VERSION ""

NS_ :

BS_:

BU_: SCM BC1 BC2 ECM PSC ABS Brakes__Drive_Axle_1 EPS IC GPS WCM VCM Seat_Control_1 ISC1 HCU IDT GMRS XM RH AUTON LHC CIM IMU BC3 IC2 EPC1 EPC2 EPC3 EPC4 BMC1 BMC2 APU2 APU1 SRVTOOL RHC RCM

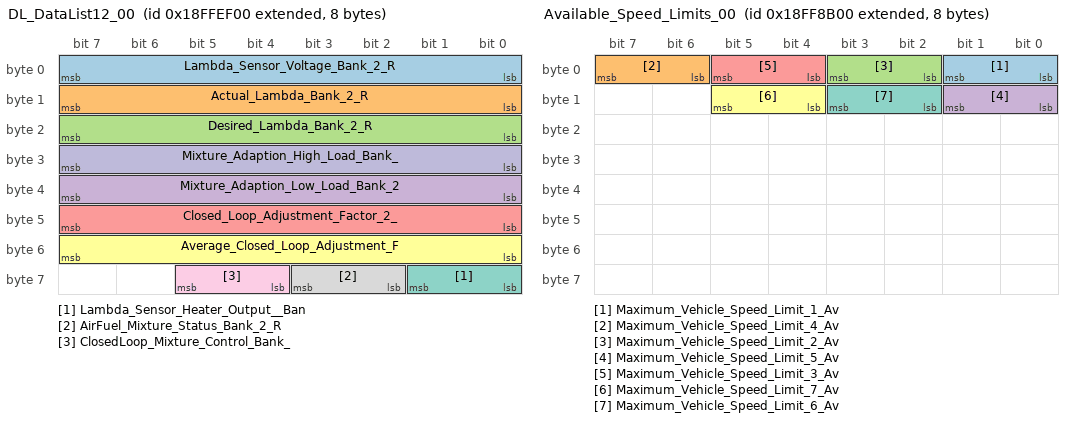
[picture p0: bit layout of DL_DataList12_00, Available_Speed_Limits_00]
BO_ 2566909696 DL_DataList12_00: 8 ECM
 SG_ Lambda_Sensor_Voltage_Bank_2_R : 0|8@1+ (0.02,0) [0|4.12] "V" Vector__XXX
 SG_ Actual_Lambda_Bank_2_R : 8|8@1+ (0.0078125,0) [0|1] "Ratio" Vector__XXX
 SG_ Desired_Lambda_Bank_2_R : 16|8@1+ (0.0078125,0) [0|1] "Ratio" Vector__XXX
 SG_ Mixture_Adaption_Low_Load_Bank_2 : 32|8@1+ (0.078,-10) [-10|28.968] "%" Vector__XXX
 SG_ Closed_Loop_Adjustment_Factor_2_ : 40|8@1+ (0.0078125,0) [0|1] "Ratio" Vector__XXX
 SG_ Average_Closed_Loop_Adjustment_F : 48|8@1+ (0.0078125,0) [0|1] "Ratio" Vector__XXX
 SG_ Lambda_Sensor_Heater_Output__Ban : 56|2@1+ (0,0) [0|-1] "state" Vector__XXX
 SG_ AirFuel_Mixture_Status_Bank_2_R : 58|2@1+ (0,0) [0|-1] "state" Vector__XXX
 SG_ ClosedLoop_Mixture_Control_Bank_ : 60|2@1+ (0,0) [0|-1] "state" Vector__XXX
 SG_ Mixture_Adaption_High_Load_Bank_ : 24|8@1+ (0.0078125,0) [0|1] "unknown" Vector__XXX

BO_ 2566884096 Available_Speed_Limits_00: 8 ECM
 SG_ Maximum_Vehicle_Speed_Limit_1_Av : 0|2@1+ (1,0) [0|3] "state" Vector__XXX
 SG_ Maximum_Vehicle_Speed_Limit_4_Av : 6|2@1+ (1,0) [0|3] "state" Vector__XXX
 SG_ Maximum_Vehicle_Speed_Limit_2_Av : 2|2@1+ (1,0) [0|3] "state" Vector__XXX
 SG_ Maximum_Vehicle_Speed_Limit_5_Av : 8|2@1+ (1,0) [0|3] "state" Vector__XXX
 SG_ Maximum_Vehicle_Speed_Limit_3_Av : 4|2@1+ (1,0) [0|3] "state" Vector__XXX
 SG_ Maximum_Vehicle_Speed_Limit_7_Av : 12|2@1+ (1,0) [0|3] "state" Vector__XXX
 SG_ Maximum_Vehicle_Speed_Limit_6_Av : 10|2@1+ (1,0) [0|3] "state" Vector__XXX

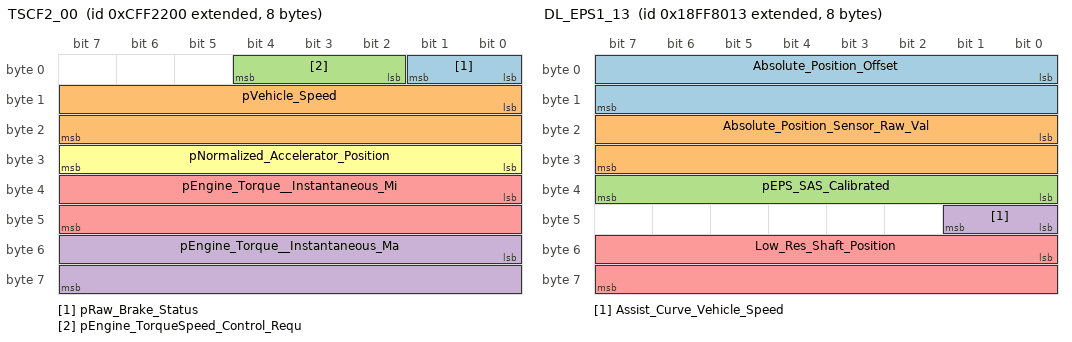
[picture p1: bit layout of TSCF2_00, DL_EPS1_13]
BO_ 2365530624 TSCF2_00: 8 ECM
 SG_ pRaw_Brake_Status : 0|2@1+ (1,0) [0|3] "state" Vector__XXX
 SG_ pVehicle_Speed : 8|16@1+ (0.00390625,0) [0|255] "km/h" Vector__XXX
 SG_ pEngine_TorqueSpeed_Control_Requ : 2|3@1+ (1,0) [0|7] "state" Vector__XXX
 SG_ pEngine_Torque__Instantaneous_Ma : 48|16@1+ (0.03125,-400) [-400|2447] "Nm" Vector__XXX
 SG_ pEngine_Torque__Instantaneous_Mi : 32|16@1+ (0.03125,-400) [-400|2447] "Nm" Vector__XXX
 SG_ pNormalized_Accelerator_Position : 24|8@1+ (0.4,0) [0|101.4] "%" Vector__XXX

BO_ 2566881811 DL_EPS2_13: 5 EPS
 SG_ EPS_Motor_Commanded_Current : 0|16@1+ (3.814697266,0) [0|249999.000024576] "A" Vector__XXX
 SG_ pEPS_Temp : 16|8@1+ (1,0) [0|255] "deg" Vector__XXX
 SG_ Factory_Absolute_Position_Offset : 24|16@1+ (0.1,-3276.5) [-3276.5|9829.1] "deg" Vector__XXX

BO_ 2566881299 DL_EPS1_13: 8 EPS
 SG_ Absolute_Position_Offset : 0|16@1+ (0.1,0) [0|6552.6] "deg" Vector__XXX
 SG_ Absolute_Position_Sensor_Raw_Val : 16|16@1+ (0.1,0) [0|6552.6] "deg" Vector__XXX
 SG_ pEPS_SAS_Calibrated : 32|8@1+ (4,0) [0|1023] "state" Vector__XXX
 SG_ Assist_Curve_Vehicle_Speed : 40|2@1+ (1,0) [0|3] "km/h" Vector__XXX
 SG_ Low_Res_Shaft_Position : 48|16@1+ (0.1,0) [0|6552.6] "deg" Vector__XXX

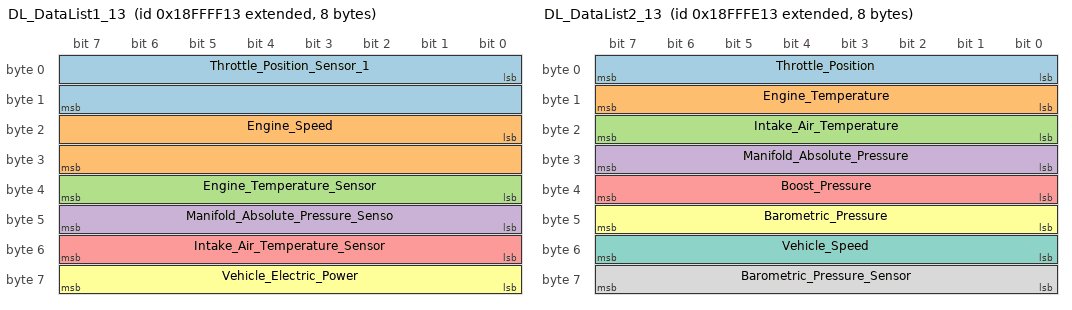
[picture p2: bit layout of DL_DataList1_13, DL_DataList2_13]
BO_ 2566913811 DL_DataList1_13: 8 EPS
 SG_ Throttle_Position_Sensor_1 : 0|16@1+ (0.01,0) [0|654.36] "V" Vector__XXX
 SG_ Engine_Speed : 16|16@1+ (1,0) [0|65535] "rpm" Vector__XXX
 SG_ Engine_Temperature_Sensor : 32|8@1+ (0.025,0) [0|5.4] "V" Vector__XXX
 SG_ Manifold_Absolute_Pressure_Senso : 40|8@1+ (0.025,0) [0|5.4] "V" Vector__XXX
 SG_ Intake_Air_Temperature_Sensor : 48|8@1+ (0.025,0) [0|5.4] "V" Vector__XXX
 SG_ Vehicle_Electric_Power : 56|8@1+ (0.1,0) [0|24.6] "V" Vector__XXX

BO_ 2566882579 DL_EPS3_13: 8 EPS
 SG_ EPS_DC_Link_Voltage : 0|16@1+ (0.001,0) [0|64.536] "V" Vector__XXX
 SG_ Phase_A_Motor_Current : 16|16@1+ (3.814697266,0) [0|249999.000024576] "A" Vector__XXX
 SG_ Phase_B_Motor_Current : 32|16@1+ (3.814697266,0) [0|249999.000024576] "A" Vector__XXX
 SG_ Phase_C_Motor_Current : 48|16@1+ (3.814697266,0) [0|249999.000024576] "A" Vector__XXX

BO_ 2566913555 DL_DataList2_13: 8 EPS
 SG_ Throttle_Position : 0|8@1+ (0.4,0) [0|101.4] "%" Vector__XXX
 SG_ Engine_Temperature : 8|8@1+ (1,0) [0|255] "deg C" Vector__XXX
 SG_ Intake_Air_Temperature : 16|8@1+ (1,0) [0|255] "deg C" Vector__XXX
 SG_ Manifold_Absolute_Pressure : 24|8@1+ (2,0) [0|511] "kPa" Vector__XXX
 SG_ Boost_Pressure : 32|8@1+ (2,0) [0|511] "kPa" Vector__XXX
 SG_ Barometric_Pressure : 40|8@1+ (0.5,0) [0|127] "kPa" Vector__XXX
 SG_ Vehicle_Speed : 48|8@1+ (1,0) [0|255] "km/h" Vector__XXX
 SG_ Barometric_Pressure_Sensor : 56|8@1+ (0.025,0) [0|5.4] "V" Vector__XXX

BO_ 2164236829 Development_PGN_3_1D: 8 WCM

BO_ 2164238109 Development_PGN_8_1D: 8 WCM

BO_ 2164237597 Development_PGN_6_1D: 8 WCM

BO_ 2164236317 Development_PGN_1_1D: 8 WCM

BO_ 2566910493 FI_FlagItems4_1D: 8 WCM
 SG_ Hazard_Switch_Input : 0|2@1+ (1,0) [0|3] "state" Vector__XXX
 SG_ LowHigh_Beam_Input : 2|2@1+ (1,0) [0|3] "state" Vector__XXX
 SG_ Fog_Light_Input : 4|2@1+ (1,0) [0|3] "state" Vector__XXX
 SG_ Horn_Input : 6|2@1+ (1,0) [0|3] "state" Vector__XXX
 SG_ High_Beam_Output : 8|2@1+ (1,0) [0|3] "state" Vector__XXX
 SG_ Low_Beam_Output : 10|2@1+ (1,0) [0|3] "state" Vector__XXX
 SG_ Left_Fog_Light_Output : 12|2@1+ (1,0) [0|3] "state" Vector__XXX
 SG_ Right_Fog_Light_Output : 14|2@1+ (1,0) [0|3] "state" Vector__XXX
 SG_ Unlock_Input : 16|2@1+ (1,0) [0|3] "state" Vector__XXX
 SG_ Lock_Input : 18|2@1+ (1,0) [0|3] "state" Vector__XXX
 SG_ Windsheild_Switch_Up_Input : 20|2@1+ (1,0) [0|3] "state" Vector__XXX
 SG_ Windsheild_Switch_Down_Input : 22|2@1+ (1,0) [0|3] "state" Vector__XXX
 SG_ Horn_Output : 24|2@1+ (1,0) [0|3] "state" Vector__XXX
 SG_ Hazard_Light_Output : 26|2@1+ (1,0) [0|3] "state" Vector__XXX
 SG_ Tail_Light_Output : 28|2@1+ (1,0) [0|3] "state" Vector__XXX
 SG_ Brake_Light_Output : 30|2@1+ (1,0) [0|3] "state" Vector__XXX
 SG_ Left_Front_Turn_Signal_Output : 32|2@1+ (1,0) [0|3] "state" Vector__XXX
 SG_ Right_Front_Turn_Signal_Output : 34|2@1+ (1,0) [0|3] "state" Vector__XXX
 SG_ Left_Rear_Turn_Signal_Output : 36|2@1+ (1,0) [0|3] "state" Vector__XXX
 SG_ Right_Rear_Turn_Signal_Output : 38|2@1+ (1,0) [0|3] "state" Vector__XXX
 SG_ Secondary_Air_Valve_Output : 40|2@1+ (1,0) [0|3] "state" Vector__XXX
 SG_ Secondary_Air_Valve_Command : 42|2@1+ (1,0) [0|3] "state" Vector__XXX
 SG_ Heated_Grip_Heat_Increase_Switch : 44|2@1+ (1,0) [0|3] "state" Vector__XXX
 SG_ Heated_Grip_Heat_Decrease_Switch : 46|2@1+ (1,0) [0|3] "state" Vector__XXX
 SG_ pOperator_Button_1 : 48|2@1+ (1,0) [0|3] "state" Vector__XXX
 SG_ pOperator_Button_2 : 50|2@1+ (1,0) [0|3] "state" Vector__XXX
 SG_ pSide_Stand_Switch : 52|2@1+ (1,0) [0|3] "state" Vector__XXX
 SG_ Coolant_Fluid_Level_Switch : 54|2@1+ (1,0) [0|3] "state" Vector__XXX
 SG_ Driveline_Momentary_Left : 56|2@1+ (1,0) [0|3] "bit" Vector__XXX
 SG_ Driveline_Momentary_Right : 58|2@1+ (1,0) [0|3] "bit" Vector__XXX
 SG_ Seatbelt_Switch : 60|2@1+ (1,0) [0|3] "bit" Vector__XXX
 SG_ Brake_Fluid_Level_Switch : 62|2@1+ (1,0) [0|3] "bit" Vector__XXX

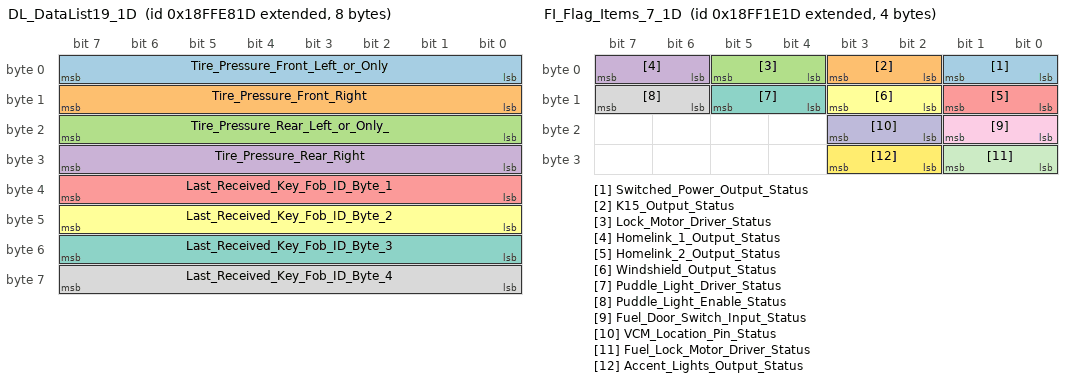
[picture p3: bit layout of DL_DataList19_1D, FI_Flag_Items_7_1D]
BO_ 2566907933 DL_DataList19_1D: 8 WCM
 SG_ Tire_Pressure_Front_Left_or_Only : 0|8@1+ (4,0) [0|1023] "kPa" Vector__XXX
 SG_ Tire_Pressure_Front_Right : 8|8@1+ (4,0) [0|1023] "kPa" Vector__XXX
 SG_ Tire_Pressure_Rear_Left_or_Only_ : 16|8@1+ (4,0) [0|1023] "kPa" Vector__XXX
 SG_ Tire_Pressure_Rear_Right : 24|8@1+ (4,0) [0|1023] "kPa" Vector__XXX
 SG_ Last_Received_Key_Fob_ID_Byte_1 : 32|8@1+ (0,0) [0|-1] "value" Vector__XXX
 SG_ Last_Received_Key_Fob_ID_Byte_2 : 40|8@1+ (1,0) [0|255] "value" Vector__XXX
 SG_ Last_Received_Key_Fob_ID_Byte_3 : 48|8@1+ (0,0) [0|-1] "value" Vector__XXX
 SG_ Last_Received_Key_Fob_ID_Byte_4 : 56|8@1+ (1,0) [0|255] "value" Vector__XXX

BO_ 2164237853 Development_PGN_7_1D: 8 WCM

BO_ 2164236573 Development_PGN_2_1D: 8 WCM

BO_ 2566907677 DL_DataList20_1D: 8 WCM
 SG_ Number_of_Discovered_Key_Fobs : 0|8@1+ (1,0) [0|255] "value" Vector__XXX
 SG_ LeanAngle : 8|8@1+ (1,0) [0|255] "deg" Vector__XXX

BO_ 2566856221 FI_Flag_Items_7_1D: 4 WCM
 SG_ Switched_Power_Output_Status : 0|2@1+ (1,0) [0|3] "state" Vector__XXX
 SG_ K15_Output_Status : 2|2@1+ (1,0) [0|3] "state" Vector__XXX
 SG_ Lock_Motor_Driver_Status : 4|2@1+ (1,0) [0|3] "state" Vector__XXX
 SG_ Homelink_1_Output_Status : 6|2@1+ (1,0) [0|3] "state" Vector__XXX
 SG_ Homelink_2_Output_Status : 8|2@1+ (1,0) [0|3] "state" Vector__XXX
 SG_ Windshield_Output_Status : 10|2@1+ (1,0) [0|3] "state" Vector__XXX
 SG_ Puddle_Light_Driver_Status : 12|2@1+ (1,0) [0|3] "state" Vector__XXX
 SG_ Puddle_Light_Enable_Status : 14|2@1+ (1,0) [0|3] "state" Vector__XXX
 SG_ Fuel_Door_Switch_Input_Status : 16|2@1+ (1,0) [0|3] "state" Vector__XXX
 SG_ VCM_Location_Pin_Status : 18|2@1+ (1,0) [0|3] "state" Vector__XXX
 SG_ Fuel_Lock_Motor_Driver_Status : 24|2@1+ (1,0) [0|3] "state" Vector__XXX
 SG_ Accent_Lights_Output_Status : 26|2@1+ (1,0) [0|3] "state" Vector__XXX

BO_ 2164237341 Development_PGN_5_1D: 8 WCM

BO_ 2164237085 Development_PGN_4_1D: 8 WCM

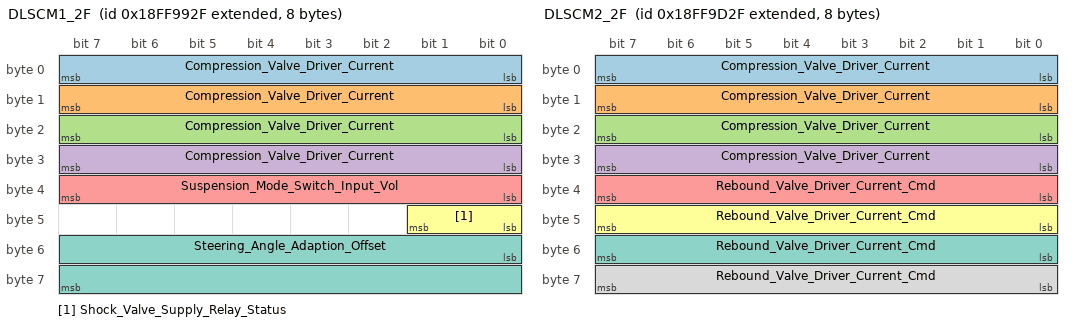
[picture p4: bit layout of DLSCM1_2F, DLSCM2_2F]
BO_ 2566887727 DLSCM1_2F: 8 SCM
 SG_ Compression_Valve_Driver_Current : 0|8@1+ (20,0) [0|5119] "mA" Vector__XXX
 SG_ Compression_Valve_Driver_Current : 8|8@1+ (20,0) [0|5119] "mA" Vector__XXX
 SG_ Compression_Valve_Driver_Current : 16|8@1+ (20,0) [0|5119] "mA" Vector__XXX
 SG_ Compression_Valve_Driver_Current : 24|8@1+ (20,0) [0|5119] "mA" Vector__XXX
 SG_ Suspension_Mode_Switch_Input_Vol : 32|8@1+ (0.1,0) [0|24.6] "V" Vector__XXX
 SG_ Shock_Valve_Supply_Relay_Status : 40|2@1+ (0,0) [0|-1] "state" Vector__XXX
 SG_ Steering_Angle_Adaption_Offset : 48|16@1+ (1,0) [0|65535] "deg" Vector__XXX

BO_ 2566888751 DLSCM2_2F: 8 SCM
 SG_ Compression_Valve_Driver_Current : 0|8@1+ (20,0) [0|5119] "mA" Vector__XXX
 SG_ Compression_Valve_Driver_Current : 8|8@1+ (20,0) [0|5119] "mA" Vector__XXX
 SG_ Compression_Valve_Driver_Current : 16|8@1+ (20,0) [0|5119] "mA" Vector__XXX
 SG_ Compression_Valve_Driver_Current : 24|8@1+ (20,0) [0|5119] "mA" Vector__XXX
 SG_ Rebound_Valve_Driver_Current_Cmd : 32|8@1+ (20,0) [0|5119] "mA" Vector__XXX
 SG_ Rebound_Valve_Driver_Current_Cmd : 40|8@1+ (20,0) [0|5119] "mA" Vector__XXX
 SG_ Rebound_Valve_Driver_Current_Cmd : 48|8@1+ (20,0) [0|5119] "mA" Vector__XXX
 SG_ Rebound_Valve_Driver_Current_Cmd : 56|8@1+ (20,0) [0|5119] "mA" Vector__XXX

BO_ 2566889007 DLSCM3_2F: 4 SCM
 SG_ Rebound_Valve_Driver_Current_fb_ : 0|8@1+ (20,0) [0|5119] "mA" Vector__XXX
 SG_ Rebound_Valve_Driver_Current_fb_ : 8|8@1+ (20,0) [0|5119] "mA" Vector__XXX
 SG_ Rebound_Valve_Driver_Current_fb_ : 16|8@1+ (20,0) [0|5119] "mA" Vector__XXX
 SG_ Rebound_Valve_Driver_Current_fb_ : 24|8@1+ (20,0) [0|5119] "mA" Vector__XXX

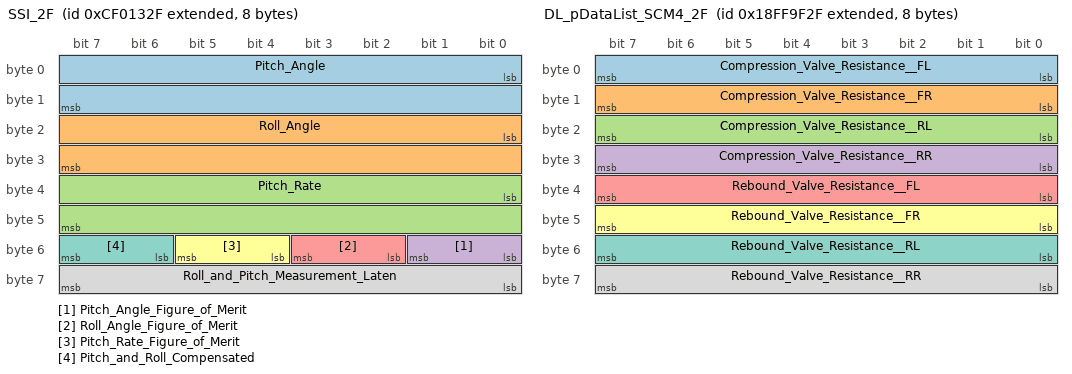
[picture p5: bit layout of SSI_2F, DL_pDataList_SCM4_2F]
BO_ 2364543791 SSI_2F: 8 SCM
 SG_ Pitch_Angle : 0|16@1+ (0.002,-64) [-64|194.072] "deg" Vector__XXX
 SG_ Roll_Angle : 16|16@1+ (0.002,-64) [-64|194.072] "deg" Vector__XXX
 SG_ Pitch_Rate : 32|16@1+ (0.002,-64) [-64|194.072] "deg/s" Vector__XXX
 SG_ Pitch_Angle_Figure_of_Merit : 48|2@1+ (1,0) [0|3] "bit" Vector__XXX
 SG_ Roll_Angle_Figure_of_Merit : 50|2@1+ (1,0) [0|3] "bit" Vector__XXX
 SG_ Pitch_Rate_Figure_of_Merit : 52|2@1+ (1,0) [0|3] "bit" Vector__XXX
 SG_ Pitch_and_Roll_Compensated : 54|2@1+ (1,0) [0|3] "bit" Vector__XXX
 SG_ Roll_and_Pitch_Measurement_Laten : 56|8@1+ (0.5,0) [0|127] "ms" Vector__XXX

BO_ 2566889263 DL_pDataList_SCM4_2F: 8 SCM
 SG_ Compression_Valve_Resistance__FL : 0|8@1+ (0.1,0) [0|24.6] "ohm" Vector__XXX
 SG_ Compression_Valve_Resistance__FR : 8|8@1+ (0.1,0) [0|24.6] "ohm" Vector__XXX
 SG_ Compression_Valve_Resistance__RL : 16|8@1+ (0.1,0) [0|24.6] "ohm" Vector__XXX
 SG_ Compression_Valve_Resistance__RR : 24|8@1+ (0.1,0) [0|24.6] "ohm" Vector__XXX
 SG_ Rebound_Valve_Resistance__FL : 32|8@1+ (0.1,0) [0|24.6] "ohm" Vector__XXX
 SG_ Rebound_Valve_Resistance__FR : 40|8@1+ (0.1,0) [0|24.6] "ohm" Vector__XXX
 SG_ Rebound_Valve_Resistance__RL : 48|8@1+ (0.1,0) [0|24.6] "ohm" Vector__XXX
 SG_ Rebound_Valve_Resistance__RR : 56|8@1+ (0.1,0) [0|24.6] "ohm" Vector__XXX

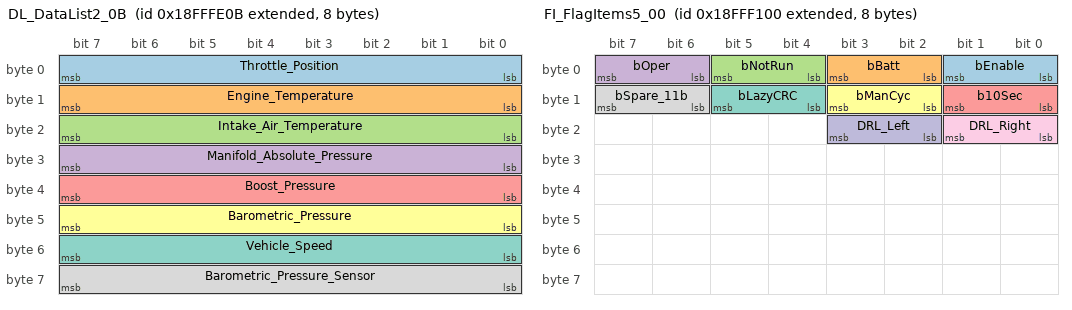
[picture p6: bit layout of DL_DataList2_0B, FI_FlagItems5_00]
BO_ 2566913547 DL_DataList2_0B: 8 ABS
 SG_ Throttle_Position : 0|8@1+ (0.4,0) [0|101.4] "%" Vector__XXX
 SG_ Engine_Temperature : 8|8@1+ (1,0) [0|255] "deg C" Vector__XXX
 SG_ Intake_Air_Temperature : 16|8@1+ (1,0) [0|255] "deg C" Vector__XXX
 SG_ Manifold_Absolute_Pressure : 24|8@1+ (2,0) [0|511] "kPa" Vector__XXX
 SG_ Boost_Pressure : 32|8@1+ (2,0) [0|511] "kPa" Vector__XXX
 SG_ Barometric_Pressure : 40|8@1+ (0.5,0) [0|127] "kPa" Vector__XXX
 SG_ Vehicle_Speed : 48|8@1+ (1,0) [0|255] "km/h" Vector__XXX
 SG_ Barometric_Pressure_Sensor : 56|8@1+ (0.025,0) [0|5.4] "V" Vector__XXX

BO_ 2566910208 FI_FlagItems5_00: 8 ECM
 SG_ bEnable : 0|2@1+ (1,0) [0|3] "bit" Vector__XXX
 SG_ bBatt : 2|2@1+ (1,0) [0|3] "bit" Vector__XXX
 SG_ bNotRun : 4|2@1+ (1,0) [0|3] "bit" Vector__XXX
 SG_ bOper : 6|2@1+ (1,0) [0|3] "bit" Vector__XXX
 SG_ b10Sec : 8|2@1+ (1,0) [0|3] "bit" Vector__XXX
 SG_ bManCyc : 10|2@1+ (1,0) [0|3] "bit" Vector__XXX
 SG_ bLazyCRC : 12|2@1+ (1,0) [0|3] "bit" Vector__XXX
 SG_ bSpare_11b : 14|2@1+ (1,0) [0|3] "value" Vector__XXX
 SG_ DRL_Right : 16|2@1+ (1,0) [0|3] "state" Vector__XXX
 SG_ DRL_Left : 18|2@1+ (1,0) [0|3] "state" Vector__XXX

BO_ 2566876695 pVF1_17: 8 IC
 SG_ pHydraulic_Oil_Temp_Status : 0|2@1+ (1,0) [0|3] "state" Vector__XXX
 SG_ pHydraulic_Oil_Pressure_Status : 2|2@1+ (1,0) [0|3] "state" Vector__XXX
 SG_ pEngine_Oil_Pressure_Status : 4|2@1+ (1,0) [0|3] "state" Vector__XXX

BO_ 2566838807 DL_Software_Ident_17: 0 IC

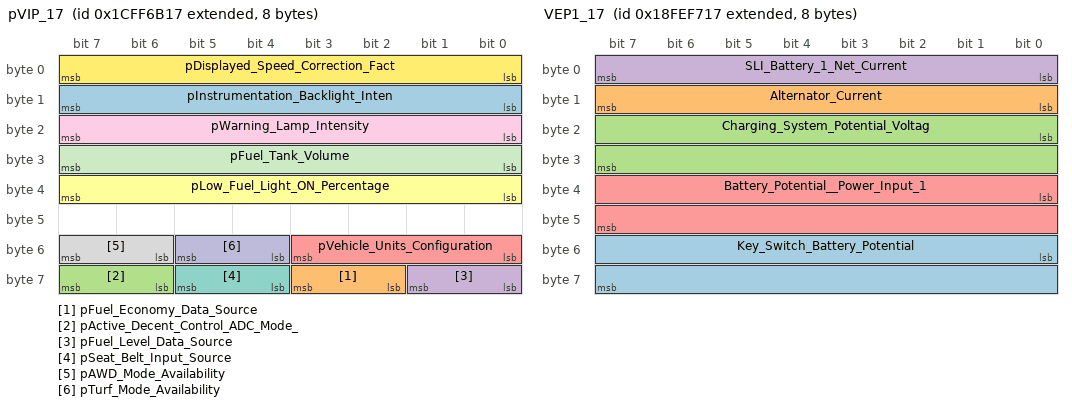
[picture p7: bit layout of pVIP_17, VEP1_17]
BO_ 2633984791 pVIP_17: 8 IC
 SG_ pInstrumentation_Backlight_Inten : 8|8@1+ (0.4,0) [0|101.4] "%" Vector__XXX
 SG_ pFuel_Economy_Data_Source : 58|2@1+ (1,0) [0|3] "state" Vector__XXX
 SG_ pActive_Decent_Control_ADC_Mode_ : 62|2@1+ (1,0) [0|3] "state" Vector__XXX
 SG_ pFuel_Level_Data_Source : 56|2@1+ (1,0) [0|3] "state" Vector__XXX
 SG_ pVehicle_Units_Configuration : 48|4@1+ (1,0) [0|15] "state" Vector__XXX
 SG_ pLow_Fuel_Light_ON_Percentage : 32|8@1+ (0.4,0) [0|101.4] "%" Vector__XXX
 SG_ pSeat_Belt_Input_Source : 60|2@1+ (1,0) [0|3] "state" Vector__XXX
 SG_ pAWD_Mode_Availability : 54|2@1+ (1,0) [0|3] "state" Vector__XXX
 SG_ pWarning_Lamp_Intensity : 16|8@1+ (0.4,0) [0|101.4] "%" Vector__XXX
 SG_ pTurf_Mode_Availability : 52|2@1+ (1,0) [0|3] "state" Vector__XXX
 SG_ pFuel_Tank_Volume : 24|8@1+ (0.5,0) [0|127] "l" Vector__XXX
 SG_ pDisplayed_Speed_Correction_Fact : 0|8@1+ (0.8,-100) [-100|303.8] "%" Vector__XXX

BO_ 2566846231 VEP1_17: 8 IC
 SG_ Key_Switch_Battery_Potential : 48|16@1+ (0.05,0) [0|3275.8] "V" Vector__XXX
 SG_ Alternator_Current : 8|8@1+ (1,0) [0|255] "A" Vector__XXX
 SG_ Charging_System_Potential_Voltag : 16|16@1+ (0.05,0) [0|3275.8] "V" Vector__XXX
 SG_ SLI_Battery_1_Net_Current : 0|8@1+ (1,-125) [-125|380] "A" Vector__XXX
 SG_ Battery_Potential__Power_Input_1 : 32|16@1+ (0.05,0) [0|3275.8] "V" Vector__XXX

BO_ 2633984577 pDSS_41: 8 ISC1
 SG_ pHeated_Grip_Enable : 48|2@1+ (1,0) [0|3] "state" Vector__XXX
 SG_ pUser_PIN_Access_Status : 26|2@1+ (1,0) [0|3] "state" Vector__XXX
 SG_ pActive_Descent_Control_ADC_Stat : 0|2@1+ (1,0) [0|3] "state" Vector__XXX
 SG_ pCruise_Control_Set_Status : 24|2@1+ (1,0) [0|3] "state" Vector__XXX
 SG_ pTether_Switch_Status : 46|2@1+ (1,0) [0|3] "state" Vector__XXX
 SG_ pHigh_Beam_Indicator_Status : 8|2@1+ (1,0) [0|3] "state" Vector__XXX
 SG_ pLow_Fuel_Indicator_Status : 10|2@1+ (1,0) [0|3] "state" Vector__XXX
 SG_ pHeated_Grips_Percentage : 16|8@1+ (0.4,0) [0|101.4] "%" Vector__XXX
 SG_ pSide_Stand_Status : 36|2@1+ (1,0) [0|3] "state" Vector__XXX
 SG_ pTurf_Mode_Requested : 28|2@1+ (1,0) [0|3] "state" Vector__XXX
 SG_ pEngine_Idle_Shutdown_Timer : 54|10@1+ (1,0) [0|1023] "state" Vector__XXX
 SG_ Operator_Not_in_Operating_Statio : 38|2@1+ (1,0) [0|3] "state" Vector__XXX
 SG_ pAWD_Mode_Requested : 32|2@1+ (1,0) [0|3] "state" Vector__XXX
 SG_ pHeated_Grips_Up_Switch_Status : 50|2@1+ (1,0) [0|3] "state" Vector__XXX
 SG_ pTreadle_Neutral_Status : 2|2@1+ (1,0) [0|3] "state" Vector__XXX
 SG_ pHeated_Grips_Down_Switch_Status : 52|2@1+ (1,0) [0|3] "state" Vector__XXX
 SG_ pPark_Brake_Indicator_Status : 40|3@1+ (1,0) [0|7] "state" Vector__XXX
 SG_ pRWD_Mode_Requested : 30|2@1+ (1,0) [0|3] "state" Vector__XXX
 SG_ pSeat_Belt_Indicator_Status : 12|3@1+ (1,0) [0|7] "state" Vector__XXX
 SG_ pSecurity_Light_Immobilizer_Stat : 6|2@1+ (1,0) [0|3] "state" Vector__XXX
 SG_ ECU_Security_Status : 43|3@1+ (1,0) [0|7] "state" Vector__XXX
 SG_ pActive_Decent_Control_ADC_Mode_ : 34|2@1+ (1,0) [0|3] "state" Vector__XXX
 SG_ pTreadle_Reverse_Status : 4|2@1+ (1,0) [0|3] "state" Vector__XXX

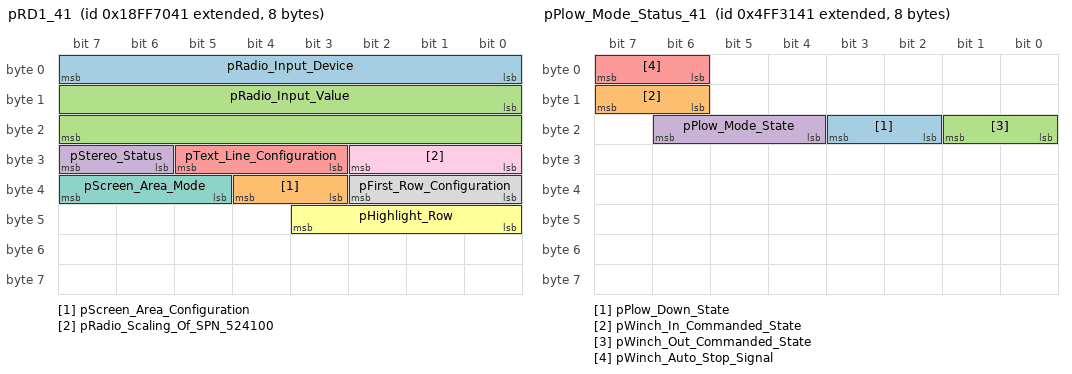
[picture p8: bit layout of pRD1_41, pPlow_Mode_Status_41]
BO_ 2566877249 pRD1_41: 8 ISC1
 SG_ pRadio_Input_Device : 0|8@1+ (1,0) [0|255] "state" Vector__XXX
 SG_ pScreen_Area_Configuration : 35|2@1+ (1,0) [0|3] "state" Vector__XXX
 SG_ pRadio_Input_Value : 8|16@1+ (1,0) [0|65535] "" Vector__XXX
 SG_ pStereo_Status : 30|2@1+ (1,0) [0|3] "state" Vector__XXX
 SG_ pText_Line_Configuration : 27|3@1+ (1,0) [0|7] "state" Vector__XXX
 SG_ pHighlight_Row : 40|4@1+ (1,0) [0|15] "state" Vector__XXX
 SG_ pScreen_Area_Mode : 37|3@1+ (1,0) [0|7] "state" Vector__XXX
 SG_ pFirst_Row_Configuration : 32|3@1+ (1,0) [0|7] "state" Vector__XXX
 SG_ pRadio_Scaling_Of_SPN_524100 : 24|3@1+ (1,0) [0|7] "state" Vector__XXX

BO_ 2566845761 AMB_41: 8 ISC1
 SG_ Ambient_Air_Temperature : 24|16@1+ (0.03125,-273) [-273|2320] "deg C" Vector__XXX
 SG_ Barometric_Pressure : 0|8@1+ (0.5,0) [0|127] "kPa" Vector__XXX
 SG_ Road_Surface_Temperature : 48|16@1+ (0.03125,-273) [-273|2320] "deg C" Vector__XXX
 SG_ Engine_Intake_1_Air_Temperature : 40|8@1+ (1,-40) [-40|295] "deg C" Vector__XXX

BO_ 2231316801 pPlow_Mode_Status_41: 8 ISC1
 SG_ pPlow_Down_State : 18|2@1+ (1,0) [0|3] "state" Vector__XXX
 SG_ pWinch_In_Commanded_State : 14|2@1+ (1,0) [0|3] "state" Vector__XXX
 SG_ pWinch_Out_Commanded_State : 16|2@1+ (1,0) [0|3] "state" Vector__XXX
 SG_ pPlow_Mode_State : 20|3@1+ (1,0) [0|7] "state" Vector__XXX
 SG_ pWinch_Auto_Stop_Signal : 6|2@1+ (1,0) [0|3] "state" Vector__XXX

BO_ 2231317569 pPlow_Mode_Status2_41: 8 ISC1
 SG_ pWinch_In_Relay_Control_Voltage : 0|1@1+ (1,0) [0|0] "V" Vector__XXX
 SG_ pWinch_Out_Relay_Control_Voltage : 16|1@1+ (1,0) [0|0] "V" Vector__XXX
 SG_ pAutostop_Signal_Voltage : 32|1@1+ (1,0) [0|0] "V" Vector__XXX

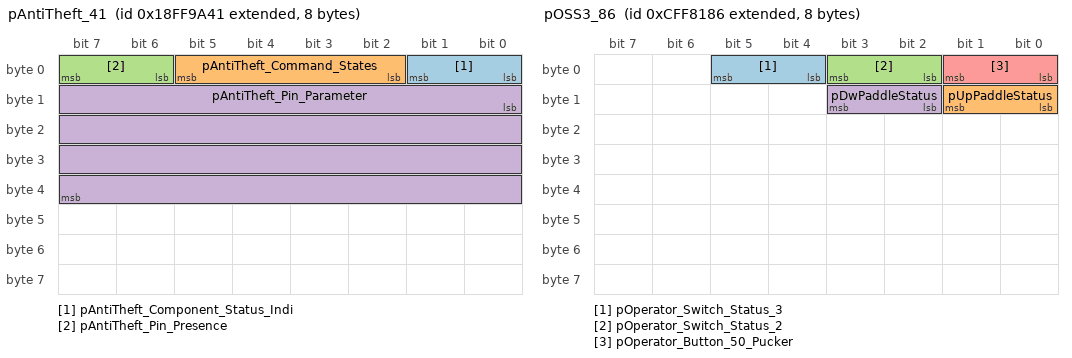
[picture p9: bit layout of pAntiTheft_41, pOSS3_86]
BO_ 2566888001 pAntiTheft_41: 8 ISC1
 SG_ pAntiTheft_Component_Status_Indi : 0|2@1+ (1,0) [0|3] "state" Vector__XXX
 SG_ pAntiTheft_Command_States : 2|4@1+ (1,0) [0|15] "state" Vector__XXX
 SG_ pAntiTheft_Pin_Presence : 6|2@1+ (1,0) [0|3] "state" Vector__XXX
 SG_ pAntiTheft_Pin_Parameter : 8|32@1+ (1,0) [0|4294967295] "ASCII" Vector__XXX

BO_ 2365555078 pOSS3_86: 8 RHC
 SG_ pOperator_Switch_Status_3 : 4|2@1+ (1,0) [0|3] "state" Vector__XXX
 SG_ pUpPaddleStatus : 8|2@1+ (1,0) [0|3] "state" Vector__XXX
 SG_ pOperator_Switch_Status_2 : 2|2@1+ (1,0) [0|3] "state" Vector__XXX
 SG_ pDwPaddleStatus : 10|2@1+ (1,0) [0|3] "state" Vector__XXX
 SG_ pOperator_Button_50_Pucker : 0|2@1+ (1,0) [0|3] "state" Vector__XXX

BO_ 2566844806 CCVS1_86: 8 RHC
 SG_ Cruise_Control_Set_Speed : 40|8@1+ (1,0) [0|255] "km/h" Vector__XXX
 SG_ Cruise_Control_Active : 24|2@1+ (1,0) [0|3] "bit" Vector__XXX
 SG_ Clutch_Switch : 30|2@1+ (1,0) [0|3] "bit" Vector__XXX
 SG_ Brake_Switch : 28|2@1+ (1,0) [0|3] "bit" Vector__XXX
 SG_ pCC_Message_Counter : 52|4@1+ (1,0) [0|15] "count" Vector__XXX
 SG_ Cruise_Control_Pause_Switch : 4|2@1+ (1,0) [0|3] "bit" Vector__XXX
 SG_ Cruise_Control_Set_Switch : 32|2@1+ (1,0) [0|3] "bit" Vector__XXX
 SG_ Two_Speed_Axle_Switch : 0|2@1+ (1,0) [0|3] "bit" Vector__XXX
 SG_ Cruise_Control_Enable_Switch : 26|2@1+ (1,0) [0|3] "bit" Vector__XXX
 SG_ pOdometer_Drive_Bit : 6|2@1+ (1,0) [0|3] "state" Vector__XXX
 SG_ pCC_Checksum : 56|8@1+ (1,0) [0|255] "" Vector__XXX
 SG_ WheelBased_Vehicle_Speed : 8|16@1+ (0.00390625,0) [0|255] "km/h" Vector__XXX
 SG_ Cruise_Control_Resume_Switch : 36|2@1+ (1,0) [0|3] "bit" Vector__XXX
 SG_ Cruise_Control_Accelerate_Switch : 38|2@1+ (1,0) [0|3] "bit" Vector__XXX
 SG_ pCruise_Enable_Status : 48|4@1+ (1,0) [0|15] "state" Vector__XXX
 SG_ Parking_Brake_Switch : 2|2@1+ (1,0) [0|3] "bit" Vector__XXX
 SG_ Cruise_Control_Coast_Decelerate_ : 34|2@1+ (1,0) [0|3] "bit" Vector__XXX

BO_ 2432656774 pOSS1_86: 8 RHC
 SG_ Key_Fob_Unlock_Button_Status : 30|2@1+ (1,0) [0|3] "state" Vector__XXX
 SG_ Homelink_2 : 44|2@1+ (1,0) [0|3] "state" Vector__XXX
 SG_ Side_Stand_Switch : 56|2@1+ (1,0) [0|3] "state" Vector__XXX
 SG_ Key_Fob_Lock_Button_Status : 32|2@1+ (1,0) [0|3] "state" Vector__XXX
 SG_ Windshield__2_Down : 50|2@1+ (1,0) [0|3] "state" Vector__XXX
 SG_ Turn__3_Cancel : 14|2@1+ (1,0) [0|3] "state" Vector__XXX
 SG_ Reverse : 40|2@1+ (1,0) [0|3] "state" Vector__XXX
 SG_ Hazard : 16|2@1+ (1,0) [0|3] "state" Vector__XXX
 SG_ Homelink_1 : 42|2@1+ (1,0) [0|3] "state" Vector__XXX
 SG_ Windshield__1_Up : 48|2@1+ (1,0) [0|3] "state" Vector__XXX
 SG_ Front_Brake_Switch : 52|2@1+ (1,0) [0|3] "state" Vector__XXX
 SG_ Instrument_Cluster_Control__2 : 2|2@1+ (1,0) [0|3] "state" Vector__XXX
 SG_ Chassis_Unlock_Button_Status : 34|2@1+ (1,0) [0|3] "state" Vector__XXX
 SG_ Power_Button : 58|2@1+ (1,0) [0|3] "state" Vector__XXX
 SG_ RunStop_Switch : 38|2@1+ (1,0) [0|3] "state" Vector__XXX
 SG_ Headlamp__2_High : 6|2@1+ (1,0) [0|3] "state" Vector__XXX
 SG_ Instrument_Cluster_Control__1 : 0|2@1+ (1,0) [0|3] "state" Vector__XXX
 SG_ Clutch_Switch : 54|2@1+ (1,0) [0|3] "state" Vector__XXX
 SG_ Start : 26|2@1+ (1,0) [0|3] "state" Vector__XXX
 SG_ Headlamp__3_Driving : 8|2@1+ (1,0) [0|3] "state" Vector__XXX
 SG_ Cruise__2_Set : 20|2@1+ (1,0) [0|3] "state" Vector__XXX
 SG_ Windshield_Wiper : 36|2@1+ (1,0) [0|3] "state" Vector__XXX
 SG_ Fog : 28|2@1+ (1,0) [0|3] "state" Vector__XXX
 SG_ Cruise__3_Accel : 22|2@1+ (1,0) [0|3] "state" Vector__XXX
 SG_ Horn : 24|2@1+ (1,0) [0|3] "state" Vector__XXX
 SG_ Turn__2_Right : 12|2@1+ (1,0) [0|3] "state" Vector__XXX
 SG_ Cruise__1_On : 18|2@1+ (1,0) [0|3] "state" Vector__XXX
 SG_ Turn__1_Left : 10|2@1+ (1,0) [0|3] "state" Vector__XXX
 SG_ Throttle_Safety_Switch__1 : 46|2@1+ (1,0) [0|3] "state" Vector__XXX
 SG_ Headlamp__1_Low : 4|2@1+ (1,0) [0|3] "state" Vector__XXX
 SG_ Chassis_Lock_Switch_Status : 62|2@1+ (1,0) [0|3] "unknown" Vector__XXX
 SG_ Fuel_Door_Unlock_Button_Status : 60|2@1+ (1,0) [0|3] "state" Vector__XXX

BO_ 2566877830 pVT1_86: 8 RHC
 SG_ pRight_Hand_Grip_Temperature : 8|8@1+ (1,-40) [-40|295] "deg C" Vector__XXX
 SG_ pDriver_Seat_Temperature : 16|8@1+ (1,-40) [-40|295] "deg C" Vector__XXX
 SG_ pPassenger_Seat_Temperature : 24|8@1+ (1,-40) [-40|295] "deg C" Vector__XXX
 SG_ pLeft_Hand_Grip_Temperature : 0|8@1+ (1,-40) [-40|295] "deg C" Vector__XXX

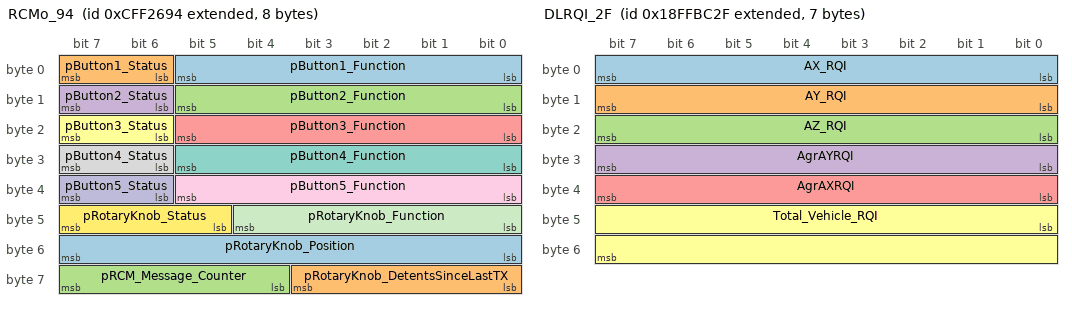
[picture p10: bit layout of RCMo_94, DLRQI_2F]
BO_ 2365531796 RCMo_94: 8 RCM
 SG_ pButton1_Function : 0|6@1+ (1,0) [0|63] "selection" Vector__XXX
 SG_ pButton1_Status : 6|2@1+ (1,0) [0|3] "bit-mapped" Vector__XXX
 SG_ pButton2_Function : 8|6@1+ (1,0) [0|63] "selection" Vector__XXX
 SG_ pButton2_Status : 14|2@1+ (1,0) [0|3] "bit-mapped" Vector__XXX
 SG_ pButton3_Function : 16|6@1+ (1,0) [0|63] "selection" Vector__XXX
 SG_ pButton3_Status : 22|2@1+ (1,0) [0|3] "bit-mapped" Vector__XXX
 SG_ pButton4_Function : 24|6@1+ (1,0) [0|63] "selection" Vector__XXX
 SG_ pButton4_Status : 30|2@1+ (1,0) [0|3] "bit-mapped" Vector__XXX
 SG_ pButton5_Function : 32|6@1+ (1,0) [0|63] "selection" Vector__XXX
 SG_ pButton5_Status : 38|2@1+ (1,0) [0|3] "bit-mapped" Vector__XXX
 SG_ pRotaryKnob_Function : 40|5@1+ (1,0) [0|31] "selection" Vector__XXX
 SG_ pRotaryKnob_Status : 45|3@1+ (1,0) [0|7] "bit-mapped" Vector__XXX
 SG_ pRotaryKnob_Position : 48|8@1+ (1.44,0) [0|367.64] "deg" Vector__XXX
 SG_ pRotaryKnob_DetentsSinceLastTX : 56|4@1+ (1,0) [0|15] "count" Vector__XXX
 SG_ pRCM_Message_Counter : 60|4@1+ (1,0) [0|15] "count" Vector__XXX

BO_ 2566896687 DLRQI_2F: 7 SCM
 SG_ AX_RQI : 0|8@1+ (0,0) [0|-1] "unknown" Vector__XXX
 SG_ AY_RQI : 8|8@1+ (0,0) [0|-1] "unknown" Vector__XXX
 SG_ AZ_RQI : 16|8@1+ (0,0) [0|-1] "unknown" Vector__XXX
 SG_ AgrAYRQI : 24|8@1+ (0,0) [0|-1] "unknown" Vector__XXX
 SG_ AgrAXRQI : 32|8@1+ (0,0) [0|-1] "unknown" Vector__XXX
 SG_ Total_Vehicle_RQI : 40|16@1+ (0,0) [0|-1] "unknown" Vector__XXX

BO_ 2365531155 pVMC_13: 8 EPS
 SG_ pEPSReqMod : 8|8@1+ (1,0) [0|255] "state" Vector__XXX

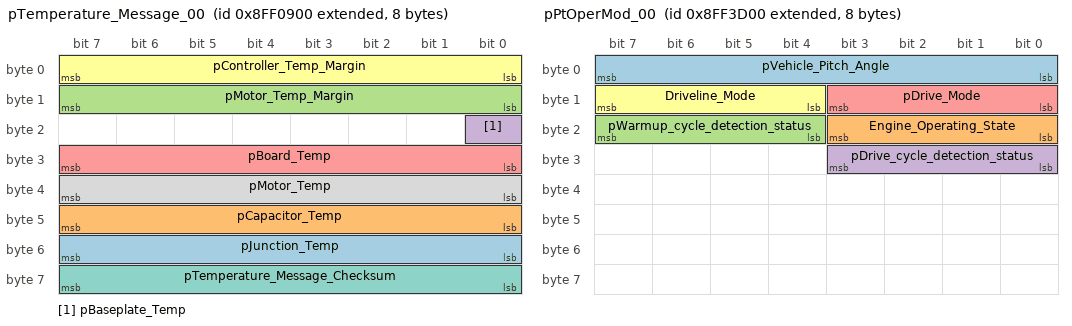
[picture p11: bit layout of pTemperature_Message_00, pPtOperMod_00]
BO_ 2298415360 pTemperature_Message_00: 8 ECM
 SG_ pJunction_Temp : 48|8@1+ (1,-40) [-40|295] "deg C" Vector__XXX
 SG_ pCapacitor_Temp : 40|8@1+ (1,-40) [-40|295] "deg C" Vector__XXX
 SG_ pMotor_Temp_Margin : 8|8@1+ (1,0) [0|255] "deg C" Vector__XXX
 SG_ pBaseplate_Temp : 16|1@1+ (1,-40) [-40|40] "deg C" Vector__XXX
 SG_ pBoard_Temp : 24|8@1+ (1,-40) [-40|295] "deg C" Vector__XXX
 SG_ pController_Temp_Margin : 0|8@1+ (1,0) [0|255] "deg C" Vector__XXX
 SG_ pTemperature_Message_Checksum : 56|8@1+ (1,0) [0|255] "" Vector__XXX
 SG_ pMotor_Temp : 32|8@1+ (1,-40) [-40|295] "deg C" Vector__XXX

BO_ 2365525760 pEnergy_Message_00: 8 ECM
 SG_ pSOC : 0|8@1+ (0.5,0) [0|127] "%" Vector__XXX
 SG_ pAvailable_Wh : 8|16@1+ (4,0) [0|262143] "kWh" Vector__XXX
 SG_ pWh_in_Since_key_on : 24|32@1+ (1,-131.072) [-131.072|4294967426.072] "Watt-hour" Vector__XXX
 SG_ pEnergy_Message_Checksum : 56|8@1+ (1,0) [0|255] "" Vector__XXX

BO_ 2298428672 pPtOperMod_00: 8 ECM
 SG_ pVehicle_Pitch_Angle : 0|8@1+ (1,-125) [-125|380] "deg" Vector__XXX
 SG_ Engine_Operating_State : 16|4@1+ (1,0) [0|15] "bit" Vector__XXX
 SG_ pWarmup_cycle_detection_status : 20|4@1+ (1,0) [0|15] "" Vector__XXX
 SG_ pDrive_cycle_detection_status : 24|4@1+ (1,0) [0|15] "" Vector__XXX
 SG_ pDrive_Mode : 8|4@1+ (1,0) [0|15] "" Vector__XXX
 SG_ Driveline_Mode : 12|4@1+ (1,0) [0|15] "state" Vector__XXX

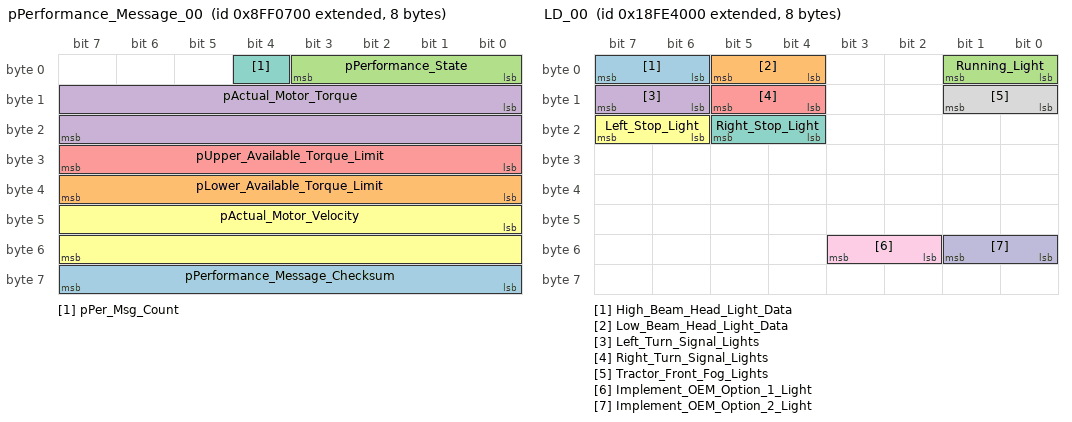
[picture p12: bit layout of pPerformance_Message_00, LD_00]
BO_ 2298414848 pPerformance_Message_00: 8 ECM
 SG_ pPerformance_Message_Checksum : 56|8@1+ (1,0) [0|255] "" Vector__XXX
 SG_ pLower_Available_Torque_Limit : 32|8@1+ (2.5,-312.5) [-312.5|951.5] "Nm" Vector__XXX
 SG_ pPerformance_State : 0|4@1+ (1,0) [0|15] "state" Vector__XXX
 SG_ pActual_Motor_Torque : 8|16@1+ (0.1,-3276.8) [-3276.8|9829.4] "Nm" Vector__XXX
 SG_ pUpper_Available_Torque_Limit : 24|8@1+ (2.5,-312.5) [-312.5|951.5] "Nm" Vector__XXX
 SG_ pActual_Motor_Velocity : 40|16@1+ (1,-32768) [-32768|98303] "rpm" Vector__XXX
 SG_ pPer_Msg_Count : 4|1@1+ (1,0) [0|0] "unknown" Vector__XXX

BO_ 2365525504 pBMC_Power_Message_00: 8 ECM
 SG_ pPack_Voltage : 16|16@1+ (0.05,0) [0|3275.8] "V" Vector__XXX
 SG_ pDischarge_Limit : 40|12@1+ (0.5,0) [0|2047] "A" Vector__XXX
 SG_ pPack_Current : 0|16@1+ (0.05,-1600) [-1600|4875.8] "A" Vector__XXX
 SG_ pBMC_Power_Message_Checksum : 56|8@1+ (1,0) [0|255] "" Vector__XXX
 SG_ pCharge_Limit : 44|12@1+ (0.5,0) [0|2047] "A" Vector__XXX

BO_ 2566799360 LD_00: 8 ECM
 SG_ High_Beam_Head_Light_Data : 6|2@1+ (1,0) [0|3] "bit" Vector__XXX
 SG_ Low_Beam_Head_Light_Data : 4|2@1+ (1,0) [0|3] "bit" Vector__XXX
 SG_ Running_Light : 0|2@1+ (1,0) [0|3] "bit" Vector__XXX
 SG_ Left_Turn_Signal_Lights : 14|2@1+ (1,0) [0|3] "bit" Vector__XXX
 SG_ Right_Turn_Signal_Lights : 12|2@1+ (1,0) [0|3] "bit" Vector__XXX
 SG_ Left_Stop_Light : 22|2@1+ (1,0) [0|3] "bit" Vector__XXX
 SG_ Right_Stop_Light : 20|2@1+ (1,0) [0|3] "bit" Vector__XXX
 SG_ Tractor_Front_Fog_Lights : 8|2@1+ (1,0) [0|3] "bit" Vector__XXX
 SG_ Implement_OEM_Option_1_Light : 50|2@1+ (1,0) [0|3] "bit" Vector__XXX
 SG_ Implement_OEM_Option_2_Light : 48|2@1+ (1,0) [0|3] "bit" Vector__XXX

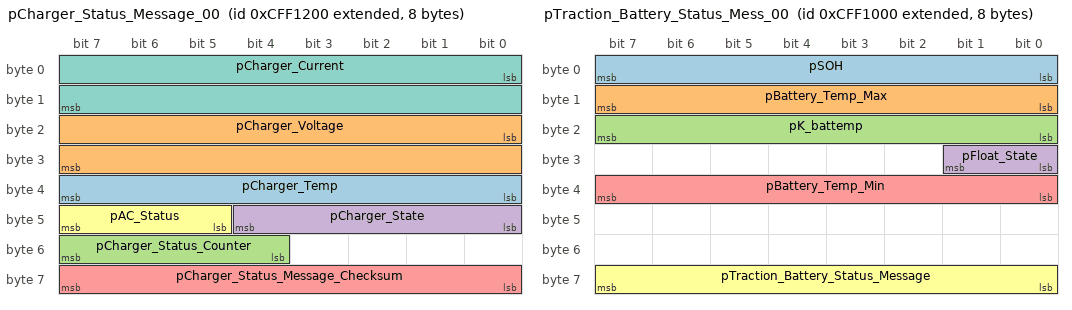
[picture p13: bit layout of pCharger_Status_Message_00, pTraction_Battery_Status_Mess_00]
BO_ 2365526528 pCharger_Status_Message_00: 8 ECM
 SG_ pCharger_Temp : 32|8@1+ (1,-40) [-40|295] "deg C" Vector__XXX
 SG_ pCharger_Voltage : 16|16@1+ (0.05,0) [0|3275.8] "V" Vector__XXX
 SG_ pCharger_Status_Counter : 52|4@1+ (1,0) [0|15] "count" Vector__XXX
 SG_ pCharger_State : 40|5@1+ (1,0) [0|31] "state" Vector__XXX
 SG_ pCharger_Status_Message_Checksum : 56|8@1+ (1,0) [0|255] "" Vector__XXX
 SG_ pAC_Status : 45|3@1+ (1,0) [0|7] "state" Vector__XXX
 SG_ pCharger_Current : 0|16@1+ (0.05,-1600) [-1600|4875.8] "A" Vector__XXX

BO_ 2365526016 pTraction_Battery_Status_Mess_00: 8 ECM
 SG_ pSOH : 0|8@1+ (0.5,0) [0|127] "%" Vector__XXX
 SG_ pBattery_Temp_Max : 8|8@1+ (1,-40) [-40|295] "deg C" Vector__XXX
 SG_ pK_battemp : 16|8@1+ (0.5,0) [0|127] "%" Vector__XXX
 SG_ pFloat_State : 24|2@1+ (1,0) [0|3] "state" Vector__XXX
 SG_ pBattery_Temp_Min : 32|8@1+ (1,-40) [-40|295] "deg C" Vector__XXX
 SG_ pTraction_Battery_Status_Message : 56|8@1+ (1,0) [0|255] "" Vector__XXX

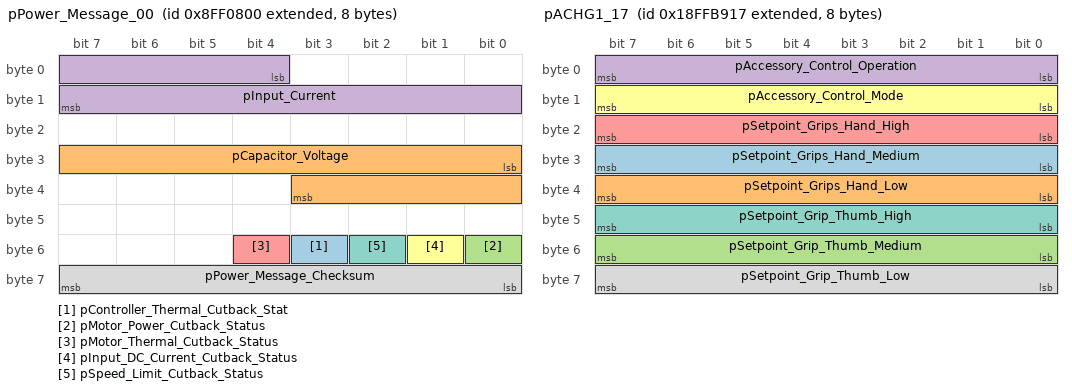
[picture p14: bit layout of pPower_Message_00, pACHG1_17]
BO_ 2298415104 pPower_Message_00: 8 ECM
 SG_ pController_Thermal_Cutback_Stat : 51|1@1+ (1,0) [0|1] "state" Vector__XXX
 SG_ pCapacitor_Voltage : 24|12@1+ (1,0) [0|4095] "V" Vector__XXX
 SG_ pMotor_Power_Cutback_Status : 48|1@1+ (1,0) [0|1] "state" Vector__XXX
 SG_ pInput_Current : 4|12@1+ (1,-2048) [-2048|6143] "A" Vector__XXX
 SG_ pMotor_Thermal_Cutback_Status : 52|1@1+ (1,0) [0|1] "state" Vector__XXX
 SG_ pInput_DC_Current_Cutback_Status : 49|1@1+ (1,0) [0|1] "state" Vector__XXX
 SG_ pSpeed_Limit_Cutback_Status : 50|1@1+ (1,0) [0|1] "state" Vector__XXX
 SG_ pPower_Message_Checksum : 56|8@1+ (1,0) [0|255] "" Vector__XXX

BO_ 2566895895 pACHG1_17: 8 IC
 SG_ pSetpoint_Grips_Hand_Medium : 24|8@1+ (1,0) [0|255] "deg C" Vector__XXX
 SG_ pSetpoint_Grips_Hand_Low : 32|8@1+ (1,0) [0|255] "deg C" Vector__XXX
 SG_ pSetpoint_Grip_Thumb_Medium : 48|8@1+ (1,0) [0|255] "deg C" Vector__XXX
 SG_ pAccessory_Control_Operation : 0|8@1+ (1,0) [0|255] "state" Vector__XXX
 SG_ pSetpoint_Grips_Hand_High : 16|8@1+ (1,0) [0|255] "deg C" Vector__XXX
 SG_ pAccessory_Control_Mode : 8|8@1+ (1,0) [0|255] "state" Vector__XXX
 SG_ pSetpoint_Grip_Thumb_High : 40|8@1+ (1,0) [0|255] "deg C" Vector__XXX
 SG_ pSetpoint_Grip_Thumb_Low : 56|8@1+ (1,0) [0|255] "deg C" Vector__XXX

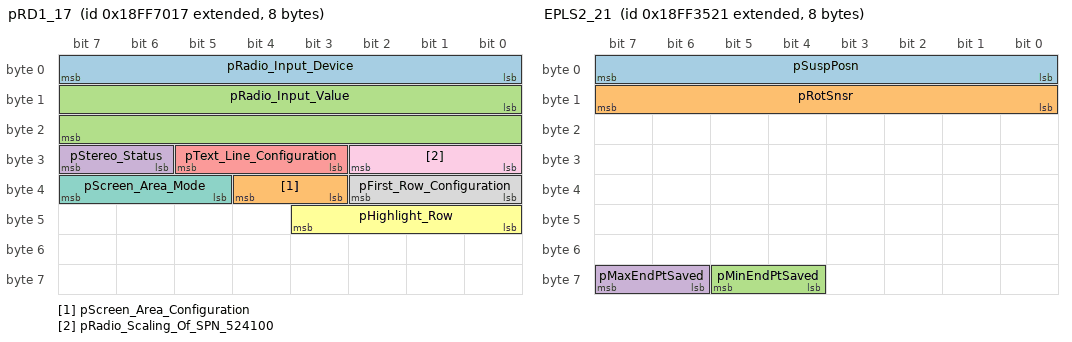
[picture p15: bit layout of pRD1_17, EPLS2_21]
BO_ 2566877207 pRD1_17: 8 IC
 SG_ pRadio_Input_Device : 0|8@1+ (1,0) [0|255] "state" Vector__XXX
 SG_ pScreen_Area_Configuration : 35|2@1+ (1,0) [0|3] "state" Vector__XXX
 SG_ pRadio_Input_Value : 8|16@1+ (1,0) [0|65535] "" Vector__XXX
 SG_ pStereo_Status : 30|2@1+ (1,0) [0|3] "state" Vector__XXX
 SG_ pText_Line_Configuration : 27|3@1+ (1,0) [0|7] "state" Vector__XXX
 SG_ pHighlight_Row : 40|4@1+ (1,0) [0|15] "state" Vector__XXX
 SG_ pScreen_Area_Mode : 37|3@1+ (1,0) [0|7] "state" Vector__XXX
 SG_ pFirst_Row_Configuration : 32|3@1+ (1,0) [0|7] "state" Vector__XXX
 SG_ pRadio_Scaling_Of_SPN_524100 : 24|3@1+ (1,0) [0|7] "state" Vector__XXX

BO_ 2633984535 pDSS_17: 8 IC
 SG_ pHeated_Grip_Enable : 48|2@1+ (1,0) [0|3] "state" Vector__XXX
 SG_ pUser_PIN_Access_Status : 26|2@1+ (1,0) [0|3] "state" Vector__XXX
 SG_ pActive_Descent_Control_ADC_Stat : 0|2@1+ (1,0) [0|3] "state" Vector__XXX
 SG_ pCruise_Control_Set_Status : 24|2@1+ (1,0) [0|3] "state" Vector__XXX
 SG_ pTether_Switch_Status : 46|2@1+ (1,0) [0|3] "state" Vector__XXX
 SG_ pHigh_Beam_Indicator_Status : 8|2@1+ (1,0) [0|3] "state" Vector__XXX
 SG_ pLow_Fuel_Indicator_Status : 10|2@1+ (1,0) [0|3] "state" Vector__XXX
 SG_ pHeated_Grips_Percentage : 16|8@1+ (0.4,0) [0|101.4] "%" Vector__XXX
 SG_ pSide_Stand_Status : 36|2@1+ (1,0) [0|3] "state" Vector__XXX
 SG_ pTurf_Mode_Requested : 28|2@1+ (1,0) [0|3] "state" Vector__XXX
 SG_ pEngine_Idle_Shutdown_Timer : 54|10@1+ (1,0) [0|1023] "state" Vector__XXX
 SG_ Operator_Not_in_Operating_Statio : 38|2@1+ (1,0) [0|3] "state" Vector__XXX
 SG_ pAWD_Mode_Requested : 32|2@1+ (1,0) [0|3] "state" Vector__XXX
 SG_ pHeated_Grips_Up_Switch_Status : 50|2@1+ (1,0) [0|3] "state" Vector__XXX
 SG_ pTreadle_Neutral_Status : 2|2@1+ (1,0) [0|3] "state" Vector__XXX
 SG_ pHeated_Grips_Down_Switch_Status : 52|2@1+ (1,0) [0|3] "state" Vector__XXX
 SG_ pPark_Brake_Indicator_Status : 40|3@1+ (1,0) [0|7] "state" Vector__XXX
 SG_ pRWD_Mode_Requested : 30|2@1+ (1,0) [0|3] "state" Vector__XXX
 SG_ pSeat_Belt_Indicator_Status : 12|3@1+ (1,0) [0|7] "state" Vector__XXX
 SG_ pSecurity_Light_Immobilizer_Stat : 6|2@1+ (1,0) [0|3] "state" Vector__XXX
 SG_ ECU_Security_Status : 43|3@1+ (1,0) [0|7] "state" Vector__XXX
 SG_ pActive_Decent_Control_ADC_Mode_ : 34|2@1+ (1,0) [0|3] "state" Vector__XXX
 SG_ pTreadle_Reverse_Status : 4|2@1+ (1,0) [0|3] "state" Vector__XXX

BO_ 2566875159 pFuelTyp_17: 8 IC
 SG_ pFuel_Type_Selected : 0|4@1+ (1,0) [0|15] "state" Vector__XXX
 SG_ pFuel_Type_Sensor : 8|8@1+ (0.4,0) [0|101.4] "%" Vector__XXX

BO_ 2566862113 EPLS2_21: 8 BC1
 SG_ pSuspPosn : 0|8@1+ (0.1,0) [0|24.6] "turns" Vector__XXX
 SG_ pRotSnsr : 8|8@1+ (0.1,0) [0|24.6] "V" Vector__XXX
 SG_ pMinEndPtSaved : 60|2@1+ (1,0) [0|3] "selection" Vector__XXX
 SG_ pMaxEndPtSaved : 62|2@1+ (1,0) [0|3] "selection" Vector__XXX

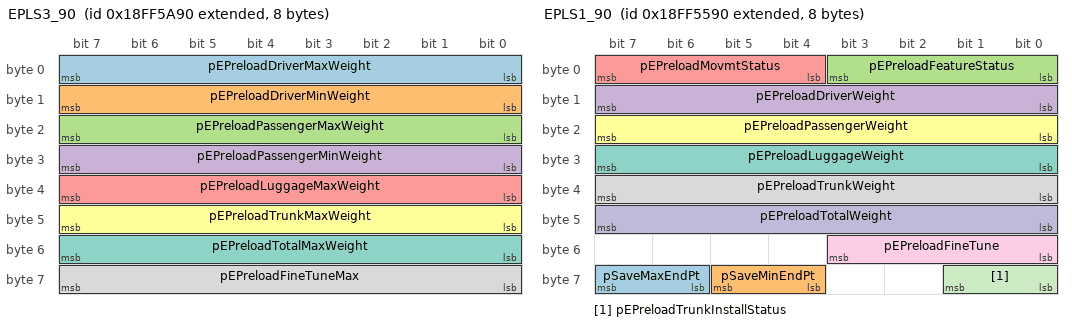
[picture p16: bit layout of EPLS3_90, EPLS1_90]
BO_ 2566871696 EPLS3_90: 8 BC2
 SG_ pEPreloadDriverMaxWeight : 0|8@1+ (1,0) [0|255] "kg" Vector__XXX
 SG_ pEPreloadDriverMinWeight : 8|8@1+ (1,0) [0|255] "kg" Vector__XXX
 SG_ pEPreloadPassengerMaxWeight : 16|8@1+ (1,0) [0|255] "kg" Vector__XXX
 SG_ pEPreloadPassengerMinWeight : 24|8@1+ (1,0) [0|255] "kg" Vector__XXX
 SG_ pEPreloadLuggageMaxWeight : 32|8@1+ (1,0) [0|255] "kg" Vector__XXX
 SG_ pEPreloadTrunkMaxWeight : 40|8@1+ (1,0) [0|255] "kg" Vector__XXX
 SG_ pEPreloadTotalMaxWeight : 48|8@1+ (1,0) [0|255] "kg" Vector__XXX
 SG_ pEPreloadFineTuneMax : 56|8@1+ (1,0) [0|255] "turns" Vector__XXX

BO_ 2566870416 EPLS1_90: 8 BC2
 SG_ pSaveMaxEndPt : 62|2@1+ (1,0) [0|3] "selection" Vector__XXX
 SG_ pSaveMinEndPt : 60|2@1+ (1,0) [0|3] "selection" Vector__XXX
 SG_ pEPreloadFeatureStatus : 0|4@1+ (1,0) [0|15] "value" Vector__XXX
 SG_ pEPreloadDriverWeight : 8|8@1+ (1,0) [0|255] "kg" Vector__XXX
 SG_ pEPreloadMovmtStatus : 4|4@1+ (1,0) [0|15] "selection" Vector__XXX
 SG_ pEPreloadPassengerWeight : 16|8@1+ (1,0) [0|255] "kg" Vector__XXX
 SG_ pEPreloadLuggageWeight : 24|8@1+ (1,0) [0|255] "kg" Vector__XXX
 SG_ pEPreloadTrunkWeight : 32|8@1+ (1,0) [0|255] "kg" Vector__XXX
 SG_ pEPreloadFineTune : 48|4@1+ (1,-6) [-6|21] "turns" Vector__XXX
 SG_ pEPreloadTotalWeight : 40|8@1+ (1,0) [0|255] "kg" Vector__XXX
 SG_ pEPreloadTrunkInstallStatus : 56|2@1+ (1,0) [0|3] "selection" Vector__XXX

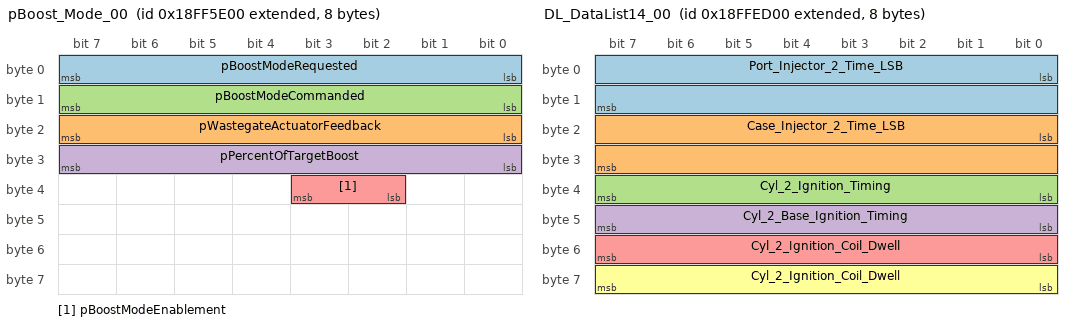
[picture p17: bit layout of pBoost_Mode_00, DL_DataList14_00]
BO_ 2566872576 pBoost_Mode_00: 8 ECM
 SG_ pBoostModeRequested : 0|8@1+ (1,0) [0|255] "state" Vector__XXX
 SG_ pWastegateActuatorFeedback : 16|8@1+ (0.4,0) [0|101.4] "%" Vector__XXX
 SG_ pBoostModeCommanded : 8|8@1+ (1,0) [0|255] "state" Vector__XXX
 SG_ pPercentOfTargetBoost : 24|8@1+ (0.4,0) [0|101.4] "%" Vector__XXX
 SG_ pBoostModeEnablement : 34|2@1+ (1,0) [0|3] "state" Vector__XXX

BO_ 2566872320 pEngStat_00: 8 ECM
 SG_ Engine_Break_In : 0|8@1+ (0.4,0) [0|101.4] "%" Vector__XXX

BO_ 2566909184 DL_DataList14_00: 8 ECM
 SG_ Port_Injector_2_Time_LSB : 0|16@1+ (1,0) [0|65535] "us" Vector__XXX
 SG_ Case_Injector_2_Time_LSB : 16|16@1+ (1,0) [0|65535] "us" Vector__XXX
 SG_ Cyl_2_Ignition_Timing : 32|8@1+ (1,0) [0|255] "deg" Vector__XXX
 SG_ Cyl_2_Base_Ignition_Timing : 40|8@1+ (1,0) [0|255] "deg" Vector__XXX
 SG_ Cyl_2_Ignition_Coil_Dwell : 48|8@1+ (1,0) [0|255] "us" Vector__XXX
 SG_ Cyl_2_Ignition_Coil_Dwell : 56|8@1+ (1,0) [0|255] "us" Vector__XXX

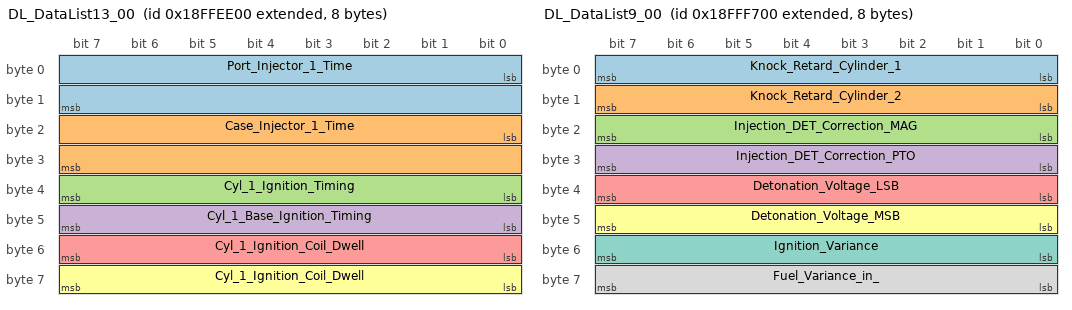
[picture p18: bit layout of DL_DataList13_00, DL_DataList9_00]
BO_ 2566909440 DL_DataList13_00: 8 ECM
 SG_ Port_Injector_1_Time : 0|16@1+ (1,0) [0|65535] "us" Vector__XXX
 SG_ Case_Injector_1_Time : 16|16@1+ (1,0) [0|65535] "us" Vector__XXX
 SG_ Cyl_1_Ignition_Timing : 32|8@1+ (1,0) [0|255] "deg" Vector__XXX
 SG_ Cyl_1_Base_Ignition_Timing : 40|8@1+ (1,0) [0|255] "deg" Vector__XXX
 SG_ Cyl_1_Ignition_Coil_Dwell : 48|8@1+ (1,0) [0|255] "us" Vector__XXX
 SG_ Cyl_1_Ignition_Coil_Dwell : 56|8@1+ (1,0) [0|255] "us" Vector__XXX

BO_ 2566900992 DL_Datalist_00: 8 ECM
 SG_ EV_Learn_Up_Position : 0|16@1+ (0.01,0) [0|654.36] "V" Vector__XXX
 SG_ EV_Learn_Down_Position : 16|16@1+ (0.01,0) [0|654.36] "V" Vector__XXX
 SG_ Auxillary_Injector_PW_MAG : 32|16@1+ (1,0) [0|65535] "us" Vector__XXX
 SG_ Auxillary_Injector_PW_PTO : 48|16@1+ (1,0) [0|65535] "us" Vector__XXX

BO_ 2566905600 DL_Engine_Info_00: 8 ECM
 SG_ ECU_Power_Input_1 : 0|8@1+ (0.1,0) [0|24.6] "V" Vector__XXX
 SG_ ECU_Power_Input_2 : 8|8@1+ (0.1,0) [0|24.6] "V" Vector__XXX
 SG_ ECU_Power_Input_3 : 16|8@1+ (0.1,0) [0|24.6] "V" Vector__XXX
 SG_ Mixture_Adaption_High_Load_Bank_ : 16|8@1+ (0.0078125,0) [0|1] "unknown" Vector__XXX
 SG_ Tire_Pressure_Spare : 16|8@1+ (4,0) [0|1023] "kPa" Vector__XXX
 SG_ AirFuel_Mixture_Status_Bank_1_F : 16|2@1+ (0,0) [0|-1] "state" Vector__XXX
 SG_ EGT_2 : 24|16@1+ (1,0) [0|65535] "deg C" Vector__XXX
 SG_ AlphaN_Output_Fuel_Flow : 40|16@1+ (0.05,0) [0|3275.8] "l/h" Vector__XXX
 SG_ Fuel_Variance__DialBox : 56|8@1+ (1,0) [0|255] "%" Vector__XXX

BO_ 2566911744 DL_DataList9_00: 8 ECM
 SG_ Knock_Retard_Cylinder_1 : 0|8@1+ (1,0) [0|255] "deg" Vector__XXX
 SG_ Knock_Retard_Cylinder_2 : 8|8@1+ (1,0) [0|255] "deg" Vector__XXX
 SG_ Injection_DET_Correction_MAG : 16|8@1+ (0.1,0) [0|24.6] "%" Vector__XXX
 SG_ Injection_DET_Correction_PTO : 24|8@1+ (0.1,0) [0|24.6] "%" Vector__XXX
 SG_ Detonation_Voltage_LSB : 32|8@1+ (0.025,0) [0|5.4] "V" Vector__XXX
 SG_ Detonation_Voltage_MSB : 40|8@1+ (0.025,0) [0|5.4] "V" Vector__XXX
 SG_ Ignition_Variance : 48|8@1+ (0.2,0) [0|50.2] "deg" Vector__XXX
 SG_ Fuel_Variance_in_ : 56|8@1+ (1,0) [0|255] "%" Vector__XXX

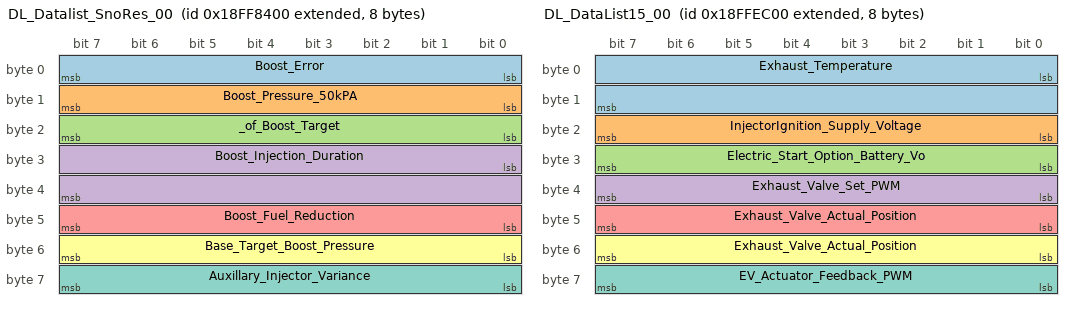
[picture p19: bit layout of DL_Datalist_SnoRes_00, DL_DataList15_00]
BO_ 2566882304 DL_Datalist_SnoRes_00: 8 ECM
 SG_ Boost_Error : 0|8@1+ (0.28,0) [0|70.68] "kPa" Vector__XXX
 SG_ Boost_Pressure_50kPA : 8|8@1+ (2,0) [0|511] "kPa" Vector__XXX
 SG_ _of_Boost_Target : 16|8@1+ (0.4,0) [0|101.4] "%" Vector__XXX
 SG_ Boost_Injection_Duration : 24|16@1+ (10,0) [0|655359] "us" Vector__XXX
 SG_ Boost_Fuel_Reduction : 40|8@1+ (0.4,0) [0|101.4] "%" Vector__XXX
 SG_ Base_Target_Boost_Pressure : 48|8@1+ (0.5,0) [0|127] "kPa" Vector__XXX
 SG_ Auxillary_Injector_Variance : 56|8@1+ (1,0) [0|255] "%" Vector__XXX

BO_ 2566897152 DL_pBoostData_00: 8 ECM
 SG_ Boost_PID_P_Term : 0|16@1+ (0.01,0) [0|654.36] "kPa" Vector__XXX
 SG_ Boost_PID_I_Term : 16|16@1+ (0.01,0) [0|654.36] "kPa" Vector__XXX
 SG_ Boost_PID_D_Term : 32|16@1+ (0.01,0) [0|654.36] "kPa" Vector__XXX

BO_ 2566908928 DL_DataList15_00: 8 ECM
 SG_ Exhaust_Temperature : 0|16@1+ (1,0) [0|65535] "deg C" Vector__XXX
 SG_ InjectorIgnition_Supply_Voltage : 16|8@1+ (0.1,0) [0|24.6] "V" Vector__XXX
 SG_ Electric_Start_Option_Battery_Vo : 24|8@1+ (0.1,0) [0|24.6] "V" Vector__XXX
 SG_ Exhaust_Valve_Set_PWM : 32|8@1+ (0.4,0) [0|101.4] "%" Vector__XXX
 SG_ Exhaust_Valve_Actual_Position : 40|8@1+ (0.1,0) [0|24.6] "V" Vector__XXX
 SG_ Exhaust_Valve_Actual_Position : 48|8@1+ (0.4,0) [0|101.4] "%" Vector__XXX
 SG_ EV_Actuator_Feedback_PWM : 56|8@1+ (0.4,0) [0|101.4] "%" Vector__XXX

CM_ BO_ 2566909696 "Name: DL: DataList12
Description:";
CM_ SG_ 2566909696 Lambda_Sensor_Voltage_Bank_2_R "Description:";
CM_ SG_ 2566909696 Actual_Lambda_Bank_2_R "Description:";
CM_ SG_ 2566909696 Desired_Lambda_Bank_2_R "Description:";
CM_ SG_ 2566909696 Mixture_Adaption_Low_Load_Bank_2 "Description:rka2_w_msg";
CM_ SG_ 2566909696 Closed_Loop_Adjustment_Factor_2_ "Description:";
CM_ SG_ 2566909696 Average_Closed_Loop_Adjustment_F "Description:frm_w2";
CM_ SG_ 2566909696 Lambda_Sensor_Heater_Output__Ban "Description:";
CM_ SG_ 2566909696 AirFuel_Mixture_Status_Bank_2_R "Description:b_leanvk2";
CM_ SG_ 2566909696 ClosedLoop_Mixture_Control_Bank_ "Description:b_lr2";
CM_ SG_ 2566909696 Mixture_Adaption_High_Load_Bank_ "Description:fra2_w";
CM_ BO_ 2566884096 "Name: Available Speed Limits
Description: Parsed from -014. ";
CM_ SG_ 2566884096 Maximum_Vehicle_Speed_Limit_1_Av "Description: Indicates if the controller broadcasting this SPN is calibrated to support vehicle speed limit 1. ";
CM_ SG_ 2566884096 Maximum_Vehicle_Speed_Limit_4_Av "Description: Indicates if the controller broadcasting this SPN is calibrated to support vehicle speed limit 4. ";
CM_ SG_ 2566884096 Maximum_Vehicle_Speed_Limit_2_Av "Description: Indicates if the controller broadcasting this SPN is calibrated to support vehicle speed limit 2. ";
CM_ SG_ 2566884096 Maximum_Vehicle_Speed_Limit_5_Av "Description: Indicates if the controller broadcasting this SPN is calibrated to support vehicle speed limit 5. ";
CM_ SG_ 2566884096 Maximum_Vehicle_Speed_Limit_3_Av "Description: Indicates if the controller broadcasting this SPN is calibrated to support vehicle speed limit 3. ";
CM_ SG_ 2566884096 Maximum_Vehicle_Speed_Limit_7_Av "Description: Indicates if the controller broadcasting this SPN is calibrated to support vehicle speed limit 7. ";
CM_ SG_ 2566884096 Maximum_Vehicle_Speed_Limit_6_Av "Description: Indicates if the controller broadcasting this SPN is calibrated to support vehicle speed limit 6. ";
CM_ BO_ 2365530624 "Name: pTorque/Speed Control Feedback 2
Description: Feedback from the engine or motor controller to be used in conjunction with making torque/speed requests. To be used with PGN 65312 and PGN 65313.
Parsed from -014. ";
CM_ SG_ 2365530624 pRaw_Brake_Status "Description: Indication of a user&rsquo;s intent to apply the brake without any debounce on the signal. ";
CM_ SG_ 2365530624 pVehicle_Speed "Description: Indication of the current vehicle speed.
Could not parse SPN data type, please add:Type: Measured
Parsed from -014. ";
CM_ SG_ 2365530624 pEngine_TorqueSpeed_Control_Requ "Description: Contains reasons for the ECM denying engine control requests. ";
CM_ SG_ 2365530624 pEngine_Torque__Instantaneous_Ma "Description: Maximum instantaneous torque available from the engine.
Could not parse SPN data type, please add:Type: Calculated
Parsed from -014. ";
CM_ SG_ 2365530624 pEngine_Torque__Instantaneous_Mi "Description: Minimum instantaneous torque available from the engine.
Could not parse SPN data type, please add:Type: Calculated
Parsed from -014. ";
CM_ SG_ 2365530624 pNormalized_Accelerator_Position "Description: Indication of the current accelerator pedal position normalized to 0 to 100 %.
Could not parse SPN data type, please add:Type: Measured
Parsed from -014. ";
CM_ BO_ 2566881811 "Name: DL: pDatalist EPS2
Description:";
CM_ SG_ 2566881811 EPS_Motor_Commanded_Current "Description:Data Range: -125A to +125A offset -125";
CM_ SG_ 2566881811 pEPS_Temp "Description:Data Range: -40 degrees c to 210 degrees C -40 offset";
CM_ SG_ 2566881811 Factory_Absolute_Position_Offset "Description:Data Range: -20 to + 20 Deg";
CM_ BO_ 2566881299 "Name: DL: pDatalist EPS
Description:";
CM_ SG_ 2566881299 Absolute_Position_Offset "Description:Data Range: -3276.5 to 3276.5 degrees. -3276.5 degree offset";
CM_ SG_ 2566881299 Absolute_Position_Sensor_Raw_Val "Description:Data Range: -3276.5 to 3276.5 degrees. -3276.5 degree offset";
CM_ SG_ 2566881299 pEPS_SAS_Calibrated "Description:00- SAS not calibrated 01- SAS calibrated 10- Reserved 11- Not available";
CM_ SG_ 2566881299 Assist_Curve_Vehicle_Speed "Description:Speed used by EPS assist curve map to determine amount of applied assist torque";
CM_ SG_ 2566881299 Low_Res_Shaft_Position "Description:Data Range: &#160;-3276.5 to +3276.5. -3276.5 Offset&#160;";
CM_ BO_ 2566913811 "Name: DL: DataList1
Description:";
CM_ SG_ 2566913811 Throttle_Position_Sensor_1 "Description:";
CM_ SG_ 2566913811 Engine_Speed "Description:";
CM_ SG_ 2566913811 Engine_Temperature_Sensor "Description:";
CM_ SG_ 2566913811 Manifold_Absolute_Pressure_Senso "Description:";
CM_ SG_ 2566913811 Intake_Air_Temperature_Sensor "Description:";
CM_ SG_ 2566913811 Vehicle_Electric_Power "Description:SNO: Engine DC Voltage";
CM_ BO_ 2566882579 "Name: DL: pDatalist EPS3
Description:";
CM_ SG_ 2566882579 EPS_DC_Link_Voltage "Description:Data Range: 0&#160;to 18V (EPS Battery Voltage)";
CM_ SG_ 2566882579 Phase_A_Motor_Current "Description:Data Range: -125A to +125A Offset: -125";
CM_ SG_ 2566882579 Phase_B_Motor_Current "Description:Data Range: -125A to +125A Offset: -125";
CM_ SG_ 2566882579 Phase_C_Motor_Current "Description:Data Range: -125A to +125A Offset: -125";
CM_ BO_ 2566913555 "Name: DL: DataList2
Description:";
CM_ SG_ 2566913555 Throttle_Position "Description:";
CM_ SG_ 2566913555 Engine_Temperature "Description:";
CM_ SG_ 2566913555 Intake_Air_Temperature "Description:";
CM_ SG_ 2566913555 Manifold_Absolute_Pressure "Description:";
CM_ SG_ 2566913555 Boost_Pressure "Description:";
CM_ SG_ 2566913555 Barometric_Pressure "Description:";
CM_ SG_ 2566913555 Vehicle_Speed "Description:";
CM_ SG_ 2566913555 Barometric_Pressure_Sensor "Description:";
CM_ BO_ 2164236829 "Name: Development PGN 3
Description:Parsed from -014.";
CM_ BO_ 2164238109 "Name: Development PGN 8
Description:Parsed from -014.";
CM_ BO_ 2164237597 "Name: Development PGN 6
Description:Parsed from -014.";
CM_ BO_ 2164236317 "Name: Development PGN 1
Description:Parsed from -014.";
CM_ BO_ 2566910493 "Name: FI: FlagItems4
Description:";
CM_ SG_ 2566910493 Hazard_Switch_Input "Description:";
CM_ SG_ 2566910493 LowHigh_Beam_Input "Description:";
CM_ SG_ 2566910493 Fog_Light_Input "Description:";
CM_ SG_ 2566910493 Horn_Input "Description:";
CM_ SG_ 2566910493 High_Beam_Output "Description:";
CM_ SG_ 2566910493 Low_Beam_Output "Description:";
CM_ SG_ 2566910493 Left_Fog_Light_Output "Description:";
CM_ SG_ 2566910493 Right_Fog_Light_Output "Description:";
CM_ SG_ 2566910493 Unlock_Input "Description:";
CM_ SG_ 2566910493 Lock_Input "Description:";
CM_ SG_ 2566910493 Windsheild_Switch_Up_Input "Description:";
CM_ SG_ 2566910493 Windsheild_Switch_Down_Input "Description:";
CM_ SG_ 2566910493 Horn_Output "Description:";
CM_ SG_ 2566910493 Hazard_Light_Output "Description:";
CM_ SG_ 2566910493 Tail_Light_Output "Description:";
CM_ SG_ 2566910493 Brake_Light_Output "Description:";
CM_ SG_ 2566910493 Left_Front_Turn_Signal_Output "Description:";
CM_ SG_ 2566910493 Right_Front_Turn_Signal_Output "Description:";
CM_ SG_ 2566910493 Left_Rear_Turn_Signal_Output "Description:";
CM_ SG_ 2566910493 Right_Rear_Turn_Signal_Output "Description:";
CM_ SG_ 2566910493 Secondary_Air_Valve_Output "Description:";
CM_ SG_ 2566910493 Secondary_Air_Valve_Command "Description:";
CM_ SG_ 2566910493 Heated_Grip_Heat_Increase_Switch "Description:";
CM_ SG_ 2566910493 Heated_Grip_Heat_Decrease_Switch "Description:";
CM_ SG_ 2566910493 pOperator_Button_1 "Description:";
CM_ SG_ 2566910493 pOperator_Button_2 "Description:";
CM_ SG_ 2566910493 pSide_Stand_Switch "Description:";
CM_ SG_ 2566910493 Coolant_Fluid_Level_Switch "Description:";
CM_ SG_ 2566910493 Driveline_Momentary_Left "Description:";
CM_ SG_ 2566910493 Driveline_Momentary_Right "Description:";
CM_ SG_ 2566910493 Seatbelt_Switch "Description:";
CM_ SG_ 2566910493 Brake_Fluid_Level_Switch "Description:";
CM_ BO_ 2566907933 "Name: DL: DataList19
Description:";
CM_ SG_ 2566907933 Tire_Pressure_Front_Left_or_Only "Description:";
CM_ SG_ 2566907933 Tire_Pressure_Front_Right "Description:";
CM_ SG_ 2566907933 Tire_Pressure_Rear_Left_or_Only_ "Description:";
CM_ SG_ 2566907933 Tire_Pressure_Rear_Right "Description:";
CM_ SG_ 2566907933 Last_Received_Key_Fob_ID_Byte_1 "Description:S/N Min = 0x00000001 - 1dec S/N Max = 0x0000FFFE - 65534dec Least Significant";
CM_ SG_ 2566907933 Last_Received_Key_Fob_ID_Byte_2 "Description:S/N stored as 4Byte Integer - Little Endian 0x00 for all 4 data bytes will indicate no fob";
CM_ SG_ 2566907933 Last_Received_Key_Fob_ID_Byte_3 "Description:S/N stored as 4Byte Integer - Little Endian 0x00 for all 4 data bytes will indicate no fob";
CM_ SG_ 2566907933 Last_Received_Key_Fob_ID_Byte_4 "Description:S/N Min = 0x00000001 - 1dec S/N Max = 0x0000FFFE - 65534dec Most Significant";
CM_ BO_ 2164237853 "Name: Development PGN 7
Description:Parsed from -014.";
CM_ BO_ 2164236573 "Name: Development PGN 2
Description:Parsed from -014.";
CM_ BO_ 2566907677 "Name: DL: DataList20
Description:";
CM_ SG_ 2566907677 Number_of_Discovered_Key_Fobs "Description:";
CM_ SG_ 2566907677 LeanAngle "Description:";
CM_ BO_ 2566856221 "Name: FI: Flag Items 7
Description:     ";
CM_ SG_ 2566856221 Switched_Power_Output_Status "Description:0 = INACTIVE 1 = ACTIVE 2 = ERROR 3 = NOT AVAILABLE";
CM_ SG_ 2566856221 K15_Output_Status "Description:0 = INACTIVE 1 = ACTIVE 2 = ERROR 3 = NOT AVAILABLE";
CM_ SG_ 2566856221 Lock_Motor_Driver_Status "Description:0 = INACTIVE 1 = ACTIVE 2 = ERROR 3 = NOT AVAILABLE";
CM_ SG_ 2566856221 Homelink_1_Output_Status "Description:0 = INACTIVE 1 = ACTIVE 2 = ERROR 3 = NOT AVAILABLE";
CM_ SG_ 2566856221 Homelink_2_Output_Status "Description:0 = INACTIVE 1 = ACTIVE 2 = ERROR 3 = NOT AVAILABLE";
CM_ SG_ 2566856221 Windshield_Output_Status "Description:0 = INACTIVE 1 = ACTIVE 2 = ERROR 3 = NOT AVAILABLE";
CM_ SG_ 2566856221 Puddle_Light_Driver_Status "Description:0 = INACTIVE 1 = ACTIVE 2 = ERROR 3 = NOT AVAILABLE";
CM_ SG_ 2566856221 Puddle_Light_Enable_Status "Description:0 = DIABLED 1 = ENABLED 2 = ERROR 3 = NOT AVAILABLE";
CM_ SG_ 2566856221 Fuel_Door_Switch_Input_Status "Description:0 = INACTIVE 1 = ACTIVE 2 = ERROR 3 = NOT AVAILABLE";
CM_ SG_ 2566856221 VCM_Location_Pin_Status "Description:0 = OPEN 1 = GND 2 = VBAT 3 = H-BRIDGE";
CM_ SG_ 2566856221 Fuel_Lock_Motor_Driver_Status "Description:0 = INACTIVE 1 = ACTIVE 2 = ERROR 3 = NOT AVAILABLE";
CM_ SG_ 2566856221 Accent_Lights_Output_Status "Description:0 = INACTIVE 1 = ACTIVE 2 = ERROR 3 = NOT AVAILABLE";
CM_ BO_ 2164237341 "Name: Development PGN 5
Description:Parsed from -014.";
CM_ BO_ 2164237085 "Name: Development PGN 4
Description:Parsed from -014.";
CM_ BO_ 2566887727 "Name: DL: pDatalist SCM
Description:";
CM_ SG_ 2566887727 Compression_Valve_Driver_Current "Description:";
CM_ SG_ 2566887727 Compression_Valve_Driver_Current "Description:";
CM_ SG_ 2566887727 Compression_Valve_Driver_Current "Description:";
CM_ SG_ 2566887727 Compression_Valve_Driver_Current "Description:";
CM_ SG_ 2566887727 Suspension_Mode_Switch_Input_Vol "Description:This is the non-normalized voltage.";
CM_ SG_ 2566887727 Shock_Valve_Supply_Relay_Status "Description:0 - Relay Inactive 1 - Relay Active";
CM_ SG_ 2566887727 Steering_Angle_Adaption_Offset "Description:";
CM_ BO_ 2566888751 "Name: DL: pDataList SCM2
Description:";
CM_ SG_ 2566888751 Compression_Valve_Driver_Current "Description:";
CM_ SG_ 2566888751 Compression_Valve_Driver_Current "Description:";
CM_ SG_ 2566888751 Compression_Valve_Driver_Current "Description:";
CM_ SG_ 2566888751 Compression_Valve_Driver_Current "Description:";
CM_ SG_ 2566888751 Rebound_Valve_Driver_Current_Cmd "Description:";
CM_ SG_ 2566888751 Rebound_Valve_Driver_Current_Cmd "Description:";
CM_ SG_ 2566888751 Rebound_Valve_Driver_Current_Cmd "Description:";
CM_ SG_ 2566888751 Rebound_Valve_Driver_Current_Cmd "Description:";
CM_ BO_ 2566889007 "Name: DL: pDataList SCM3
Description:";
CM_ SG_ 2566889007 Rebound_Valve_Driver_Current_fb_ "Description:Rebound Valve Driver Current Feedback - Front Left";
CM_ SG_ 2566889007 Rebound_Valve_Driver_Current_fb_ "Description:Rebound Valve Driver Current Feedback - Front Right";
CM_ SG_ 2566889007 Rebound_Valve_Driver_Current_fb_ "Description:Rebound Valve Driver Current Feedback - Rear Left";
CM_ SG_ 2566889007 Rebound_Valve_Driver_Current_fb_ "Description:Rebound Valve Driver Current Feedback - Rear Right";
CM_ BO_ 2364543791 "Name: Slope Sensor Information
Description:";
CM_ SG_ 2364543791 Pitch_Angle "Description:The angle between the vehicle x-axis and the ground plane (i.e. rotation about the vehicle Y-axis). The pitch angle for an angle of ascent is reported with a positive value. This parameter is defined according to a Z-Down axis sys";
CM_ SG_ 2364543791 Roll_Angle "Description:The angle between the vehicle y-axis and the ground plane (i.e. rotation about the X-axis). The roll angle for a roll to the right is reported with a positive value. Roll angle is the same for both Z-Down and Z-Up axis systems, sin";
CM_ SG_ 2364543791 Pitch_Rate "Description:Pitch rate is the rate-of-change of the pitch angle over time, where the pitch angle vector is in the direction of travel of the vehicle. The pitch rate for increasing ascent over time is reported with a positive value. This parame";
CM_ SG_ 2364543791 Pitch_Angle_Figure_of_Merit "Description:Figure of merit for pitch angle measurement. 00b = Pitch angle fully functional. Data is within sensor specification. 01b = Pitch angle degraded. Data is suspect due to environmental conditions. 10b = Error 11b = N";
CM_ SG_ 2364543791 Roll_Angle_Figure_of_Merit "Description:Figure of merit for roll angle measurement. 00b = Roll angle fully functional. Data is within sensor specification. 01b = Roll angle degraded. Data is suspect due to environmental conditions. 10b = Error 11b = Not a";
CM_ SG_ 2364543791 Pitch_Rate_Figure_of_Merit "Description:Figure of merit for the pitch rate measurement. 00b = Pitch rate fully functional. Data is within sensor specification. 01b = Pitch rate degraded. Data is suspect due to environmental conditions. 10b = Error 11b = N";
CM_ SG_ 2364543791 Pitch_and_Roll_Compensated "Description:Compensated mode for the pitch and roll measurements. Compensation is the use of multiple sensors together to enhance the output of pitch and roll measurements. 00b = Compensation Off 01b = Compensation On 10b = Err";
CM_ SG_ 2364543791 Roll_and_Pitch_Measurement_Laten "Description:The estimated measurement latency of the measurement. NOTE: This is only the sensor latency and does not include any additional latencies that might exist because of the CAN Bus or overall system implementatio";
CM_ BO_ 2566889263 "Name: DL: pDataList SCM4
Description:";
CM_ SG_ 2566889263 Compression_Valve_Resistance__FL "Description:Compression Valve Resistance Measurement - Front Left";
CM_ SG_ 2566889263 Compression_Valve_Resistance__FR "Description:Compression valve resistance measurement - Front Right";
CM_ SG_ 2566889263 Compression_Valve_Resistance__RL "Description:Compression Valve Resistance Measurement - Rear Left";
CM_ SG_ 2566889263 Compression_Valve_Resistance__RR "Description:Compression Valve Resistance Measurement - Rear Right";
CM_ SG_ 2566889263 Rebound_Valve_Resistance__FL "Description:Rebound valve resistance measurement - Front Left";
CM_ SG_ 2566889263 Rebound_Valve_Resistance__FR "Description:Rebound valve resistance measurement - Front Right";
CM_ SG_ 2566889263 Rebound_Valve_Resistance__RL "Description:Rebound valve resistance measurement - Rear Left";
CM_ SG_ 2566889263 Rebound_Valve_Resistance__RR "Description:Rebound valve resistance measurement - Rear Right";
CM_ BO_ 2566913547 "Name: DL: DataList2
Description:";
CM_ SG_ 2566913547 Throttle_Position "Description:";
CM_ SG_ 2566913547 Engine_Temperature "Description:";
CM_ SG_ 2566913547 Intake_Air_Temperature "Description:";
CM_ SG_ 2566913547 Manifold_Absolute_Pressure "Description:";
CM_ SG_ 2566913547 Boost_Pressure "Description:";
CM_ SG_ 2566913547 Barometric_Pressure "Description:";
CM_ SG_ 2566913547 Vehicle_Speed "Description:";
CM_ SG_ 2566913547 Barometric_Pressure_Sensor "Description:";
CM_ BO_ 2566910208 "Name: FI: FlagItems5
Description:     ";
CM_ SG_ 2566910208 bEnable "Description:";
CM_ SG_ 2566910208 bBatt "Description:";
CM_ SG_ 2566910208 bNotRun "Description:";
CM_ SG_ 2566910208 bOper "Description:";
CM_ SG_ 2566910208 b10Sec "Description:";
CM_ SG_ 2566910208 bManCyc "Description:";
CM_ SG_ 2566910208 bLazyCRC "Description:";
CM_ SG_ 2566910208 bSpare_11b "Description:Must be 11b for CANGert to work.";
CM_ SG_ 2566910208 DRL_Right "Description:LSD on MG1 pin 126 00b=Active 01b=Inactive";
CM_ SG_ 2566910208 DRL_Left "Description:LSD on MG1 pin 139 00b=Active 01b=Inactive";
CM_ BO_ 2566876695 "Name: pVehicle Fluids
Description: Parsed from -014. ";
CM_ SG_ 2566876695 pHydraulic_Oil_Temp_Status "Description: Indicates status of Hydraulic oil temperature. ";
CM_ SG_ 2566876695 pHydraulic_Oil_Pressure_Status "Description: Indicates status of Hydraulic oil pressure. ";
CM_ SG_ 2566876695 pEngine_Oil_Pressure_Status "Description: Indicates status of engine oil pressure. ";
CM_ BO_ 2566838807 "Name: DL: Software Ident
Description:";
CM_ BO_ 2633984791 "Name: pVehicle Initialization Parameters
Description:Parsed from -014.";
CM_ SG_ 2633984791 pInstrumentation_Backlight_Inten "Description: Intensity (brightness) of instrumentation backlighting, 0% is no backlight and 100% is the maximum brightness the gauge is capable of. 
Could not parse SPN data type, please add:Type: Status
Parsed from -01";
CM_ SG_ 2633984791 pFuel_Economy_Data_Source "Description: Fuel Economy data determination. Determines where fuel economy (Range, Instantaneous and Average fuel economy) is calculated.  ";
CM_ SG_ 2633984791 pActive_Decent_Control_ADC_Mode_ "Description: Used to let devices know if the vehicle is equipped with a momentary driveline mode switch and ADC ";
CM_ SG_ 2633984791 pFuel_Level_Data_Source "Description: Fuel consumption data determination. Determines where the fuel sender resistive input is read ";
CM_ SG_ 2633984791 pVehicle_Units_Configuration "Description: Vehicle Units Configuration: MPH = Miles per Hour for speed & miles for distance, km/h = Kilometers per Hour & Kilometers for distance, Fahrenheit = temperature in degrees Fahrenheit, Celsius = temperature in deg";
CM_ SG_ 2633984791 pLow_Fuel_Light_ON_Percentage "Description: Fuel percentage at which to turn the Low Fuel Light ON 
Could not parse SPN data type, please add:Type: Status
Parsed from -014. ";
CM_ SG_ 2633984791 pSeat_Belt_Input_Source "Description: Determines what component reads the seat belt switch input.  ";
CM_ SG_ 2633984791 pAWD_Mode_Availability "Description: Used to let devices know if the vehicle is equipped with a momentary driveline mode switch and AWD ";
CM_ SG_ 2633984791 pWarning_Lamp_Intensity "Description: Intensity (brightness) of warning lamp(s) which have the ability to be adjusted, 0% is warning lamp disabled and 100% is the maximum brightness the warning lamp(s) are capable of. 
Could not parse SPN data type, plea";
CM_ SG_ 2633984791 pTurf_Mode_Availability "Description: Used to let devices know if the vehicle is equipped with with a momentary driveline mode switch and rear diff solenoid.  ";
CM_ SG_ 2633984791 pFuel_Tank_Volume "Description: Total volume of fuel tank installed in vehicle
Could not parse SPN data type, please add:Type: Status
Parsed from -014. ";
CM_ SG_ 2633984791 pDisplayed_Speed_Correction_Fact "Description: When the first byte of PGN 65387 is set to any value other than 0x00, the pVIP primary definition will be used. When the first byte of PGN 65387 is set to 0x00, the secondary pVIP definition will be used.
Fo";
CM_ BO_ 2566846231 "Name: Vehicle Electrical Power 1
Description: Parsed from -014. ";
CM_ SG_ 2566846231 Key_Switch_Battery_Potential "Description:Battery potential measured at the input of the electronic control unit supplied through a key switch or similar switching device.
Note: Parsed from J1939DA.";
CM_ SG_ 2566846231 Alternator_Current "Description:Measure of electrical current flow from the alternator. Alternator Current (High Range/Resolution) parameter SPN 1795 has a higher range and resolution of the same parameter.
Note: Parsed from J1939DA.";
CM_ SG_ 2566846231 Charging_System_Potential_Voltag "Description:Electrical potential measured at the charging system output. The charging system may be any device charging the batteries. This includes alternators, generators, solid state charger and other charging devices.";
CM_ SG_ 2566846231 SLI_Battery_1_Net_Current "Description:Net flow of electrical current into/out of the first battery or first set of batteries used for starting the engine, for lighting, and for ignition (SLI). If more than one battery is included in the first set of batt";
CM_ SG_ 2566846231 Battery_Potential__Power_Input_1 "Description:This parameter measures the first source of battery potential as measured at the input of the ECU/actuator etc. coming from one or more batteries, irrespective of the distance between the component and the bat";
CM_ BO_ 2633984577 "Name: pDrive System Status
Description: Parsed from -014. ";
CM_ SG_ 2633984577 pHeated_Grip_Enable "Description: This signal indicates the status of the Heated Grip Enable switch. ";
CM_ SG_ 2633984577 pUser_PIN_Access_Status "Description: This signal indicates if the display/gauge should show the User PIN screen, which allows the user the option of unlocking the vehicle security through the PIN code entry function.  ";
CM_ SG_ 2633984577 pActive_Descent_Control_ADC_Stat "Description: Broadcasting the status of the ADC (active indicates the solenoid is powered). ";
CM_ SG_ 2633984577 pCruise_Control_Set_Status "Description: Broadcasting the status of the Cruise Control Set Status for user indication  ";
CM_ SG_ 2633984577 pTether_Switch_Status "Description: Status of the Tether Switch ";
CM_ SG_ 2633984577 pHigh_Beam_Indicator_Status "Description: Broadcasting the status of the high beam headlight for user indication. ";
CM_ SG_ 2633984577 pLow_Fuel_Indicator_Status "Description: Broadcasting the status of the fuel level for user indication. ";
CM_ SG_ 2633984577 pHeated_Grips_Percentage "Description: Heated Grips Percent On, 0% is Off and 100% is the maximum heat
Could not parse SPN data type, please add:Type: Status
Parsed from -014. ";
CM_ SG_ 2633984577 pSide_Stand_Status "Description: Position of the side stand position when installed on a vehicle. ";
CM_ SG_ 2633984577 pTurf_Mode_Requested "Description: Broadcasting the status of the users request for TURF mode ";
CM_ SG_ 2633984577 pEngine_Idle_Shutdown_Timer "Description: This signal indicates the the amount of time left before the engine is shutdown due to the unattended vehicle engine idle shutdown function.
10-bit Timer:
0 &ndash; 1021 seconds
1022 - Error
1023 - Not Availab";
CM_ SG_ 2633984577 Operator_Not_in_Operating_Statio "Description: The Operator Presence Detection System indicates the operator is not in the correct operating station. ";
CM_ SG_ 2633984577 pAWD_Mode_Requested "Description: Broadcasting the status of the users request for AWD mode ";
CM_ SG_ 2633984577 pHeated_Grips_Up_Switch_Status "Description: This signal indicates the status of the Heated Grip Up switch. ";
CM_ SG_ 2633984577 pTreadle_Neutral_Status "Description: Broadcasting the status of the switch indicating the treadle is/is not in the Neutral position.  ";
CM_ SG_ 2633984577 pHeated_Grips_Down_Switch_Status "Description: This signal indicates the status of the Heated Grip Down switch. ";
CM_ SG_ 2633984577 pPark_Brake_Indicator_Status "Description: Broadcasting the status of the park brake for user indication ";
CM_ SG_ 2633984577 pRWD_Mode_Requested "Description: Broadcasting the status of the users request for RWD mode ";
CM_ SG_ 2633984577 pSeat_Belt_Indicator_Status "Description: Broadcasting the status of the seat belt for user indication ";
CM_ SG_ 2633984577 pSecurity_Light_Immobilizer_Stat "Description: Broadcasting the status of the security system for user indication.  ";
CM_ SG_ 2633984577 ECU_Security_Status "Description: Security Status of an ECU. ";
CM_ SG_ 2633984577 pActive_Decent_Control_ADC_Mode_ "Description: Broadcasting the status of the users request for ADC mode ";
CM_ SG_ 2633984577 pTreadle_Reverse_Status "Description: Broadcasting the status of the switch indicating the treadle is/is not in the Reverse position.  ";
CM_ BO_ 2566877249 "Name: pRadio Display 1
Description: Parsed from -014. ";
CM_ SG_ 2566877249 pRadio_Input_Device "Description: ";
CM_ SG_ 2566877249 pScreen_Area_Configuration "Description: ";
CM_ SG_ 2566877249 pRadio_Input_Value "Description: Could not parse SPN data type, please add:Type: Measured
Parsed from -014. ";
CM_ SG_ 2566877249 pStereo_Status "Description: ";
CM_ SG_ 2566877249 pText_Line_Configuration "Description: ";
CM_ SG_ 2566877249 pHighlight_Row "Description: ";
CM_ SG_ 2566877249 pScreen_Area_Mode "Description: ";
CM_ SG_ 2566877249 pFirst_Row_Configuration "Description: ";
CM_ SG_ 2566877249 pRadio_Scaling_Of_SPN_524100 "Description: ";
CM_ BO_ 2566845761 "Name: Ambient Conditions
Description: Parsed from -014. ";
CM_ SG_ 2566845761 Ambient_Air_Temperature "Description:Temperature of air surrounding vehicle.
Note: Parsed from J1939DA.";
CM_ SG_ 2566845761 Barometric_Pressure "Description:Absolute air pressure of the atmosphere.
Note: Parsed from J1939DA.";
CM_ SG_ 2566845761 Road_Surface_Temperature "Description:Indicated temperature of road surface over which vehicle is operating.
Note: Parsed from J1939DA.";
CM_ SG_ 2566845761 Engine_Intake_1_Air_Temperature "Description:Temperature of air entering vehicle air induction system.
Note: Parsed from J1939DA.";
CM_ BO_ 2231316801 "Name: pPlow Mode Status
Description: Used to provide status from Plow Mode Controller when plow mode is engaged
Parsed from -014. ";
CM_ SG_ 2231316801 pPlow_Down_State "Description: Plow Controller&rsquo;s Plow Down Status ";
CM_ SG_ 2231316801 pWinch_In_Commanded_State "Description: State of Plow Controller to Command Winch In ";
CM_ SG_ 2231316801 pWinch_Out_Commanded_State "Description: State of Plow Controller to Command Winch Out ";
CM_ SG_ 2231316801 pPlow_Mode_State "Description: Plow Controller&rsquo;s Plow Mode Status ";
CM_ SG_ 2231316801 pWinch_Auto_Stop_Signal "Description: Autostop Signal from winch fairlead to Plow Controller ";
CM_ BO_ 2231317569 "Name: pPlow Mode Status2
Description: Used to provide Winch In, Winch Out, and Autostop input pin voltage readings from Plow Controller.
Parsed from -014. ";
CM_ SG_ 2231317569 pWinch_In_Relay_Control_Voltage "Description: Voltage Potential at Winch In Control Pin
Range 0-3212.75 Volts, 0.05V/bit
Same format as SPN 168
Parsed from -014. ";
CM_ SG_ 2231317569 pWinch_Out_Relay_Control_Voltage "Description:Voltage Potential at Winch Out Control PinSame format as SPN 168";
CM_ SG_ 2231317569 pAutostop_Signal_Voltage "Description:Voltage Potential Plow Home Input PinSame format as SPN 168";
CM_ BO_ 2566888001 "Name: pAntiTheft
Description: Parsed from -014. ";
CM_ SG_ 2566888001 pAntiTheft_Component_Status_Indi "Description: This state signal is included in the lower functionality proprietary Anti-Theft implementation. The product team&rsquo;s specification did not line up with the J1939 standard Anti-Theft messages, nor the alre";
CM_ SG_ 2566888001 pAntiTheft_Command_States "Description: This command signal is included in the lower functionality proprietary Anti-Theft implementation. The product team&rsquo;s specification did not line up with the J1939 standard Anti-Theft messages, nor the already n";
CM_ SG_ 2566888001 pAntiTheft_Pin_Presence "Description: 
This parameter is used to indicate if a pin is being provided or requested to the component. ";
CM_ SG_ 2566888001 pAntiTheft_Pin_Parameter "Description: 
A four byte numeric code used to represent the user pin in response to a pin request or on pin change. This parameter is sent as a numeric value utilizing the full range of 0 to 0xFFFFFFFF. The most significant byt";
CM_ BO_ 2365555078 "Name: pOperator Switch Status 3
Description: Parsed from -014. ";
CM_ SG_ 2365555078 pOperator_Switch_Status_3 "Description: Broadcasting the status of the operator switch. ";
CM_ SG_ 2365555078 pUpPaddleStatus "Description: Used to broadcast status of RHC steering wheel shift paddle for Up shifting. ";
CM_ SG_ 2365555078 pOperator_Switch_Status_2 "Description: Broadcasting the status of the operator switch.  ";
CM_ SG_ 2365555078 pDwPaddleStatus "Description: Used to broadcast status of LHC steering wheel shift paddle for Down shifting. ";
CM_ SG_ 2365555078 pOperator_Button_50_Pucker "Description: Broadcasting the status of the operator switch.  ";
CM_ BO_ 2566844806 "Name: Cruise Control Vehicle Speed 1
Description: Parsed from -014. ";
CM_ SG_ 2566844806 Cruise_Control_Set_Speed "Description:Value of set (chosen) velocity of velocity control system. See SPN 6809 for an alternate resolution. If an algorithm that can modify the cruise control set point exists in the system, such as Predictive Cruise Control";
CM_ SG_ 2566844806 Cruise_Control_Active "Description:Cruise control is switched on. It is not ensured that the engine is controlled by cruise control, as in the case of a large driver's demand the engine is controlled by the driver while cruise control is active (maximum s";
CM_ SG_ 2566844806 Clutch_Switch "Description:Switch signal which indicates that the clutch pedal is being pressed. It is necessary for a safe drivetrain behavior that the clutch switch is set before the clutch is opened (cruise control function). 00b = Clutch pedal release";
CM_ SG_ 2566844806 Brake_Switch "Description:Switch signal which indicates that the driver operated brake foot pedal is being pressed. This brake foot pedal is controlling the vehicles' service brake (total vehicle braking application, not park brakes). It is necessary for ";
CM_ SG_ 2566844806 pCC_Message_Counter "Description: Rolling Counter (ensures updated message is used).
Could not parse SPN data type, please add:Type: Status
Parsed from -014. ";
CM_ SG_ 2566844806 Cruise_Control_Pause_Switch "Description:Switch signal which indicates the position of the Cruise Control Pause Switch used on Remote Cruise Control applications. The Cruise Control Pause Switch signal temporarily disables the Cruise Control function. 00b";
CM_ SG_ 2566844806 Cruise_Control_Set_Switch "Description:Switch signal of the cruise control activator which indicates that the activator is in the position set. 00b = Cruise control activator not in the position set 01b = Cruise control activator in position set 10b = Err";
CM_ SG_ 2566844806 Two_Speed_Axle_Switch "Description:Switch signal which indicates the current axle range. 00b = Low speed range 01b = High speed range 10b = Error 11b = Not available
Note: Parsed from J1939DA.";
CM_ SG_ 2566844806 Cruise_Control_Enable_Switch "Description:Switch signal which indicates that it is possible to manage the cruise control function. 00b = Cruise control disabled 01b = Cruise control enabled 10b = Error 11b = Not available
Note: Parsed from J1939DA.";
CM_ SG_ 2566844806 pOdometer_Drive_Bit "Description: Each State A->B or B->A change indicates the vehicle has moved 40 m since the previous one. However, since the message is sent at regular 100 ms intervals, State A and B each occur multiple times consecutively (a minimum ";
CM_ SG_ 2566844806 pCC_Checksum "Description: XOR of bytes 0-6 (ensures data is valid before use). 
Could not parse SPN data type, please add:Type: Status
Parsed from -014. ";
CM_ SG_ 2566844806 WheelBased_Vehicle_Speed "Description:Speed of the vehicle as calculated from wheel or tailshaft speed.
Note: Parsed from J1939DA.";
CM_ SG_ 2566844806 Cruise_Control_Resume_Switch "Description:Switch signal of the cruise control activator which indicates that the activator is in the position resume. 00b = Cruise control activator not in the position resume 01b = Cruise control activator in position resu";
CM_ SG_ 2566844806 Cruise_Control_Accelerate_Switch "Description:Switch signal of the cruise control activator which indicates that the activator is in the position accelerate. 00b = Cruise control activator not in the position accelerate 01b = Cruise control activator in p";
CM_ SG_ 2566844806 pCruise_Enable_Status "Description: The Cruise Control System has been enabled by the operator. (Amber Light) ";
CM_ SG_ 2566844806 Parking_Brake_Switch "Description:Switch signal which indicates when the parking brake is set. In general the switch actuated by the operator's park brake control, whether a pedal, lever or other control mechanism (see also SPN 619 and 5275). 00b = Parkin";
CM_ SG_ 2566844806 Cruise_Control_Coast_Decelerate_ "Description:Switch signal of the cruise control activator which indicates that the activator is in the position coast (decelerate). 00b = Cruise control activator not in the position coast 01b = Cruise control activator i";
CM_ BO_ 2432656774 "Name: pOperator Switch Status
Description: Parsed from -014. ";
CM_ SG_ 2432656774 Key_Fob_Unlock_Button_Status "Description: These group of SPN&rsquo;s contain the information for the Operator Switches. See PGN 65380 breakdown for definition of each button. ";
CM_ SG_ 2432656774 Homelink_2 "Description: These group of SPN&rsquo;s contain the information for the Operator Switches. See PGN 65380 breakdown for definition of each button. ";
CM_ SG_ 2432656774 Side_Stand_Switch "Description: ";
CM_ SG_ 2432656774 Key_Fob_Lock_Button_Status "Description: These group of SPN&rsquo;s contain the information for the Operator Switches. See PGN 65380 breakdown for definition of each button. ";
CM_ SG_ 2432656774 Windshield__2_Down "Description: These group of SPN&rsquo;s contain the information for the Operator Switches. See PGN 65380 breakdown for definition of each button. ";
CM_ SG_ 2432656774 Turn__3_Cancel "Description: These group of SPN&rsquo;s contain the information for the Operator Switches. See PGN 65380 breakdown for definition of each button. ";
CM_ SG_ 2432656774 Reverse "Description: These group of SPN&rsquo;s contain the information for the Operator Switches. See PGN 65380 breakdown for definition of each button. ";
CM_ SG_ 2432656774 Hazard "Description: These group of SPN&rsquo;s contain the information for the Operator Switches. See PGN 65380 breakdown for definition of each button. ";
CM_ SG_ 2432656774 Homelink_1 "Description: These group of SPN&rsquo;s contain the information for the Operator Switches. See PGN 65380 breakdown for definition of each button. ";
CM_ SG_ 2432656774 Windshield__1_Up "Description: These group of SPN&rsquo;s contain the information for the Operator Switches. See PGN 65380 breakdown for definition of each button. ";
CM_ SG_ 2432656774 Front_Brake_Switch "Description: Indicates the status of the front brake switch ";
CM_ SG_ 2432656774 Instrument_Cluster_Control__2 "Description: These group of SPN&rsquo;s contain the information for the Operator Switches. See PGN 65380 breakdown for definition of each button. ";
CM_ SG_ 2432656774 Chassis_Unlock_Button_Status "Description: These group of SPN&rsquo;s contain the information for the Operator Switches. See PGN 65380 breakdown for definition of each button. ";
CM_ SG_ 2432656774 Power_Button "Description: These group of SPN&rsquo;s contain the information for the Operator Switches. See PGN 65380 breakdown for definition of each button. ";
CM_ SG_ 2432656774 RunStop_Switch "Description: These group of SPN&rsquo;s contain the information for the Operator Switches. See PGN 65380 breakdown for definition of each button. ";
CM_ SG_ 2432656774 Headlamp__2_High "Description: These group of SPN&rsquo;s contain the information for the Operator Switches. See PGN 65380 breakdown for definition of each button. ";
CM_ SG_ 2432656774 Instrument_Cluster_Control__1 "Description: These group of SPN&rsquo;s contain the information for the Operator Switches. See PGN 65380 breakdown for definition of each button. ";
CM_ SG_ 2432656774 Clutch_Switch "Description: These group of SPN&rsquo;s contain the information for the Operator Switches. See PGN 65380 breakdown for definition of each button. ";
CM_ SG_ 2432656774 Start "Description: These group of SPN&rsquo;s contain the information for the Operator Switches. See PGN 65380 breakdown for definition of each button. ";
CM_ SG_ 2432656774 Headlamp__3_Driving "Description: These group of SPN&rsquo;s contain the information for the Operator Switches. See PGN 65380 breakdown for definition of each button. ";
CM_ SG_ 2432656774 Cruise__2_Set "Description: These group of SPN&rsquo;s contain the information for the Operator Switches. See PGN 65380 breakdown for definition of each button. ";
CM_ SG_ 2432656774 Windshield_Wiper "Description: These group of SPN&rsquo;s contain the information for the Operator Switches. See PGN 65380 breakdown for definition of each button. ";
CM_ SG_ 2432656774 Fog "Description: These group of SPN&rsquo;s contain the information for the Operator Switches. See PGN 65380 breakdown for definition of each button. ";
CM_ SG_ 2432656774 Cruise__3_Accel "Description: These group of SPN&rsquo;s contain the information for the Operator Switches. See PGN 65380 breakdown for definition of each button. ";
CM_ SG_ 2432656774 Horn "Description: These group of SPN&rsquo;s contain the information for the Operator Switches. See PGN 65380 breakdown for definition of each button. ";
CM_ SG_ 2432656774 Turn__2_Right "Description: These group of SPN&rsquo;s contain the information for the Operator Switches. See PGN 65380 breakdown for definition of each button. ";
CM_ SG_ 2432656774 Cruise__1_On "Description: These group of SPN&rsquo;s contain the information for the Operator Switches. See PGN 65380 breakdown for definition of each button. ";
CM_ SG_ 2432656774 Turn__1_Left "Description: These group of SPN&rsquo;s contain the information for the Operator Switches. See PGN 65380 breakdown for definition of each button. ";
CM_ SG_ 2432656774 Throttle_Safety_Switch__1 "Description: These group of SPN&rsquo;s contain the information for the Operator Switches. See PGN 65380 breakdown for definition of each button. ";
CM_ SG_ 2432656774 Headlamp__1_Low "Description: These group of SPN&rsquo;s contain the information for the Operator Switches. See PGN 65380 breakdown for definition of each button. ";
CM_ SG_ 2432656774 Chassis_Lock_Switch_Status "Description:Created due to CMS fault code using this SPN";
CM_ SG_ 2432656774 Fuel_Door_Unlock_Button_Status "Description:Displays the status of the Fuel Door Unlock button. See PGN 65380 breakdown for the definition of each button.";
CM_ BO_ 2566877830 "Name: pVehicle Temperature
Description: Parsed from -014. ";
CM_ SG_ 2566877830 pRight_Hand_Grip_Temperature "Description: Temperature of thermistor in the right hand grip.
Could not parse SPN data type, please add:Type: Measured
Parsed from -014. ";
CM_ SG_ 2566877830 pDriver_Seat_Temperature "Description: Temperature of thermistor in the Driver Seat.
Could not parse SPN data type, please add:Type: Measured
Parsed from -014. ";
CM_ SG_ 2566877830 pPassenger_Seat_Temperature "Description: Temperature of thermistor in the Passenger Seat.
Could not parse SPN data type, please add:Type: Measured
Parsed from -014. ";
CM_ SG_ 2566877830 pLeft_Hand_Grip_Temperature "Description: Temperature of thermistor in the left hand grip.
Could not parse SPN data type, please add:Type: Measured
Parsed from -014. ";
CM_ BO_ 2365531796 "Name: pRCM User Input Status
Description:Contains outputs from the RCM to communicate the status and function of user inputs from the RCM to the master module";
CM_ SG_ 2365531796 pButton1_Function "Description:Communicates from RCM to master module the function of button 1 for the corresponding button Status SPN";
CM_ SG_ 2365531796 pButton1_Status "Description:Communicates from RCM to master module the status of button 1";
CM_ SG_ 2365531796 pButton2_Function "Description:Communicates from RCM to master module the function of button 2 for the corresponding button Status SPN";
CM_ SG_ 2365531796 pButton2_Status "Description:Communicates from RCM to master module the status of button 2";
CM_ SG_ 2365531796 pButton3_Function "Description:Communicates from RCM to master module the function of button 3 for the corresponding button Status SPN";
CM_ SG_ 2365531796 pButton3_Status "Description:Communicates from RCM to master module the status of button 3";
CM_ SG_ 2365531796 pButton4_Function "Description:Communicates from RCM to master module the function of button 4 for the corresponding button Status SPN";
CM_ SG_ 2365531796 pButton4_Status "Description:Communicates from RCM to master module the status of button 4";
CM_ SG_ 2365531796 pButton5_Function "Description:Communicates from RCM to master module the function of button 5 for the corresponding button Status SPN";
CM_ SG_ 2365531796 pButton5_Status "Description:Communicates from RCM to master module the status of button 5";
CM_ SG_ 2365531796 pRotaryKnob_Function "Description:Communicates from RCM to master module the function of rotary knob 1 for the corresponding rotary knob Status SPN";
CM_ SG_ 2365531796 pRotaryKnob_Status "Description:Communicates from RCM to master module the status of the rotary knob";
CM_ SG_ 2365531796 pRotaryKnob_Position "Description:Position of the rotary knob, in degrees.";
CM_ SG_ 2365531796 pRotaryKnob_DetentsSinceLastTX "Description:Absolute number of detents the knob has moved since the last transmitted update. Direction to be inferred from pRotaryKnob_Status.";
CM_ SG_ 2365531796 pRCM_Message_Counter "Description:Rolling Counter (ensures updated message is used). Increments by 1 each time PGN 65318 is broadcast; after 15 its next value will wrap back around to 0.";
CM_ BO_ 2566896687 "Name: DL: pDataList SCM5
Description:";
CM_ SG_ 2566896687 AX_RQI "Description:Longitudinal Acceleration Ride Quality Index";
CM_ SG_ 2566896687 AY_RQI "Description:Lateral Acceleration Ride Quality Index";
CM_ SG_ 2566896687 AZ_RQI "Description:Vertical Acceleration Ride Quality Index";
CM_ SG_ 2566896687 AgrAYRQI "Description:Pitch Ride Quality Index";
CM_ SG_ 2566896687 AgrAXRQI "Description:Roll Ride Quality Index";
CM_ SG_ 2566896687 Total_Vehicle_RQI "Description:Total Vehicle Ride Quality Index";
CM_ BO_ 2365531155 "Name: pVehModCmd
Description:Vehicle Mode Command";
CM_ SG_ 2365531155 pEPSReqMod "Description: Used to set the EPAS assist mode. ";
CM_ BO_ 2298415360 "Name: pTemperature Message
Description: Parsed from -014. ";
CM_ SG_ 2298415360 pJunction_Temp "Description: Actual junction temperature of the Electric Propulsion Control Unit or Auxiliary Power Unit from which the message is sent

Could not parse SPN data type, please add:Type: Measured
Parsed from -014. ";
CM_ SG_ 2298415360 pCapacitor_Temp "Description: Actual capacitor temperature of the Electric Propulsion Control Unit or Auxiliary Power Unit from which the message is sent

Could not parse SPN data type, please add:Type: Measured
Parsed from -014. ";
CM_ SG_ 2298415360 pMotor_Temp_Margin "Description: The smallest difference between an internal motor component and its thermal limit for the Electric Propulsion Control Unit or Auxiliary Power Control Unit from which the message is sent

Could not parse SPN data type, pl";
CM_ SG_ 2298415360 pBaseplate_Temp "Description: Actual baseplate temperature of the Electric Propulsion Control Unit or Auxiliary Power Unit from which the message is sent

Data Length: 1 byte 
Start Position: 3.1
Type: Measured
PGN: 65289
Parsed from -014. ";
CM_ SG_ 2298415360 pBoard_Temp "Description: Board temperature of the Electric Propulsion Control Unit or Auxiliary Power Unit from which the message is sent

Could not parse SPN data type, please add:Type: Measured
Parsed from -014. ";
CM_ SG_ 2298415360 pController_Temp_Margin "Description: The smallest difference between an internal component and its thermal limit for the Electric Propulsion Control Unit or Auxiliary Power Control Unit from which the message is sent

Could not parse SPN data type, ple";
CM_ SG_ 2298415360 pTemperature_Message_Checksum "Description: Checksum is calculated by taking XOR of bytes from 1 to 7.
Could not parse SPN data type, please add:Type: Status
Parsed from -014. ";
CM_ SG_ 2298415360 pMotor_Temp "Description: Actual motor temperature of the Electric Propulsion Unit or Auxiliary Power Unit from which the message is sent

Could not parse SPN data type, please add:Type: Measured
Parsed from -014. ";
CM_ BO_ 2365525760 "Name: pEnergy Message
Description: Parsed from -014. ";
CM_ SG_ 2365525760 pSOC "Description: The State of Charge (SOC) &ndash; percent of battery capacity available at current battery health and temperature &ndash; of the battery pack monitored by the Battery Management Controller (BMC).

Could not parse SPN data type, please";
CM_ SG_ 2365525760 pAvailable_Wh "Description: The capacity, in Watt hours, of the battery pack monitored by the Battery Management Controller (BMC).

Could not parse SPN data type, please add:Type: Status
Parsed from -014. ";
CM_ SG_ 2365525760 pWh_in_Since_key_on "Description: The capacity in Watt hours delivered to the battery pack monitored by the Battery Management Controller (BMC), negative for net energy removed from the battery pack.

Could not parse SPN data type, please add:Type: Meas";
CM_ SG_ 2365525760 pEnergy_Message_Checksum "Description: Checksum is calculated by taking XOR of bytes from 1 to 7.
Could not parse SPN data type, please add:Type: Status
Parsed from -014. ";
CM_ BO_ 2298428672 "Name: pPower Train Operating Mode
Description:Multiple Power Train modes of operation such as Drive Line, Drive Mode, Engine Operation State, Warm Up Cycle, etc";
CM_ SG_ 2298428672 pVehicle_Pitch_Angle "Description:Vehicle pitch angle

AUTOSAR name: VehPitchAg";
CM_ SG_ 2298428672 Engine_Operating_State "Description:This parameter is used to indicate the current state, or mode, of operation by the engine. This is a status parameter. 0000b = Engine Stopped 0001b = Pre-Start 0010b = Starting 0011b = Warm-Up 0100b = Running 0101b = Co";
CM_ SG_ 2298428672 pWarmup_cycle_detection_status "Description:Warm-up cycle detection status

AUTOSAR name: WrmUpCycDetn";
CM_ SG_ 2298428672 pDrive_cycle_detection_status "Description:Drive cycle detection

AUTOSAR name: DrvCycDetn";
CM_ SG_ 2298428672 pDrive_Mode "Description:Drive mode

AUTOSAR name: DrvMode";
CM_ SG_ 2298428672 Driveline_Mode "Description:Signal to provide the current driveline mode.

States
0000b: 2WD
0001b: AWD
0010b: ADC (ADC1)
0011b: TURF
0100b: Ultra TURF (3WD)
0101b: ADC2
0110b: ADC3
0111b-1101b: Reserved for Future Use
1110b: Error
1111b: Not ";
CM_ BO_ 2298414848 "Name: pPerformance Message
Description: Parsed from -014. ";
CM_ SG_ 2298414848 pPerformance_Message_Checksum "Description: Checksum is calculated by taking XOR of bytes from 1 to 7.
Could not parse SPN data type, please add:Type: Status
Parsed from -014. ";
CM_ SG_ 2298414848 pLower_Available_Torque_Limit "Description: The maximum torque available in the reverse direction. Lower available torque is normally negative but can be positive in a negative overspeed condition.

Could not parse SPN data type, please add:Type: Status";
CM_ SG_ 2298414848 pPerformance_State "Description: Bits dictating the state of the Electric Propulsion Control Unit or Auxiliary Power Unit from which the message is sent. ";
CM_ SG_ 2298414848 pActual_Motor_Torque "Description: Actual generated torque from Electronic Propulsion unit

Could not parse SPN data type, please add:Type: Status
Parsed from -014. ";
CM_ SG_ 2298414848 pUpper_Available_Torque_Limit "Description: The maximum torque available in the positive direction. Upper available torque is normally negative but can be positive in a negative overspeed condition.

Could not parse SPN data type, please add:Type: Statu";
CM_ SG_ 2298414848 pActual_Motor_Velocity "Description: Actual RPM of the Electric Propulsion Control Unit or Auxiliary Power Unit from which the message is sent.

Could not parse SPN data type, please add:Type: Measured
Parsed from -014. ";
CM_ SG_ 2298414848 pPer_Msg_Count "Description:Created due to CMS fault code using this SPN";
CM_ BO_ 2365525504 "Name: pBMC Power Message
Description: Parsed from -014. ";
CM_ SG_ 2365525504 pPack_Voltage "Description: The voltage of the battery pack monitored by the Battery Management Controller (BMC).

Could not parse SPN data type, please add:Type: Measured
Parsed from -014. ";
CM_ SG_ 2365525504 pDischarge_Limit "Description: The discharge limit of the battery pack monitored by the Battery Management Controller (BMC).

Could not parse SPN data type, please add:Type: Status
Parsed from -014. ";
CM_ SG_ 2365525504 pPack_Current "Description: The current of the battery pack monitored by the Battery Management Controller (BMC).

Could not parse SPN data type, please add:Type: Measured
Parsed from -014. ";
CM_ SG_ 2365525504 pBMC_Power_Message_Checksum "Description: Checksum is calculated by taking XOR of bytes from 1 to 7.
Could not parse SPN data type, please add:Type: Status
Parsed from -014. ";
CM_ SG_ 2365525504 pCharge_Limit "Description: The Charge limit of the battery pack monitored by the Battery Management Controller (BMC).

Could not parse SPN data type, please add:Type: Status
Parsed from -014. ";
CM_ BO_ 2566799360 "Name: Lighting Data
Description:";
CM_ SG_ 2566799360 High_Beam_Head_Light_Data "Description:This parameter provides measured data from the tractor high beam head light lamps. 00b = De-activated 01b = Activated 10b = Fault Detected 11b = Not Available
Note: Parsed from J1939DA.";
CM_ SG_ 2566799360 Low_Beam_Head_Light_Data "Description:This parameter provides measured data from the tractor low beam head light lamps. 00b = De-activated 01b = Activated 10b = Fault Detected 11b = Not Available
Note: Parsed from J1939DA.";
CM_ SG_ 2566799360 Running_Light "Description:This parameter provides measured data from the vehicle's running lights. 00b = De-activated 01b = Activated 10b = Fault Detected 11b = Not Available
Note: Parsed from J1939DA.";
CM_ SG_ 2566799360 Left_Turn_Signal_Lights "Description:This parameter provides measured data from the tractor and attached implement left turn signal lights. 00b = De-activated 01b = Activated 10b = Fault Detected 11b = Not Available
Note: Parsed from J1939DA.";
CM_ SG_ 2566799360 Right_Turn_Signal_Lights "Description:This parameter provides measured data from the tractor and attached implement right turn signal lights. 00b = De-activated 01b = Activated 10b = Fault Detected 11b = Not Available
Note: Parsed from J1939DA.";
CM_ SG_ 2566799360 Left_Stop_Light "Description:This parameter provides measured data from the tractor and attached implement left stop lights. 00b = De-activated 01b = Activated 10b = Fault Detected 11b = Not Available
Note: Parsed from J1939DA.";
CM_ SG_ 2566799360 Right_Stop_Light "Description:This parameter provides measured data from the tractor and attached implement right stop lights. 00b = De-activated 01b = Activated 10b = Fault Detected 11b = Not Available
Note: Parsed from J1939DA.";
CM_ SG_ 2566799360 Tractor_Front_Fog_Lights "Description:This parameter provides measured data from the tractor front fog lights. 00b = De-activated 01b = Activated 10b = Fault Detected 11b = Not Available
Note: Parsed from J1939DA.";
CM_ SG_ 2566799360 Implement_OEM_Option_1_Light "Description:This parameter provides measured data from the implement OEM option 1 light. 00b = De-activated 01b = Activated 10b = Fault Detected 11b = Not Available
Note: Parsed from J1939DA.";
CM_ SG_ 2566799360 Implement_OEM_Option_2_Light "Description:This parameter provides measured data from the implement OEM option 2 light. 00b = De-activated 01b = Activated 10b = Fault Detected 11b = Not Available
Note: Parsed from J1939DA.";
CM_ BO_ 2365526528 "Name: pCharger Status Message
Description: Parsed from -014. ";
CM_ SG_ 2365526528 pCharger_Temp "Description: The temperature of the battery charger.

Could not parse SPN data type, please add:Type: Measured
Parsed from -014. ";
CM_ SG_ 2365526528 pCharger_Voltage "Description: The voltage output of the battery charger.

Could not parse SPN data type, please add:Type: Measured
Parsed from -014. ";
CM_ SG_ 2365526528 pCharger_Status_Counter "Description: Counter to verify latest message, counts 0-15

Could not parse SPN data type, please add:Type: Measured
Parsed from -014. ";
CM_ SG_ 2365526528 pCharger_State "Description: State of the battery charging process.  ";
CM_ SG_ 2365526528 pCharger_Status_Message_Checksum "Description: Checksum is calculated by taking XOR of bytes from 1 to 7.
Could not parse SPN data type, please add:Type: Status
Parsed from -014. ";
CM_ SG_ 2365526528 pAC_Status "Description: State signifying the presence of an AC Supply on the battery charger. ";
CM_ SG_ 2365526528 pCharger_Current "Description: The output current of the battery charger.

Could not parse SPN data type, please add:Type: Measured
Parsed from -014. ";
CM_ BO_ 2365526016 "Name: pTraction Battery Status Message
Description: Parsed from -014. ";
CM_ SG_ 2365526016 pSOH "Description: The State of Health (SOH) &ndash; percent of the battery&rsquo;s nominal capacity remaining due to aging effects &ndash; of the battery pack monitored by the Battery Management Controller (BMC).

Could not parse SPN data type, please ";
CM_ SG_ 2365526016 pBattery_Temp_Max "Description: The maximum temperature of the battery pack monitored by the Battery Management Controller (BMC).

Could not parse SPN data type, please add:Type: Measured
Parsed from -014. ";
CM_ SG_ 2365526016 pK_battemp "Description: The percent of energy capacity at 25&deg;C and current State of Health (SOH) that is available at useful discharge rates at the current battery temperature of the battery pack monitored by the Battery Management Controller (BMC).
";
CM_ SG_ 2365526016 pFloat_State "Description: The status bits indicating the electrolyte level of the battery pack monitored by the Battery Management Controller (BMC). ";
CM_ SG_ 2365526016 pBattery_Temp_Min "Description: The minimum temperature of the battery pack monitored by the Battery Management Controller (BMC).

Could not parse SPN data type, please add:Type: Measured
Parsed from -014. ";
CM_ SG_ 2365526016 pTraction_Battery_Status_Message "Description: Checksum is calculated by taking XOR of bytes from 1 to 7.
Could not parse SPN data type, please add:Type: Status
Parsed from -014. ";
CM_ BO_ 2298415104 "Name: pPower Message
Description: Parsed from -014. ";
CM_ SG_ 2298415104 pController_Thermal_Cutback_Stat "Description: Status bit indicating the ramp down of motor control output and subsequent vehicle performance due to the temperature of the motor controller exceeding a predefined value. ";
CM_ SG_ 2298415104 pCapacitor_Voltage "Description: Capacitor Voltage of the Electric Propulsion Control Unit or Auxiliary Power Control Unit from which the message is sent.

Could not parse SPN data type, please add:Type: Measured
Parsed from -014. ";
CM_ SG_ 2298415104 pMotor_Power_Cutback_Status "Description: Status bit indicating the ramp down of motor control output and subsequent vehicle performance due to low power availability. ";
CM_ SG_ 2298415104 pInput_Current "Description: Input DC Current of the Electric Propulsion Control Unit or Auxiliary Power Control Unit from which the message is sent.

Could not parse SPN data type, please add:Type: Measured
Parsed from -014. ";
CM_ SG_ 2298415104 pMotor_Thermal_Cutback_Status "Description: Status bit indicating the ramp down of motor control output and subsequent vehicle performance due to the temperature of the motor exceeding a predefined value. ";
CM_ SG_ 2298415104 pInput_DC_Current_Cutback_Status "Description: Status bit indicating the ramp down of motor control output and subsequent vehicle performance due to low Input Current. ";
CM_ SG_ 2298415104 pSpeed_Limit_Cutback_Status "Description: Status bit indicating the ramp down of motor control output and subsequent vehicle performance due to the motor speed exceeding the limits set for the motor.  ";
CM_ SG_ 2298415104 pPower_Message_Checksum "Description: Checksum is calculated by taking XOR of bytes from 1 to 7.
Could not parse SPN data type, please add:Type: Status
Parsed from -014. ";
CM_ BO_ 2566895895 "Name: pAccessory Control Heated Grips 1
Description: Parsed from -014. ";
CM_ SG_ 2566895895 pSetpoint_Grips_Hand_Medium "Description: Medium temperature setpoint of thermistor in the hand grips.
Could not parse SPN data type, please add:Type: Measured
Parsed from -014. ";
CM_ SG_ 2566895895 pSetpoint_Grips_Hand_Low "Description: Low temperature setpoint of thermistor in the hand grips.
Could not parse SPN data type, please add:Type: Measured
Parsed from -014. ";
CM_ SG_ 2566895895 pSetpoint_Grip_Thumb_Medium "Description: Medium temperature setpoint of thermistor in the thumb grip.
Could not parse SPN data type, please add:Type: Measured
Parsed from -014. ";
CM_ SG_ 2566895895 pAccessory_Control_Operation "Description: Intended to identify the accessory control operation under discussion ";
CM_ SG_ 2566895895 pSetpoint_Grips_Hand_High "Description: High temperature setpoint of thermistor in the hand grips.
Could not parse SPN data type, please add:Type: Measured
Parsed from -014. ";
CM_ SG_ 2566895895 pAccessory_Control_Mode "Description: Intended to identify the accessory control mode under discussion ";
CM_ SG_ 2566895895 pSetpoint_Grip_Thumb_High "Description: High temperature setpoint of thermistor in the thumb grip.
Could not parse SPN data type, please add:Type: Measured
Parsed from -014. ";
CM_ SG_ 2566895895 pSetpoint_Grip_Thumb_Low "Description: Low temperature setpoint of thermistor in the thumb grip.
Could not parse SPN data type, please add:Type: Measured
Parsed from -014. ";
CM_ BO_ 2566877207 "Name: pRadio Display 1
Description: Parsed from -014. ";
CM_ SG_ 2566877207 pRadio_Input_Device "Description: ";
CM_ SG_ 2566877207 pScreen_Area_Configuration "Description: ";
CM_ SG_ 2566877207 pRadio_Input_Value "Description: Could not parse SPN data type, please add:Type: Measured
Parsed from -014. ";
CM_ SG_ 2566877207 pStereo_Status "Description: ";
CM_ SG_ 2566877207 pText_Line_Configuration "Description: ";
CM_ SG_ 2566877207 pHighlight_Row "Description: ";
CM_ SG_ 2566877207 pScreen_Area_Mode "Description: ";
CM_ SG_ 2566877207 pFirst_Row_Configuration "Description: ";
CM_ SG_ 2566877207 pRadio_Scaling_Of_SPN_524100 "Description: ";
CM_ BO_ 2633984535 "Name: pDrive System Status
Description: Parsed from -014. ";
CM_ SG_ 2633984535 pHeated_Grip_Enable "Description: This signal indicates the status of the Heated Grip Enable switch. ";
CM_ SG_ 2633984535 pUser_PIN_Access_Status "Description: This signal indicates if the display/gauge should show the User PIN screen, which allows the user the option of unlocking the vehicle security through the PIN code entry function.  ";
CM_ SG_ 2633984535 pActive_Descent_Control_ADC_Stat "Description: Broadcasting the status of the ADC (active indicates the solenoid is powered). ";
CM_ SG_ 2633984535 pCruise_Control_Set_Status "Description: Broadcasting the status of the Cruise Control Set Status for user indication  ";
CM_ SG_ 2633984535 pTether_Switch_Status "Description: Status of the Tether Switch ";
CM_ SG_ 2633984535 pHigh_Beam_Indicator_Status "Description: Broadcasting the status of the high beam headlight for user indication. ";
CM_ SG_ 2633984535 pLow_Fuel_Indicator_Status "Description: Broadcasting the status of the fuel level for user indication. ";
CM_ SG_ 2633984535 pHeated_Grips_Percentage "Description: Heated Grips Percent On, 0% is Off and 100% is the maximum heat
Could not parse SPN data type, please add:Type: Status
Parsed from -014. ";
CM_ SG_ 2633984535 pSide_Stand_Status "Description: Position of the side stand position when installed on a vehicle. ";
CM_ SG_ 2633984535 pTurf_Mode_Requested "Description: Broadcasting the status of the users request for TURF mode ";
CM_ SG_ 2633984535 pEngine_Idle_Shutdown_Timer "Description: This signal indicates the the amount of time left before the engine is shutdown due to the unattended vehicle engine idle shutdown function.
10-bit Timer:
0 &ndash; 1021 seconds
1022 - Error
1023 - Not Availab";
CM_ SG_ 2633984535 Operator_Not_in_Operating_Statio "Description: The Operator Presence Detection System indicates the operator is not in the correct operating station. ";
CM_ SG_ 2633984535 pAWD_Mode_Requested "Description: Broadcasting the status of the users request for AWD mode ";
CM_ SG_ 2633984535 pHeated_Grips_Up_Switch_Status "Description: This signal indicates the status of the Heated Grip Up switch. ";
CM_ SG_ 2633984535 pTreadle_Neutral_Status "Description: Broadcasting the status of the switch indicating the treadle is/is not in the Neutral position.  ";
CM_ SG_ 2633984535 pHeated_Grips_Down_Switch_Status "Description: This signal indicates the status of the Heated Grip Down switch. ";
CM_ SG_ 2633984535 pPark_Brake_Indicator_Status "Description: Broadcasting the status of the park brake for user indication ";
CM_ SG_ 2633984535 pRWD_Mode_Requested "Description: Broadcasting the status of the users request for RWD mode ";
CM_ SG_ 2633984535 pSeat_Belt_Indicator_Status "Description: Broadcasting the status of the seat belt for user indication ";
CM_ SG_ 2633984535 pSecurity_Light_Immobilizer_Stat "Description: Broadcasting the status of the security system for user indication.  ";
CM_ SG_ 2633984535 ECU_Security_Status "Description: Security Status of an ECU. ";
CM_ SG_ 2633984535 pActive_Decent_Control_ADC_Mode_ "Description: Broadcasting the status of the users request for ADC mode ";
CM_ SG_ 2633984535 pTreadle_Reverse_Status "Description: Broadcasting the status of the switch indicating the treadle is/is not in the Reverse position.  ";
CM_ BO_ 2566875159 "Name: pFuelType
Description: Parsed from -014. ";
CM_ SG_ 2566875159 pFuel_Type_Selected "Description: Indicates the fuel type selected by any means such as a switch or resistive ladder or sensor. ";
CM_ SG_ 2566875159 pFuel_Type_Sensor "Description: Fuel type as measured by a fuel sensor directly measuring the ethanol content
Could not parse SPN data type, please add:Type: Measured
Parsed from -014. ";
CM_ BO_ 2566862113 "Name: pEPreload Suspension Position
Description:E-Preload Suspension Position Information";
CM_ SG_ 2566862113 pSuspPosn "Description:0-25.0, 0xFE = Error, 0xFF = Not Available";
CM_ SG_ 2566862113 pRotSnsr "Description:E-Preload Rotation Sensor Voltage, 0-5.5V";
CM_ SG_ 2566862113 pMinEndPtSaved "Description:E-Preload Min End Point Saved Status";
CM_ SG_ 2566862113 pMaxEndPtSaved "Description:E-Preload Max End Point Save Status";
CM_ BO_ 2566871696 "Name: pEPreloadMaxMinSettings
Description:Max Min settings as configured in the controlling module for EPreload, sent on request only.";
CM_ SG_ 2566871696 pEPreloadDriverMaxWeight "Description:Driver Max Weight Setting from VCM";
CM_ SG_ 2566871696 pEPreloadDriverMinWeight "Description:Driver Min weight setting from VCM";
CM_ SG_ 2566871696 pEPreloadPassengerMaxWeight "Description:Passenger max weight setting";
CM_ SG_ 2566871696 pEPreloadPassengerMinWeight "Description:Passenger Min weight setting";
CM_ SG_ 2566871696 pEPreloadLuggageMaxWeight "Description:Luggage max weight setting";
CM_ SG_ 2566871696 pEPreloadTrunkMaxWeight "Description:Trunk Max weight setting";
CM_ SG_ 2566871696 pEPreloadTotalMaxWeight "Description:Maximum total allowable weight, includes driver, passenger, trunk and all cargo.";
CM_ SG_ 2566871696 pEPreloadFineTuneMax "Description:Max and min allowable fine tune values, a value of 4 implies min fine tune of -4 turns and max fine tune of +4 turns";
CM_ BO_ 2566870416 "Name: pEPreload Status
Description:";
CM_ SG_ 2566870416 pSaveMaxEndPt "Description:Request to save max E-Preload End Point";
CM_ SG_ 2566870416 pSaveMinEndPt "Description:Request to save E-Preload min end point";
CM_ SG_ 2566870416 pEPreloadFeatureStatus "Description:E-Preload Feature Status";
CM_ SG_ 2566870416 pEPreloadDriverWeight "Description:Driver Weight request from display, current setting from VCM";
CM_ SG_ 2566870416 pEPreloadMovmtStatus "Description:EPreload Shock Motor Movement status from VCM and Movement request from Display";
CM_ SG_ 2566870416 pEPreloadPassengerWeight "Description:Passenger weight request from display and setting from VCM";
CM_ SG_ 2566870416 pEPreloadLuggageWeight "Description:Luggage Weight Request from Display and current setting from VCM";
CM_ SG_ 2566870416 pEPreloadTrunkWeight "Description:Trunk weight setting request from display and current setting from VCM";
CM_ SG_ 2566870416 pEPreloadFineTune "Description:EPreload Fine tune number of turns";
CM_ SG_ 2566870416 pEPreloadTotalWeight "Description:Total Weight setting";
CM_ SG_ 2566870416 pEPreloadTrunkInstallStatus "Description:Trunk installation request from Display and status from VCM";
CM_ BO_ 2566872576 "Name: pBoost Mode
Description: Parsed from -014. ";
CM_ SG_ 2566872576 pBoostModeRequested "Description: Bit State Represenstation of the requested boost mode.

 ";
CM_ SG_ 2566872576 pWastegateActuatorFeedback "Description: Wastegate Actuator Position Percentage of fully open position.
Could not parse SPN data type, please add:Type: Measured
Parsed from -014. ";
CM_ SG_ 2566872576 pBoostModeCommanded "Description: Bit State Represenstation of the commanded boost mode. ";
CM_ SG_ 2566872576 pPercentOfTargetBoost "Description: Percentage of target boost commanded by the ECU to display to the user.
Could not parse SPN data type, please add:Type: Measured
Parsed from -014. ";
CM_ SG_ 2566872576 pBoostModeEnablement "Description: Permission Bits for ECU Controller Boost Drive Modes to Allow transition to another Boost Drive Mode. ";
CM_ BO_ 2566872320 "Name: pEngine Statistics
Description: Slow Update Rate Engine Statistical Information ";
CM_ SG_ 2566872320 Engine_Break_In "Description: Engine Break In percentage used to communicate with the cluster the percentage of calculated engine break in. ";
CM_ BO_ 2566909184 "Name: DL: DataList14
Description:";
CM_ SG_ 2566909184 Port_Injector_2_Time_LSB "Description:";
CM_ SG_ 2566909184 Case_Injector_2_Time_LSB "Description:";
CM_ SG_ 2566909184 Cyl_2_Ignition_Timing "Description:";
CM_ SG_ 2566909184 Cyl_2_Base_Ignition_Timing "Description:SNO: do NOT display in digital wrench";
CM_ SG_ 2566909184 Cyl_2_Ignition_Coil_Dwell "Description:";
CM_ SG_ 2566909184 Cyl_2_Ignition_Coil_Dwell "Description:";
CM_ BO_ 2566909440 "Name: DL: DataList13
Description:";
CM_ SG_ 2566909440 Port_Injector_1_Time "Description:";
CM_ SG_ 2566909440 Case_Injector_1_Time "Description:";
CM_ SG_ 2566909440 Cyl_1_Ignition_Timing "Description:";
CM_ SG_ 2566909440 Cyl_1_Base_Ignition_Timing "Description:SNO: do NOT display in digital wrench";
CM_ SG_ 2566909440 Cyl_1_Ignition_Coil_Dwell "Description:";
CM_ SG_ 2566909440 Cyl_1_Ignition_Coil_Dwell "Description:";
CM_ BO_ 2566900992 "Name: DL: Datalist
Description:";
CM_ SG_ 2566900992 EV_Learn_Up_Position "Description:";
CM_ SG_ 2566900992 EV_Learn_Down_Position "Description:";
CM_ SG_ 2566900992 Auxillary_Injector_PW_MAG "Description:";
CM_ SG_ 2566900992 Auxillary_Injector_PW_PTO "Description:";
CM_ BO_ 2566905600 "Name: DL: Engine Info
Description:";
CM_ SG_ 2566905600 ECU_Power_Input_1 "Description:SNO PBR - ECU Power";
CM_ SG_ 2566905600 ECU_Power_Input_2 "Description:SNO PBR - Critical Power";
CM_ SG_ 2566905600 ECU_Power_Input_3 "Description:SNO PBR - Chassis Power";
CM_ SG_ 2566905600 Mixture_Adaption_High_Load_Bank_ "Description:fra2_w";
CM_ SG_ 2566905600 Tire_Pressure_Spare "Description:";
CM_ SG_ 2566905600 AirFuel_Mixture_Status_Bank_1_F "Description:b_leanvk";
CM_ SG_ 2566905600 EGT_2 "Description:Silencer EGT";
CM_ SG_ 2566905600 AlphaN_Output_Fuel_Flow "Description:0-3212.75 l/h";
CM_ SG_ 2566905600 Fuel_Variance__DialBox "Description:fuel offset applied from dialbox engineering tool for data analysis";
CM_ BO_ 2566911744 "Name: DL: DataList9
Description:";
CM_ SG_ 2566911744 Knock_Retard_Cylinder_1 "Description:";
CM_ SG_ 2566911744 Knock_Retard_Cylinder_2 "Description:";
CM_ SG_ 2566911744 Injection_DET_Correction_MAG "Description:";
CM_ SG_ 2566911744 Injection_DET_Correction_PTO "Description:";
CM_ SG_ 2566911744 Detonation_Voltage_LSB "Description:Was previously Detonation Frequency Cylinder 1 Scaling: 0.4 %/bit. Still is for SNO.";
CM_ SG_ 2566911744 Detonation_Voltage_MSB "Description:Was previously Detonation Frequency Cylinder 2 Scaling: 0.4 %/bit. Still is for SNO.";
CM_ SG_ 2566911744 Ignition_Variance "Description:SNO: do NOT display in digital wrench";
CM_ SG_ 2566911744 Fuel_Variance_in_ "Description:SNO: do NOT display in digital wrench";
CM_ BO_ 2566882304 "Name: DL: Datalist_SnoRes.
Description:";
CM_ SG_ 2566882304 Boost_Error "Description:Turbo Boost Error Calculated Value (Target Boost-Actual Gauge Boost Pressure)";
CM_ SG_ 2566882304 Boost_Pressure_50kPA "Description:";
CM_ SG_ 2566882304 _of_Boost_Target "Description:";
CM_ SG_ 2566882304 Boost_Injection_Duration "Description:";
CM_ SG_ 2566882304 Boost_Fuel_Reduction "Description:";
CM_ SG_ 2566882304 Base_Target_Boost_Pressure "Description:";
CM_ SG_ 2566882304 Auxillary_Injector_Variance "Description:";
CM_ BO_ 2566897152 "Name: DL: pBoostData
Description:";
CM_ SG_ 2566897152 Boost_PID_P_Term "Description:";
CM_ SG_ 2566897152 Boost_PID_I_Term "Description:";
CM_ SG_ 2566897152 Boost_PID_D_Term "Description:";
CM_ BO_ 2566908928 "Name: DL: DataList15
Description:";
CM_ SG_ 2566908928 Exhaust_Temperature "Description:Pipe EGT";
CM_ SG_ 2566908928 InjectorIgnition_Supply_Voltage "Description:";
CM_ SG_ 2566908928 Electric_Start_Option_Battery_Vo "Description:";
CM_ SG_ 2566908928 Exhaust_Valve_Set_PWM "Description:";
CM_ SG_ 2566908928 Exhaust_Valve_Actual_Position "Description:";
CM_ SG_ 2566908928 Exhaust_Valve_Actual_Position "Description:";
CM_ SG_ 2566908928 EV_Actuator_Feedback_PWM "Description:";
BA_DEF_ SG_  "SigType" ENUM  "Default","Range","RangeSigned","ASCII","Discrete","Control","ReferencePGN","DTC","StringDelimiter","StringLength","StringLengthControl";
BA_DEF_ SG_  "GenSigEVName" STRING ;
BA_DEF_ SG_  "GenSigILSupport" ENUM  "No","Yes";
BA_DEF_ SG_  "GenSigSendType" ENUM  "Cyclic","OnWrite","OnWriteWithRepetition","OnChange","OnChangeWithRepetition","IfActive","IfActiveWithRepetition","NoSigSendType";
BA_DEF_ BO_  "GenMsgCycleTimeFast" INT 0 3600000;
BA_DEF_ BO_  "GenMsgILSupport" ENUM  "No","Yes";
BA_DEF_ BO_  "GenMsgSendType" ENUM  "cyclic","spontaneous","cyclicIfActive","spontaneousWithDelay","cyclicAndSpontaneous","cyclicAndSpontaneousWithDelay","spontaneousWithRepetition","cyclicIfActiveAndSpontaneousWD","OnRequest";
BA_DEF_ BO_  "GenMsgRequestable" INT 0 1;
BA_DEF_ BO_  "GenMsgCycleTime" INT 0 3600000;
BA_DEF_ SG_  "SPN" INT 0 524287;
BA_DEF_ BO_  "VFrameFormat" ENUM  "StandardCAN","ExtendedCAN","reserved","J1939PG";
BA_DEF_DEF_  "SigType" "Default";
BA_DEF_DEF_  "GenSigEVName" "Env@Nodename_@Signame";
BA_DEF_DEF_  "GenSigILSupport" "Yes";
BA_DEF_DEF_  "GenSigSendType" "NoSigSendType";
BA_DEF_DEF_  "GenMsgCycleTimeFast" 0;
BA_DEF_DEF_  "GenMsgILSupport" "Yes";
BA_DEF_DEF_  "GenMsgSendType" "noMsgSendType";
BA_DEF_DEF_  "GenMsgRequestable" 1;
BA_DEF_DEF_  "GenMsgCycleTime" 0;
BA_DEF_DEF_  "SPN" 0;
BA_DEF_DEF_  "VFrameFormat" "J1939PG";
BA_ "SPN" SG_ 2566909696 Lambda_Sensor_Voltage_Bank_2_R 517277;
BA_ "SPN" SG_ 2566909696 Actual_Lambda_Bank_2_R 516543;
BA_ "SPN" SG_ 2566909696 Desired_Lambda_Bank_2_R 516508;
BA_ "SPN" SG_ 2566909696 Mixture_Adaption_Low_Load_Bank_2 516696;
BA_ "SPN" SG_ 2566909696 Closed_Loop_Adjustment_Factor_2_ 517198;
BA_ "SPN" SG_ 2566909696 Average_Closed_Loop_Adjustment_F 516941;
BA_ "SPN" SG_ 2566909696 Lambda_Sensor_Heater_Output__Ban 516613;
BA_ "SPN" SG_ 2566909696 AirFuel_Mixture_Status_Bank_2_R 516658;
BA_ "SPN" SG_ 2566909696 ClosedLoop_Mixture_Control_Bank_ 516565;
BA_ "SPN" SG_ 2566909696 Mixture_Adaption_High_Load_Bank_ 517485;
BA_ "SPN" SG_ 2566884096 Maximum_Vehicle_Speed_Limit_1_Av 520347;
BA_ "SPN" SG_ 2566884096 Maximum_Vehicle_Speed_Limit_4_Av 520350;
BA_ "SPN" SG_ 2566884096 Maximum_Vehicle_Speed_Limit_2_Av 520348;
BA_ "SPN" SG_ 2566884096 Maximum_Vehicle_Speed_Limit_5_Av 520351;
BA_ "SPN" SG_ 2566884096 Maximum_Vehicle_Speed_Limit_3_Av 520349;
BA_ "SPN" SG_ 2566884096 Maximum_Vehicle_Speed_Limit_7_Av 520353;
BA_ "SPN" SG_ 2566884096 Maximum_Vehicle_Speed_Limit_6_Av 520352;
BA_ "SPN" SG_ 2365530624 pRaw_Brake_Status 520572;
BA_ "SPN" SG_ 2365530624 pVehicle_Speed 520573;
BA_ "SPN" SG_ 2365530624 pEngine_TorqueSpeed_Control_Requ 520577;
BA_ "SPN" SG_ 2365530624 pEngine_Torque__Instantaneous_Ma 520576;
BA_ "SPN" SG_ 2365530624 pEngine_Torque__Instantaneous_Mi 520575;
BA_ "SPN" SG_ 2365530624 pNormalized_Accelerator_Position 520574;
BA_ "SPN" SG_ 2566881811 EPS_Motor_Commanded_Current 517191;
BA_ "SPN" SG_ 2566881811 pEPS_Temp 516564;
BA_ "SPN" SG_ 2566881811 Factory_Absolute_Position_Offset 516939;
BA_ "SPN" SG_ 2566881299 Absolute_Position_Offset 516779;
BA_ "SPN" SG_ 2566881299 Absolute_Position_Sensor_Raw_Val 516752;
BA_ "SPN" SG_ 2566881299 pEPS_SAS_Calibrated 517203;
BA_ "SPN" SG_ 2566881299 Assist_Curve_Vehicle_Speed 517143;
BA_ "SPN" SG_ 2566881299 Low_Res_Shaft_Position 517247;
BA_ "SPN" SG_ 2566913811 Throttle_Position_Sensor_1 517134;
BA_ "SPN" SG_ 2566913811 Engine_Speed 517150;
BA_ "SPN" SG_ 2566913811 Engine_Temperature_Sensor 516965;
BA_ "SPN" SG_ 2566913811 Manifold_Absolute_Pressure_Senso 516976;
BA_ "SPN" SG_ 2566913811 Intake_Air_Temperature_Sensor 516728;
BA_ "SPN" SG_ 2566913811 Vehicle_Electric_Power 516289;
BA_ "SPN" SG_ 2566882579 EPS_DC_Link_Voltage 516651;
BA_ "SPN" SG_ 2566882579 Phase_A_Motor_Current 516324;
BA_ "SPN" SG_ 2566882579 Phase_B_Motor_Current 517004;
BA_ "SPN" SG_ 2566882579 Phase_C_Motor_Current 516739;
BA_ "SPN" SG_ 2566913555 Throttle_Position 516621;
BA_ "SPN" SG_ 2566913555 Engine_Temperature 517259;
BA_ "SPN" SG_ 2566913555 Intake_Air_Temperature 517271;
BA_ "SPN" SG_ 2566913555 Manifold_Absolute_Pressure 516563;
BA_ "SPN" SG_ 2566913555 Boost_Pressure 517225;
BA_ "SPN" SG_ 2566913555 Barometric_Pressure 516749;
BA_ "SPN" SG_ 2566913555 Vehicle_Speed 516772;
BA_ "SPN" SG_ 2566913555 Barometric_Pressure_Sensor 516994;
BA_ "SPN" SG_ 2566910493 Hazard_Switch_Input 517413;
BA_ "SPN" SG_ 2566910493 LowHigh_Beam_Input 517402;
BA_ "SPN" SG_ 2566910493 Fog_Light_Input 517289;
BA_ "SPN" SG_ 2566910493 Horn_Input 517430;
BA_ "SPN" SG_ 2566910493 High_Beam_Output 517311;
BA_ "SPN" SG_ 2566910493 Low_Beam_Output 517381;
BA_ "SPN" SG_ 2566910493 Left_Fog_Light_Output 517337;
BA_ "SPN" SG_ 2566910493 Right_Fog_Light_Output 517293;
BA_ "SPN" SG_ 2566910493 Unlock_Input 517439;
BA_ "SPN" SG_ 2566910493 Lock_Input 517387;
BA_ "SPN" SG_ 2566910493 Windsheild_Switch_Up_Input 517334;
BA_ "SPN" SG_ 2566910493 Windsheild_Switch_Down_Input 517315;
BA_ "SPN" SG_ 2566910493 Horn_Output 517469;
BA_ "SPN" SG_ 2566910493 Hazard_Light_Output 517298;
BA_ "SPN" SG_ 2566910493 Tail_Light_Output 517420;
BA_ "SPN" SG_ 2566910493 Brake_Light_Output 517412;
BA_ "SPN" SG_ 2566910493 Left_Front_Turn_Signal_Output 517459;
BA_ "SPN" SG_ 2566910493 Right_Front_Turn_Signal_Output 517388;
BA_ "SPN" SG_ 2566910493 Left_Rear_Turn_Signal_Output 517408;
BA_ "SPN" SG_ 2566910493 Right_Rear_Turn_Signal_Output 517358;
BA_ "SPN" SG_ 2566910493 Secondary_Air_Valve_Output 517292;
BA_ "SPN" SG_ 2566910493 Secondary_Air_Valve_Command 517342;
BA_ "SPN" SG_ 2566910493 Heated_Grip_Heat_Increase_Switch 517416;
BA_ "SPN" SG_ 2566910493 Heated_Grip_Heat_Decrease_Switch 517328;
BA_ "SPN" SG_ 2566910493 pOperator_Button_1 517302;
BA_ "SPN" SG_ 2566910493 pOperator_Button_2 517401;
BA_ "SPN" SG_ 2566910493 pSide_Stand_Switch 517350;
BA_ "SPN" SG_ 2566910493 Coolant_Fluid_Level_Switch 517455;
BA_ "SPN" SG_ 2566910493 Driveline_Momentary_Left 517304;
BA_ "SPN" SG_ 2566910493 Driveline_Momentary_Right 517403;
BA_ "SPN" SG_ 2566910493 Seatbelt_Switch 517329;
BA_ "SPN" SG_ 2566910493 Brake_Fluid_Level_Switch 517305;
BA_ "SPN" SG_ 2566907933 Tire_Pressure_Front_Left_or_Only 516297;
BA_ "SPN" SG_ 2566907933 Tire_Pressure_Front_Right 516493;
BA_ "SPN" SG_ 2566907933 Tire_Pressure_Rear_Left_or_Only_ 517253;
BA_ "SPN" SG_ 2566907933 Tire_Pressure_Rear_Right 517003;
BA_ "SPN" SG_ 2566907933 Last_Received_Key_Fob_ID_Byte_1 516298;
BA_ "SPN" SG_ 2566907933 Last_Received_Key_Fob_ID_Byte_2 516653;
BA_ "SPN" SG_ 2566907933 Last_Received_Key_Fob_ID_Byte_3 517284;
BA_ "SPN" SG_ 2566907933 Last_Received_Key_Fob_ID_Byte_4 517144;
BA_ "SPN" SG_ 2566907677 Number_of_Discovered_Key_Fobs 517236;
BA_ "SPN" SG_ 2566907677 LeanAngle 517105;
BA_ "SPN" SG_ 2566856221 Switched_Power_Output_Status 517372;
BA_ "SPN" SG_ 2566856221 K15_Output_Status 517436;
BA_ "SPN" SG_ 2566856221 Lock_Motor_Driver_Status 517395;
BA_ "SPN" SG_ 2566856221 Homelink_1_Output_Status 517456;
BA_ "SPN" SG_ 2566856221 Homelink_2_Output_Status 517424;
BA_ "SPN" SG_ 2566856221 Windshield_Output_Status 517296;
BA_ "SPN" SG_ 2566856221 Puddle_Light_Driver_Status 517426;
BA_ "SPN" SG_ 2566856221 Puddle_Light_Enable_Status 517407;
BA_ "SPN" SG_ 2566856221 Fuel_Door_Switch_Input_Status 517467;
BA_ "SPN" SG_ 2566856221 VCM_Location_Pin_Status 517480;
BA_ "SPN" SG_ 2566856221 Fuel_Lock_Motor_Driver_Status 517316;
BA_ "SPN" SG_ 2566856221 Accent_Lights_Output_Status 517363;
BA_ "SPN" SG_ 2566887727 Compression_Valve_Driver_Current 516666;
BA_ "SPN" SG_ 2566887727 Compression_Valve_Driver_Current 516614;
BA_ "SPN" SG_ 2566887727 Compression_Valve_Driver_Current 517124;
BA_ "SPN" SG_ 2566887727 Compression_Valve_Driver_Current 516755;
BA_ "SPN" SG_ 2566887727 Suspension_Mode_Switch_Input_Vol 516284;
BA_ "SPN" SG_ 2566887727 Shock_Valve_Supply_Relay_Status 516518;
BA_ "SPN" SG_ 2566887727 Steering_Angle_Adaption_Offset 516954;
BA_ "SPN" SG_ 2566888751 Compression_Valve_Driver_Current 516963;
BA_ "SPN" SG_ 2566888751 Compression_Valve_Driver_Current 516484;
BA_ "SPN" SG_ 2566888751 Compression_Valve_Driver_Current 516950;
BA_ "SPN" SG_ 2566888751 Compression_Valve_Driver_Current 516789;
BA_ "SPN" SG_ 2566888751 Rebound_Valve_Driver_Current_Cmd 516714;
BA_ "SPN" SG_ 2566888751 Rebound_Valve_Driver_Current_Cmd 517126;
BA_ "SPN" SG_ 2566888751 Rebound_Valve_Driver_Current_Cmd 516618;
BA_ "SPN" SG_ 2566888751 Rebound_Valve_Driver_Current_Cmd 516282;
BA_ "SPN" SG_ 2566889007 Rebound_Valve_Driver_Current_fb_ 517067;
BA_ "SPN" SG_ 2566889007 Rebound_Valve_Driver_Current_fb_ 517230;
BA_ "SPN" SG_ 2566889007 Rebound_Valve_Driver_Current_fb_ 517005;
BA_ "SPN" SG_ 2566889007 Rebound_Valve_Driver_Current_fb_ 516627;
BA_ "SPN" SG_ 2364543791 Pitch_Angle 3318;
BA_ "SPN" SG_ 2364543791 Roll_Angle 3319;
BA_ "SPN" SG_ 2364543791 Pitch_Rate 3322;
BA_ "SPN" SG_ 2364543791 Pitch_Angle_Figure_of_Merit 3323;
BA_ "SPN" SG_ 2364543791 Roll_Angle_Figure_of_Merit 3324;
BA_ "SPN" SG_ 2364543791 Pitch_Rate_Figure_of_Merit 3325;
BA_ "SPN" SG_ 2364543791 Pitch_and_Roll_Compensated 3326;
BA_ "SPN" SG_ 2364543791 Roll_and_Pitch_Measurement_Laten 3327;
BA_ "SPN" SG_ 2566889263 Compression_Valve_Resistance__FL 517080;
BA_ "SPN" SG_ 2566889263 Compression_Valve_Resistance__FR 516273;
BA_ "SPN" SG_ 2566889263 Compression_Valve_Resistance__RL 516497;
BA_ "SPN" SG_ 2566889263 Compression_Valve_Resistance__RR 517193;
BA_ "SPN" SG_ 2566889263 Rebound_Valve_Resistance__FL 516754;
BA_ "SPN" SG_ 2566889263 Rebound_Valve_Resistance__FR 516680;
BA_ "SPN" SG_ 2566889263 Rebound_Valve_Resistance__RL 516940;
BA_ "SPN" SG_ 2566889263 Rebound_Valve_Resistance__RR 517157;
BA_ "SPN" SG_ 2566913547 Throttle_Position 516621;
BA_ "SPN" SG_ 2566913547 Engine_Temperature 517259;
BA_ "SPN" SG_ 2566913547 Intake_Air_Temperature 517271;
BA_ "SPN" SG_ 2566913547 Manifold_Absolute_Pressure 516563;
BA_ "SPN" SG_ 2566913547 Boost_Pressure 517225;
BA_ "SPN" SG_ 2566913547 Barometric_Pressure 516749;
BA_ "SPN" SG_ 2566913547 Vehicle_Speed 516772;
BA_ "SPN" SG_ 2566913547 Barometric_Pressure_Sensor 516994;
BA_ "SPN" SG_ 2566910208 bEnable 517290;
BA_ "SPN" SG_ 2566910208 bBatt 517449;
BA_ "SPN" SG_ 2566910208 bNotRun 517454;
BA_ "SPN" SG_ 2566910208 bOper 517429;
BA_ "SPN" SG_ 2566910208 b10Sec 517447;
BA_ "SPN" SG_ 2566910208 bManCyc 517370;
BA_ "SPN" SG_ 2566910208 bLazyCRC 517415;
BA_ "SPN" SG_ 2566910208 bSpare_11b 517464;
BA_ "SPN" SG_ 2566910208 DRL_Right 517382;
BA_ "SPN" SG_ 2566910208 DRL_Left 517476;
BA_ "SPN" SG_ 2566876695 pHydraulic_Oil_Temp_Status 524074;
BA_ "SPN" SG_ 2566876695 pHydraulic_Oil_Pressure_Status 524075;
BA_ "SPN" SG_ 2566876695 pEngine_Oil_Pressure_Status 524076;
BA_ "SPN" SG_ 2633984791 pInstrumentation_Backlight_Inten 524015;
BA_ "SPN" SG_ 2633984791 pFuel_Economy_Data_Source 524094;
BA_ "SPN" SG_ 2633984791 pActive_Decent_Control_ADC_Mode_ 524143;
BA_ "SPN" SG_ 2633984791 pFuel_Level_Data_Source 524091;
BA_ "SPN" SG_ 2633984791 pVehicle_Units_Configuration 524093;
BA_ "SPN" SG_ 2633984791 pLow_Fuel_Light_ON_Percentage 524090;
BA_ "SPN" SG_ 2633984791 pSeat_Belt_Input_Source 524095;
BA_ "SPN" SG_ 2633984791 pAWD_Mode_Availability 524142;
BA_ "SPN" SG_ 2633984791 pWarning_Lamp_Intensity 524016;
BA_ "SPN" SG_ 2633984791 pTurf_Mode_Availability 524140;
BA_ "SPN" SG_ 2633984791 pFuel_Tank_Volume 524089;
BA_ "SPN" SG_ 2633984791 pDisplayed_Speed_Correction_Fact 524014;
BA_ "SPN" SG_ 2566846231 Key_Switch_Battery_Potential 158;
BA_ "SPN" SG_ 2566846231 Alternator_Current 115;
BA_ "SPN" SG_ 2566846231 Charging_System_Potential_Voltag 167;
BA_ "SPN" SG_ 2566846231 SLI_Battery_1_Net_Current 114;
BA_ "SPN" SG_ 2566846231 Battery_Potential__Power_Input_1 168;
BA_ "SPN" SG_ 2633984577 pHeated_Grip_Enable 520366;
BA_ "SPN" SG_ 2633984577 pUser_PIN_Access_Status 516128;
BA_ "SPN" SG_ 2633984577 pActive_Descent_Control_ADC_Stat 524013;
BA_ "SPN" SG_ 2633984577 pCruise_Control_Set_Status 524097;
BA_ "SPN" SG_ 2633984577 pTether_Switch_Status 520600;
BA_ "SPN" SG_ 2633984577 pHigh_Beam_Indicator_Status 524084;
BA_ "SPN" SG_ 2633984577 pLow_Fuel_Indicator_Status 524087;
BA_ "SPN" SG_ 2633984577 pHeated_Grips_Percentage 524096;
BA_ "SPN" SG_ 2633984577 pSide_Stand_Status 524270;
BA_ "SPN" SG_ 2633984577 pTurf_Mode_Requested 524136;
BA_ "SPN" SG_ 2633984577 pEngine_Idle_Shutdown_Timer 516223;
BA_ "SPN" SG_ 2633984577 Operator_Not_in_Operating_Statio 520247;
BA_ "SPN" SG_ 2633984577 pAWD_Mode_Requested 524138;
BA_ "SPN" SG_ 2633984577 pHeated_Grips_Up_Switch_Status 516129;
BA_ "SPN" SG_ 2633984577 pTreadle_Neutral_Status 524017;
BA_ "SPN" SG_ 2633984577 pHeated_Grips_Down_Switch_Status 516130;
BA_ "SPN" SG_ 2633984577 pPark_Brake_Indicator_Status 524271;
BA_ "SPN" SG_ 2633984577 pRWD_Mode_Requested 524137;
BA_ "SPN" SG_ 2633984577 pSeat_Belt_Indicator_Status 524092;
BA_ "SPN" SG_ 2633984577 pSecurity_Light_Immobilizer_Stat 524019;
BA_ "SPN" SG_ 2633984577 ECU_Security_Status 516202;
BA_ "SPN" SG_ 2633984577 pActive_Decent_Control_ADC_Mode_ 524139;
BA_ "SPN" SG_ 2633984577 pTreadle_Reverse_Status 524018;
BA_ "SPN" SG_ 2566877249 pRadio_Input_Device 524099;
BA_ "SPN" SG_ 2566877249 pScreen_Area_Configuration 524107;
BA_ "SPN" SG_ 2566877249 pRadio_Input_Value 524100;
BA_ "SPN" SG_ 2566877249 pStereo_Status 524103;
BA_ "SPN" SG_ 2566877249 pText_Line_Configuration 524102;
BA_ "SPN" SG_ 2566877249 pHighlight_Row 524119;
BA_ "SPN" SG_ 2566877249 pScreen_Area_Mode 524132;
BA_ "SPN" SG_ 2566877249 pFirst_Row_Configuration 524106;
BA_ "SPN" SG_ 2566877249 pRadio_Scaling_Of_SPN_524100 524101;
BA_ "SPN" SG_ 2566845761 Ambient_Air_Temperature 171;
BA_ "SPN" SG_ 2566845761 Barometric_Pressure 108;
BA_ "SPN" SG_ 2566845761 Road_Surface_Temperature 79;
BA_ "SPN" SG_ 2566845761 Engine_Intake_1_Air_Temperature 172;
BA_ "SPN" SG_ 2231316801 pPlow_Down_State 516252;
BA_ "SPN" SG_ 2231316801 pWinch_In_Commanded_State 516247;
BA_ "SPN" SG_ 2231316801 pWinch_Out_Commanded_State 516248;
BA_ "SPN" SG_ 2231316801 pPlow_Mode_State 516251;
BA_ "SPN" SG_ 2231316801 pWinch_Auto_Stop_Signal 516246;
BA_ "SPN" SG_ 2231317569 pWinch_In_Relay_Control_Voltage 516253;
BA_ "SPN" SG_ 2231317569 pWinch_Out_Relay_Control_Voltage 516254;
BA_ "SPN" SG_ 2231317569 pAutostop_Signal_Voltage 516255;
BA_ "SPN" SG_ 2566888001 pAntiTheft_Component_Status_Indi 521196;
BA_ "SPN" SG_ 2566888001 pAntiTheft_Command_States 521201;
BA_ "SPN" SG_ 2566888001 pAntiTheft_Pin_Presence 516227;
BA_ "SPN" SG_ 2566888001 pAntiTheft_Pin_Parameter 516228;
BA_ "SPN" SG_ 2365555078 pOperator_Switch_Status_3 523964;
BA_ "SPN" SG_ 2365555078 pUpPaddleStatus 520405;
BA_ "SPN" SG_ 2365555078 pOperator_Switch_Status_2 523963;
BA_ "SPN" SG_ 2365555078 pDwPaddleStatus 520406;
BA_ "SPN" SG_ 2365555078 pOperator_Button_50_Pucker 523962;
BA_ "SPN" SG_ 2566844806 Cruise_Control_Set_Speed 86;
BA_ "SPN" SG_ 2566844806 Cruise_Control_Active 595;
BA_ "SPN" SG_ 2566844806 Clutch_Switch 598;
BA_ "SPN" SG_ 2566844806 Brake_Switch 597;
BA_ "SPN" SG_ 2566844806 pCC_Message_Counter 524080;
BA_ "SPN" SG_ 2566844806 Cruise_Control_Pause_Switch 1633;
BA_ "SPN" SG_ 2566844806 Cruise_Control_Set_Switch 599;
BA_ "SPN" SG_ 2566844806 Two_Speed_Axle_Switch 69;
BA_ "SPN" SG_ 2566844806 Cruise_Control_Enable_Switch 596;
BA_ "SPN" SG_ 2566844806 pOdometer_Drive_Bit 523994;
BA_ "SPN" SG_ 2566844806 pCC_Checksum 524079;
BA_ "SPN" SG_ 2566844806 WheelBased_Vehicle_Speed 84;
BA_ "SPN" SG_ 2566844806 Cruise_Control_Resume_Switch 601;
BA_ "SPN" SG_ 2566844806 Cruise_Control_Accelerate_Switch 602;
BA_ "SPN" SG_ 2566844806 pCruise_Enable_Status 524108;
BA_ "SPN" SG_ 2566844806 Parking_Brake_Switch 70;
BA_ "SPN" SG_ 2566844806 Cruise_Control_Coast_Decelerate_ 600;
BA_ "SPN" SG_ 2432656774 Key_Fob_Unlock_Button_Status 524044;
BA_ "SPN" SG_ 2432656774 Homelink_2 524037;
BA_ "SPN" SG_ 2432656774 Side_Stand_Switch 524098;
BA_ "SPN" SG_ 2432656774 Key_Fob_Lock_Button_Status 524043;
BA_ "SPN" SG_ 2432656774 Windshield__2_Down 524034;
BA_ "SPN" SG_ 2432656774 Turn__3_Cancel 524052;
BA_ "SPN" SG_ 2432656774 Reverse 524039;
BA_ "SPN" SG_ 2432656774 Hazard 524051;
BA_ "SPN" SG_ 2432656774 Homelink_1 524038;
BA_ "SPN" SG_ 2432656774 Windshield__1_Up 524035;
BA_ "SPN" SG_ 2432656774 Front_Brake_Switch 520322;
BA_ "SPN" SG_ 2432656774 Instrument_Cluster_Control__2 524058;
BA_ "SPN" SG_ 2432656774 Chassis_Unlock_Button_Status 524042;
BA_ "SPN" SG_ 2432656774 Power_Button 520362;
BA_ "SPN" SG_ 2432656774 RunStop_Switch 524040;
BA_ "SPN" SG_ 2432656774 Headlamp__2_High 524056;
BA_ "SPN" SG_ 2432656774 Instrument_Cluster_Control__1 524059;
BA_ "SPN" SG_ 2432656774 Clutch_Switch 524032;
BA_ "SPN" SG_ 2432656774 Start 524046;
BA_ "SPN" SG_ 2432656774 Headlamp__3_Driving 524055;
BA_ "SPN" SG_ 2432656774 Cruise__2_Set 524049;
BA_ "SPN" SG_ 2432656774 Windshield_Wiper 524041;
BA_ "SPN" SG_ 2432656774 Fog 524045;
BA_ "SPN" SG_ 2432656774 Cruise__3_Accel 524048;
BA_ "SPN" SG_ 2432656774 Horn 524047;
BA_ "SPN" SG_ 2432656774 Turn__2_Right 524053;
BA_ "SPN" SG_ 2432656774 Cruise__1_On 524050;
BA_ "SPN" SG_ 2432656774 Turn__1_Left 524054;
BA_ "SPN" SG_ 2432656774 Throttle_Safety_Switch__1 524036;
BA_ "SPN" SG_ 2432656774 Headlamp__1_Low 524057;
BA_ "SPN" SG_ 2432656774 Chassis_Lock_Switch_Status 516131;
BA_ "SPN" SG_ 2432656774 Fuel_Door_Unlock_Button_Status 516191;
BA_ "SPN" SG_ 2566877830 pRight_Hand_Grip_Temperature 524110;
BA_ "SPN" SG_ 2566877830 pDriver_Seat_Temperature 516453;
BA_ "SPN" SG_ 2566877830 pPassenger_Seat_Temperature 516454;
BA_ "SPN" SG_ 2566877830 pLeft_Hand_Grip_Temperature 524109;
BA_ "SPN" SG_ 2365531796 pButton1_Function 516269;
BA_ "SPN" SG_ 2365531796 pButton1_Status 516271;
BA_ "SPN" SG_ 2365531796 pButton2_Function 516274;
BA_ "SPN" SG_ 2365531796 pButton2_Status 516276;
BA_ "SPN" SG_ 2365531796 pButton3_Function 516287;
BA_ "SPN" SG_ 2365531796 pButton3_Status 516288;
BA_ "SPN" SG_ 2365531796 pButton4_Function 516293;
BA_ "SPN" SG_ 2365531796 pButton4_Status 516295;
BA_ "SPN" SG_ 2365531796 pButton5_Function 516296;
BA_ "SPN" SG_ 2365531796 pButton5_Status 516299;
BA_ "SPN" SG_ 2365531796 pRotaryKnob_Function 516303;
BA_ "SPN" SG_ 2365531796 pRotaryKnob_Status 516304;
BA_ "SPN" SG_ 2365531796 pRotaryKnob_Position 516395;
BA_ "SPN" SG_ 2365531796 pRotaryKnob_DetentsSinceLastTX 516396;
BA_ "SPN" SG_ 2365531796 pRCM_Message_Counter 516433;
BA_ "SPN" SG_ 2566896687 AX_RQI 516956;
BA_ "SPN" SG_ 2566896687 AY_RQI 516599;
BA_ "SPN" SG_ 2566896687 AZ_RQI 516502;
BA_ "SPN" SG_ 2566896687 AgrAYRQI 517160;
BA_ "SPN" SG_ 2566896687 AgrAXRQI 516753;
BA_ "SPN" SG_ 2566896687 Total_Vehicle_RQI 516625;
BA_ "SPN" SG_ 2365531155 pEPSReqMod 516147;
BA_ "SPN" SG_ 2298415360 pJunction_Temp 524203;
BA_ "SPN" SG_ 2298415360 pCapacitor_Temp 524202;
BA_ "SPN" SG_ 2298415360 pMotor_Temp_Margin 524198;
BA_ "SPN" SG_ 2298415360 pBaseplate_Temp 524199;
BA_ "SPN" SG_ 2298415360 pBoard_Temp 524200;
BA_ "SPN" SG_ 2298415360 pController_Temp_Margin 524197;
BA_ "SPN" SG_ 2298415360 pTemperature_Message_Checksum 524251;
BA_ "SPN" SG_ 2298415360 pMotor_Temp 524201;
BA_ "SPN" SG_ 2365525760 pSOC 524220;
BA_ "SPN" SG_ 2365525760 pAvailable_Wh 524221;
BA_ "SPN" SG_ 2365525760 pWh_in_Since_key_on 524222;
BA_ "SPN" SG_ 2365525760 pEnergy_Message_Checksum 524253;
BA_ "SPN" SG_ 2298428672 pVehicle_Pitch_Angle 516617;
BA_ "SPN" SG_ 2298428672 Engine_Operating_State 3543;
BA_ "SPN" SG_ 2298428672 pWarmup_cycle_detection_status 516642;
BA_ "SPN" SG_ 2298428672 pDrive_cycle_detection_status 516637;
BA_ "SPN" SG_ 2298428672 pDrive_Mode 516624;
BA_ "SPN" SG_ 2298428672 Driveline_Mode 520651;
BA_ "SPN" SG_ 2298414848 pPerformance_Message_Checksum 524249;
BA_ "SPN" SG_ 2298414848 pLower_Available_Torque_Limit 524193;
BA_ "SPN" SG_ 2298414848 pPerformance_State 524190;
BA_ "SPN" SG_ 2298414848 pActual_Motor_Torque 524191;
BA_ "SPN" SG_ 2298414848 pUpper_Available_Torque_Limit 524192;
BA_ "SPN" SG_ 2298414848 pActual_Motor_Velocity 524194;
BA_ "SPN" SG_ 2298414848 pPer_Msg_Count 520606;
BA_ "SPN" SG_ 2365525504 pPack_Voltage 524217;
BA_ "SPN" SG_ 2365525504 pDischarge_Limit 524218;
BA_ "SPN" SG_ 2365525504 pPack_Current 524216;
BA_ "SPN" SG_ 2365525504 pBMC_Power_Message_Checksum 524252;
BA_ "SPN" SG_ 2365525504 pCharge_Limit 524219;
BA_ "SPN" SG_ 2566799360 High_Beam_Head_Light_Data 2348;
BA_ "SPN" SG_ 2566799360 Low_Beam_Head_Light_Data 2350;
BA_ "SPN" SG_ 2566799360 Running_Light 2404;
BA_ "SPN" SG_ 2566799360 Left_Turn_Signal_Lights 2368;
BA_ "SPN" SG_ 2566799360 Right_Turn_Signal_Lights 2370;
BA_ "SPN" SG_ 2566799360 Left_Stop_Light 2372;
BA_ "SPN" SG_ 2566799360 Right_Stop_Light 2374;
BA_ "SPN" SG_ 2566799360 Tractor_Front_Fog_Lights 2388;
BA_ "SPN" SG_ 2566799360 Implement_OEM_Option_1_Light 2396;
BA_ "SPN" SG_ 2566799360 Implement_OEM_Option_2_Light 2398;
BA_ "SPN" SG_ 2365526528 pCharger_Temp 524236;
BA_ "SPN" SG_ 2365526528 pCharger_Voltage 524235;
BA_ "SPN" SG_ 2365526528 pCharger_Status_Counter 524237;
BA_ "SPN" SG_ 2365526528 pCharger_State 524239;
BA_ "SPN" SG_ 2365526528 pCharger_Status_Message_Checksum 524256;
BA_ "SPN" SG_ 2365526528 pAC_Status 524238;
BA_ "SPN" SG_ 2365526528 pCharger_Current 524234;
BA_ "SPN" SG_ 2365526016 pSOH 524223;
BA_ "SPN" SG_ 2365526016 pBattery_Temp_Max 524224;
BA_ "SPN" SG_ 2365526016 pK_battemp 524225;
BA_ "SPN" SG_ 2365526016 pFloat_State 524226;
BA_ "SPN" SG_ 2365526016 pBattery_Temp_Min 524282;
BA_ "SPN" SG_ 2365526016 pTraction_Battery_Status_Message 524254;
BA_ "SPN" SG_ 2298415104 pController_Thermal_Cutback_Stat 524259;
BA_ "SPN" SG_ 2298415104 pCapacitor_Voltage 524196;
BA_ "SPN" SG_ 2298415104 pMotor_Power_Cutback_Status 524240;
BA_ "SPN" SG_ 2298415104 pInput_Current 524195;
BA_ "SPN" SG_ 2298415104 pMotor_Thermal_Cutback_Status 524260;
BA_ "SPN" SG_ 2298415104 pInput_DC_Current_Cutback_Status 524257;
BA_ "SPN" SG_ 2298415104 pSpeed_Limit_Cutback_Status 524258;
BA_ "SPN" SG_ 2298415104 pPower_Message_Checksum 524250;
BA_ "SPN" SG_ 2566895895 pSetpoint_Grips_Hand_Medium 516352;
BA_ "SPN" SG_ 2566895895 pSetpoint_Grips_Hand_Low 516353;
BA_ "SPN" SG_ 2566895895 pSetpoint_Grip_Thumb_Medium 516355;
BA_ "SPN" SG_ 2566895895 pAccessory_Control_Operation 516349;
BA_ "SPN" SG_ 2566895895 pSetpoint_Grips_Hand_High 516351;
BA_ "SPN" SG_ 2566895895 pAccessory_Control_Mode 516350;
BA_ "SPN" SG_ 2566895895 pSetpoint_Grip_Thumb_High 516354;
BA_ "SPN" SG_ 2566895895 pSetpoint_Grip_Thumb_Low 516356;
BA_ "SPN" SG_ 2566877207 pRadio_Input_Device 524099;
BA_ "SPN" SG_ 2566877207 pScreen_Area_Configuration 524107;
BA_ "SPN" SG_ 2566877207 pRadio_Input_Value 524100;
BA_ "SPN" SG_ 2566877207 pStereo_Status 524103;
BA_ "SPN" SG_ 2566877207 pText_Line_Configuration 524102;
BA_ "SPN" SG_ 2566877207 pHighlight_Row 524119;
BA_ "SPN" SG_ 2566877207 pScreen_Area_Mode 524132;
BA_ "SPN" SG_ 2566877207 pFirst_Row_Configuration 524106;
BA_ "SPN" SG_ 2566877207 pRadio_Scaling_Of_SPN_524100 524101;
BA_ "SPN" SG_ 2633984535 pHeated_Grip_Enable 520366;
BA_ "SPN" SG_ 2633984535 pUser_PIN_Access_Status 516128;
BA_ "SPN" SG_ 2633984535 pActive_Descent_Control_ADC_Stat 524013;
BA_ "SPN" SG_ 2633984535 pCruise_Control_Set_Status 524097;
BA_ "SPN" SG_ 2633984535 pTether_Switch_Status 520600;
BA_ "SPN" SG_ 2633984535 pHigh_Beam_Indicator_Status 524084;
BA_ "SPN" SG_ 2633984535 pLow_Fuel_Indicator_Status 524087;
BA_ "SPN" SG_ 2633984535 pHeated_Grips_Percentage 524096;
BA_ "SPN" SG_ 2633984535 pSide_Stand_Status 524270;
BA_ "SPN" SG_ 2633984535 pTurf_Mode_Requested 524136;
BA_ "SPN" SG_ 2633984535 pEngine_Idle_Shutdown_Timer 516223;
BA_ "SPN" SG_ 2633984535 Operator_Not_in_Operating_Statio 520247;
BA_ "SPN" SG_ 2633984535 pAWD_Mode_Requested 524138;
BA_ "SPN" SG_ 2633984535 pHeated_Grips_Up_Switch_Status 516129;
BA_ "SPN" SG_ 2633984535 pTreadle_Neutral_Status 524017;
BA_ "SPN" SG_ 2633984535 pHeated_Grips_Down_Switch_Status 516130;
BA_ "SPN" SG_ 2633984535 pPark_Brake_Indicator_Status 524271;
BA_ "SPN" SG_ 2633984535 pRWD_Mode_Requested 524137;
BA_ "SPN" SG_ 2633984535 pSeat_Belt_Indicator_Status 524092;
BA_ "SPN" SG_ 2633984535 pSecurity_Light_Immobilizer_Stat 524019;
BA_ "SPN" SG_ 2633984535 ECU_Security_Status 516202;
BA_ "SPN" SG_ 2633984535 pActive_Decent_Control_ADC_Mode_ 524139;
BA_ "SPN" SG_ 2633984535 pTreadle_Reverse_Status 524018;
BA_ "SPN" SG_ 2566875159 pFuel_Type_Selected 524007;
BA_ "SPN" SG_ 2566875159 pFuel_Type_Sensor 524008;
BA_ "SPN" SG_ 2566862113 pSuspPosn 516544;
BA_ "SPN" SG_ 2566862113 pRotSnsr 516548;
BA_ "SPN" SG_ 2566862113 pMinEndPtSaved 516554;
BA_ "SPN" SG_ 2566862113 pMaxEndPtSaved 516549;
BA_ "SPN" SG_ 2566871696 pEPreloadDriverMaxWeight 516577;
BA_ "SPN" SG_ 2566871696 pEPreloadDriverMinWeight 516578;
BA_ "SPN" SG_ 2566871696 pEPreloadPassengerMaxWeight 516579;
BA_ "SPN" SG_ 2566871696 pEPreloadPassengerMinWeight 516582;
BA_ "SPN" SG_ 2566871696 pEPreloadLuggageMaxWeight 516587;
BA_ "SPN" SG_ 2566871696 pEPreloadTrunkMaxWeight 516589;
BA_ "SPN" SG_ 2566871696 pEPreloadTotalMaxWeight 516590;
BA_ "SPN" SG_ 2566871696 pEPreloadFineTuneMax 516591;
BA_ "SPN" SG_ 2566870416 pSaveMaxEndPt 516555;
BA_ "SPN" SG_ 2566870416 pSaveMinEndPt 516559;
BA_ "SPN" SG_ 2566870416 pEPreloadFeatureStatus 516560;
BA_ "SPN" SG_ 2566870416 pEPreloadDriverWeight 516562;
BA_ "SPN" SG_ 2566870416 pEPreloadMovmtStatus 516567;
BA_ "SPN" SG_ 2566870416 pEPreloadPassengerWeight 516569;
BA_ "SPN" SG_ 2566870416 pEPreloadLuggageWeight 516570;
BA_ "SPN" SG_ 2566870416 pEPreloadTrunkWeight 516571;
BA_ "SPN" SG_ 2566870416 pEPreloadFineTune 516575;
BA_ "SPN" SG_ 2566870416 pEPreloadTotalWeight 516573;
BA_ "SPN" SG_ 2566870416 pEPreloadTrunkInstallStatus 516576;
BA_ "SPN" SG_ 2566872576 pBoostModeRequested 523966;
BA_ "SPN" SG_ 2566872576 pWastegateActuatorFeedback 523968;
BA_ "SPN" SG_ 2566872576 pBoostModeCommanded 523967;
BA_ "SPN" SG_ 2566872576 pPercentOfTargetBoost 523969;
BA_ "SPN" SG_ 2566872576 pBoostModeEnablement 523976;
BA_ "SPN" SG_ 2566872320 Engine_Break_In 516315;
BA_ "SPN" SG_ 2566909184 Port_Injector_2_Time_LSB 516513;
BA_ "SPN" SG_ 2566909184 Case_Injector_2_Time_LSB 517107;
BA_ "SPN" SG_ 2566909184 Cyl_2_Ignition_Timing 517135;
BA_ "SPN" SG_ 2566909184 Cyl_2_Base_Ignition_Timing 517111;
BA_ "SPN" SG_ 2566909184 Cyl_2_Ignition_Coil_Dwell 517072;
BA_ "SPN" SG_ 2566909184 Cyl_2_Ignition_Coil_Dwell 516937;
BA_ "SPN" SG_ 2566909440 Port_Injector_1_Time 516970;
BA_ "SPN" SG_ 2566909440 Case_Injector_1_Time 517008;
BA_ "SPN" SG_ 2566909440 Cyl_1_Ignition_Timing 516321;
BA_ "SPN" SG_ 2566909440 Cyl_1_Base_Ignition_Timing 516731;
BA_ "SPN" SG_ 2566909440 Cyl_1_Ignition_Coil_Dwell 516720;
BA_ "SPN" SG_ 2566909440 Cyl_1_Ignition_Coil_Dwell 516237;
BA_ "SPN" SG_ 2566900992 EV_Learn_Up_Position 516531;
BA_ "SPN" SG_ 2566900992 EV_Learn_Down_Position 516688;
BA_ "SPN" SG_ 2566900992 Auxillary_Injector_PW_MAG 517145;
BA_ "SPN" SG_ 2566900992 Auxillary_Injector_PW_PTO 517248;
BA_ "SPN" SG_ 2566905600 ECU_Power_Input_1 516601;
BA_ "SPN" SG_ 2566905600 ECU_Power_Input_2 516488;
BA_ "SPN" SG_ 2566905600 ECU_Power_Input_3 517287;
BA_ "SPN" SG_ 2566905600 Mixture_Adaption_High_Load_Bank_ 517485;
BA_ "SPN" SG_ 2566905600 Tire_Pressure_Spare 517486;
BA_ "SPN" SG_ 2566905600 AirFuel_Mixture_Status_Bank_1_F 517487;
BA_ "SPN" SG_ 2566905600 EGT_2 516990;
BA_ "SPN" SG_ 2566905600 AlphaN_Output_Fuel_Flow 517149;
BA_ "SPN" SG_ 2566905600 Fuel_Variance__DialBox 517115;
BA_ "SPN" SG_ 2566911744 Knock_Retard_Cylinder_1 516681;
BA_ "SPN" SG_ 2566911744 Knock_Retard_Cylinder_2 517084;
BA_ "SPN" SG_ 2566911744 Injection_DET_Correction_MAG 516989;
BA_ "SPN" SG_ 2566911744 Injection_DET_Correction_PTO 517109;
BA_ "SPN" SG_ 2566911744 Detonation_Voltage_LSB 517037;
BA_ "SPN" SG_ 2566911744 Detonation_Voltage_MSB 517201;
BA_ "SPN" SG_ 2566911744 Ignition_Variance 517049;
BA_ "SPN" SG_ 2566911744 Fuel_Variance_in_ 517036;
BA_ "SPN" SG_ 2566882304 Boost_Error 517140;
BA_ "SPN" SG_ 2566882304 Boost_Pressure_50kPA 516783;
BA_ "SPN" SG_ 2566882304 _of_Boost_Target 516280;
BA_ "SPN" SG_ 2566882304 Boost_Injection_Duration 516322;
BA_ "SPN" SG_ 2566882304 Boost_Fuel_Reduction 517278;
BA_ "SPN" SG_ 2566882304 Base_Target_Boost_Pressure 517093;
BA_ "SPN" SG_ 2566882304 Auxillary_Injector_Variance 517232;
BA_ "SPN" SG_ 2566897152 Boost_PID_P_Term 516542;
BA_ "SPN" SG_ 2566897152 Boost_PID_I_Term 516980;
BA_ "SPN" SG_ 2566897152 Boost_PID_D_Term 516656;
BA_ "SPN" SG_ 2566908928 Exhaust_Temperature 516258;
BA_ "SPN" SG_ 2566908928 InjectorIgnition_Supply_Voltage 516266;
BA_ "SPN" SG_ 2566908928 Electric_Start_Option_Battery_Vo 516912;
BA_ "SPN" SG_ 2566908928 Exhaust_Valve_Set_PWM 516973;
BA_ "SPN" SG_ 2566908928 Exhaust_Valve_Actual_Position 516329;
BA_ "SPN" SG_ 2566908928 Exhaust_Valve_Actual_Position 516660;
BA_ "SPN" SG_ 2566908928 EV_Actuator_Feedback_PWM 516526;
BA_ "GenMsgCycleTime" BO_ 2566884096 1000;
BA_ "GenMsgCycleTime" BO_ 2365530624 10;
BA_ "GenMsgCycleTime" BO_ 2364543791 10;
BA_ "GenMsgCycleTime" BO_ 2566876695 1000;
BA_ "GenMsgCycleTime" BO_ 2566846231 1000;
BA_ "GenMsgCycleTime" BO_ 2633984577 500;
BA_ "GenMsgCycleTimeFast" BO_ 2633984577 100;
BA_ "GenMsgCycleTime" BO_ 2566877249 1000;
BA_ "GenMsgCycleTime" BO_ 2566845761 1000;
BA_ "GenMsgCycleTime" BO_ 2231316801 500;
BA_ "GenMsgCycleTime" BO_ 2231317569 500;
BA_ "GenMsgCycleTime" BO_ 2365555078 100;
BA_ "GenMsgCycleTimeFast" BO_ 2365555078 10;
BA_ "GenMsgCycleTime" BO_ 2566844806 100;
BA_ "GenMsgCycleTime" BO_ 2432656774 200;
BA_ "GenMsgCycleTimeFast" BO_ 2432656774 100;
BA_ "GenMsgCycleTime" BO_ 2566877830 1000;
BA_ "GenMsgCycleTime" BO_ 2365531796 100;
BA_ "GenMsgCycleTimeFast" BO_ 2365531796 10;
BA_ "GenMsgCycleTime" BO_ 2365531155 500;
BA_ "GenMsgCycleTimeFast" BO_ 2365531155 10;
BA_ "GenMsgCycleTime" BO_ 2298415360 100;
BA_ "GenMsgCycleTime" BO_ 2365525760 100;
BA_ "GenMsgCycleTime" BO_ 2298428672 100;
BA_ "GenMsgCycleTime" BO_ 2298414848 10;
BA_ "GenMsgCycleTime" BO_ 2365525504 10;
BA_ "GenMsgCycleTime" BO_ 2566799360 1000;
BA_ "GenMsgCycleTimeFast" BO_ 2566799360 100;
BA_ "GenMsgCycleTime" BO_ 2365526528 100;
BA_ "GenMsgCycleTime" BO_ 2365526016 1000;
BA_ "GenMsgCycleTime" BO_ 2298415104 100;
BA_ "GenMsgCycleTime" BO_ 2566895895 1000;
BA_ "GenMsgCycleTimeFast" BO_ 2566895895 100;
BA_ "GenMsgCycleTime" BO_ 2566877207 1000;
BA_ "GenMsgCycleTime" BO_ 2633984535 500;
BA_ "GenMsgCycleTimeFast" BO_ 2633984535 100;
BA_ "GenMsgCycleTime" BO_ 2566875159 1000;
BA_ "GenMsgCycleTime" BO_ 2566862113 100;
BA_ "GenMsgCycleTimeFast" BO_ 2566871696 100;
BA_ "GenMsgCycleTime" BO_ 2566870416 1000;
BA_ "GenMsgCycleTimeFast" BO_ 2566870416 100;
BA_ "GenMsgCycleTime" BO_ 2566872576 200;
BA_ "GenMsgCycleTime" BO_ 2566872320 2000;
VAL_ 2566884096 Maximum_Vehicle_Speed_Limit_1_Av 2 "Error" 0 "Off" 1 "On" 3 "Not-Available" ;
VAL_ 2566884096 Maximum_Vehicle_Speed_Limit_4_Av 2 "Error" 0 "Off" 1 "On" 3 "Not-Available" ;
VAL_ 2566884096 Maximum_Vehicle_Speed_Limit_2_Av 2 "Error" 0 "Off" 1 "On" 3 "Not-Available" ;
VAL_ 2566884096 Maximum_Vehicle_Speed_Limit_5_Av 2 "Error" 0 "Off" 1 "On" 3 "Not-Available" ;
VAL_ 2566884096 Maximum_Vehicle_Speed_Limit_3_Av 2 "Error" 0 "Off" 1 "On" 3 "Not-Available" ;
VAL_ 2566884096 Maximum_Vehicle_Speed_Limit_7_Av 2 "Error" 0 "Off" 1 "On" 3 "Not-Available" ;
VAL_ 2566884096 Maximum_Vehicle_Speed_Limit_6_Av 2 "Error" 0 "Off" 1 "On" 3 "Not-Available" ;
VAL_ 2365530624 pRaw_Brake_Status 2 "Error" 0 "Off" 1 "On" 3 "Not-Available" ;
VAL_ 2365530624 pEngine_TorqueSpeed_Control_Requ 1 " Request denied due to ECM fault" 0 "Request granted" 2 "Request denied. Requested torque is out of range that engine can supply." 7 "Not Available" 6 "Error" 3 "Request denied. Engine Torque - Driver Demanded is lower than torque requested by Engine Control Requestor." ;
VAL_ 2566876695 pHydraulic_Oil_Temp_Status 0 "Error" 1 "OK" 2 "Not OK" 3 "Not Available" ;
VAL_ 2566876695 pHydraulic_Oil_Pressure_Status 0 "Error" 1 "OK" 2 "Not OK" 3 "Not Available" ;
VAL_ 2566876695 pEngine_Oil_Pressure_Status 0 "Error" 1 "OK" 2 "Not OK" 3 "Not Available" ;
VAL_ 2633984791 pFuel_Economy_Data_Source 0 "ECM to calculate" 2 "Error Indicator" 3 "Not Available" 1 "Gauge to calculate" ;
VAL_ 2633984791 pActive_Decent_Control_ADC_Mode_ 2 "Error" 0 "Off" 1 "On" 3 "Not-Available" ;
VAL_ 2633984791 pFuel_Level_Data_Source 0 "Analog" 3 "Not Available " 1 "CAN" 2 "Error" ;
VAL_ 2633984791 pVehicle_Units_Configuration 0 "US12: MPH, Fahrenheit, US Gallon, 12-Hour Clock, & PSI" 2 "INT12: km/h, Celsius, Liter, 12-Hour Clock, & kPa" 1 "US24: MPH, Fahrenheit, US Gallon, 24-Hour Clock, & PSI" 5 " UK24: MPH, Celsius, Imperial Gallon, 24-Hour Clock, & PSI" 14 "Error" 7 "Not Available" 3 "INT24: km/h, Celsius, Liter, 24-Hour Clock, & kPa" 4 "UK12: MPH, Celsius, Imperial Gallon, 12-Hour Clock, & PSI" ;
VAL_ 2633984791 pSeat_Belt_Input_Source 1 "Gauge to read switch input" 0 "ECM to read switch input" 3 "Not Available" 2 "Error" ;
VAL_ 2633984791 pAWD_Mode_Availability 2 "Error" 0 "Off" 1 "On" 3 "Not-Available" ;
VAL_ 2633984791 pTurf_Mode_Availability 2 "Error" 0 "Off" 1 "On" 3 "Not-Available" ;
VAL_ 2633984577 pHeated_Grip_Enable 2 "Error" 0 "Off" 1 "On" 3 "Not-Available" ;
VAL_ 2633984577 pUser_PIN_Access_Status 2 "Error" 0 "Off" 1 "On" 3 "Not-Available" ;
VAL_ 2633984577 pActive_Descent_Control_ADC_Stat 2 "Error" 0 "Off" 1 "On" 3 "Not-Available" ;
VAL_ 2633984577 pCruise_Control_Set_Status 2 "Error" 0 "Off" 1 "On" 3 "Not-Available" ;
VAL_ 2633984577 pTether_Switch_Status 2 "Error" 0 "Off" 1 "On" 3 "Not-Available" ;
VAL_ 2633984577 pHigh_Beam_Indicator_Status 2 "Error" 0 "Off" 1 "On" 3 "Not-Available" ;
VAL_ 2633984577 pLow_Fuel_Indicator_Status 2 "Error" 0 "Off" 1 "On" 3 "Not-Available" ;
VAL_ 2633984577 pSide_Stand_Status 2 "Error" 1 "Side Stand Extended" 0 "Side Stand Retracted" 3 "Not Available" ;
VAL_ 2633984577 pTurf_Mode_Requested 2 "Error" 0 "Off" 1 "On" 3 "Not-Available" ;
VAL_ 2633984577 Operator_Not_in_Operating_Statio 2 "Error" 0 "Off" 1 "On" 3 "Not-Available" ;
VAL_ 2633984577 pAWD_Mode_Requested 2 "Error" 0 "Off" 1 "On" 3 "Not-Available" ;
VAL_ 2633984577 pHeated_Grips_Up_Switch_Status 2 "Error" 0 "Off" 1 "On" 3 "Not-Available" ;
VAL_ 2633984577 pTreadle_Neutral_Status 2 "Error" 0 "Off" 1 "On" 3 "Not-Available" ;
VAL_ 2633984577 pHeated_Grips_Down_Switch_Status 2 "Error" 0 "Off" 1 "On" 3 "Not-Available" ;
VAL_ 2633984577 pPark_Brake_Indicator_Status 2 "Slow Flash (1 Hz, 50% duty cycle)" 7 "Not Available" 1 "On" 3 "Fast Flash (2 HZ or faster, 50% Duty Cycle)" 0 "Off" 6 "Error" ;
VAL_ 2633984577 pRWD_Mode_Requested 2 "Error" 0 "Off" 1 "On" 3 "Not-Available" ;
VAL_ 2633984577 pSeat_Belt_Indicator_Status 2 "Slow Flash (1 Hz, 50% duty cycle)" 7 "Not Available" 1 "On" 3 "Fast Flash (2 HZ or faster, 50% Duty Cycle)" 0 "Off" 6 "Error" ;
VAL_ 2633984577 pSecurity_Light_Immobilizer_Stat 2 "Error" 0 "Off" 1 "On" 3 "Not-Available" ;
VAL_ 2633984577 ECU_Security_Status 1 "Locked, Awaiting Unlock" 3 " Locked, system will shut down" 0 "Unlocked" 7 "Not Available" 2 "Locked, System will not shut down" 6 "Error" ;
VAL_ 2633984577 pActive_Decent_Control_ADC_Mode_ 2 "Error" 0 "Off" 1 "On" 3 "Not-Available" ;
VAL_ 2633984577 pTreadle_Reverse_Status 2 "Error" 0 "Off" 1 "On" 3 "Not-Available" ;
VAL_ 2566877249 pRadio_Input_Device 16 "AM" 8 "PANDORA" 11 "FM1" 12 "FM2" 9 "SIRIUS" 5 "NAV" 6 "MP3" 10 "FM" 15 "WX" 2 "XM" 13 "FM3" 3 "AUX" 1 "iPOD" 4 "USB" 7 "BT" 14 "FM4" 21 "ICOM" 19 "SW" 18 "MW" 20 "iHEART" 17 "LW" 22 "GMRS" 23 "CB" 33 "P3" 25 "GMRS RX" 35 "P5" 34 "P4" 32 "P2" 37 "P7" 24 "GMRS TX" 38 "P8" 31 "P1" 36 "P6" 40 "P10" 42 "P12" 45 "P15" 43 "P13" 39 "P9" 44 "P14" 41 "P11" 47 "P17" 50 "P20" 49 "P19" 46 "P16" 48 "P18" 92 "Incoming Text" 70 "BT VOL" 63 "Destination" 110 "BASS" 100 "Radio OFF" 80 "Thumbs UP" 91 "Incoming Call" 61 "Turn Left" 71 "BT VOL+" 72 "BT VOL-" 81 "Thumbs DOWN" 62 "Turn Right" 111 "TREBLE" 113 "BALANCE" 114 "AVC" 112 "MID" 115 "VOLUME (User Requested)" 116 "MUTE" 118 "AVC Compensated Volume " 123 "MID-BASS, + 1" 120 "MID-TREBLE" 121 "BASS, + 1" 119 "MID-BASS" 122 "MID-BASS, - 1" 117 "FADE" 128 "TREBLE, - 1" 127 "MID-TREBLE, + 1" 125 "MID, + 1" 124 "MID, - 1" 129 "TREBLE, + 1" 126 "MID-TREBLE, - 1" 130 "Number of User EQ Selection Bands" 135 "EQ Selection - Mid-Rear" 134 "EQ Selection - Rear" 133 "EQ Selection - Mid-Front" 131 "EQ Preset" 132 "EQ Selection - Front" 137 "Vehicle Configuration" 136 "BASS BOOST Setting" 254 "Error" 141 "Speakers Installed - Secondary" 249 "Request Setting" 255 "Not Available" 140 "Speakers Installed - Primary" ;
VAL_ 2566877249 pScreen_Area_Configuration 3 "Not Available" 1 "Expanded Screen Size" 2 "Error" 0 "Normal Screen Size" ;
VAL_ 2566877249 pStereo_Status 2 "Error" 0 "Off" 1 "On" 3 "Not-Available" ;
VAL_ 2566877249 pText_Line_Configuration 5 "5 lines of ASCII text being sent" 2 "2 lines of ASCII text being sent" 0 "0 lines of ASCII text being sent" 6 "6 lines of ASCII text being sent" 4 "4 lines of ASCII text being sent" 1 "1 lines of ASCII text being sent" 7 "Not Available" 3 "3 lines of ASCII text being sent" ;
VAL_ 2566877249 pHighlight_Row 15 "Not Available" 0 "No Row Highlighted" 14 "Error" ;
VAL_ 2566877249 pScreen_Area_Mode 0 "Normal Screen Display" 1 "Data List Being Transmitted" 7 "Not Available " 6 "Error" ;
VAL_ 2566877249 pFirst_Row_Configuration 0 "Data in SPN 524099, 524100, 524101 is ignored. First row will be in ASCII text" 7 "Not Available" 1 "Data in SPN 524099, 524100, 524101 will be shown in the first row" 2 "Data in SPN 524099, 524100, 524101 is ignored. First row will be blank. Row 2 is ASCII text" ;
VAL_ 2566877249 pRadio_Scaling_Of_SPN_524100 4 "-0.1/bit – show 1 decimal point, value is negative" 7 "Not Available" 2 "0.01/bit – show 2 decimal points" 1 "0.1/bit – show 1 decimal point" 6 "Do not show Input Value" 0 "1/bit" 5 "-0.01/bit – show 2 decimal points, value is negative" 3 "-1/bit – Value is negative" ;
VAL_ 2231316801 pPlow_Down_State 2 "Error" 0 "Off" 1 "On" 3 "Not-Available" ;
VAL_ 2231316801 pWinch_In_Commanded_State 2 "Error" 0 "Off" 1 "On" 3 "Not-Available" ;
VAL_ 2231316801 pWinch_Out_Commanded_State 2 "Error" 0 "Off" 1 "On" 3 "Not-Available" ;
VAL_ 2231316801 pPlow_Mode_State 7 "Not Available " 1 "Plow Mode Active, Normal Mode" 5 "Error State " 0 "Plow Mode Not Active" 2 "Plow Mode Active, Backdrag Mode" ;
VAL_ 2231316801 pWinch_Auto_Stop_Signal 2 "Error" 0 "Off" 1 "On" 3 "Not-Available" ;
VAL_ 2566888001 pAntiTheft_Component_Status_Indi 1 "Feature available, enabled, and component is Locked (do not allow to start)" 0 "Feature available, enabled, and component is Unlocked (allow to start)" 3 "Feature not available" 2 "Feature available, but disabled (allow to start)" ;
VAL_ 2566888001 pAntiTheft_Command_States 1 " Disable Feature" 3 "Toggle from Locked to Unlocked, or Unlocked to Locked" 0 "Enable Feature" 4 "Check Status" ;
VAL_ 2566888001 pAntiTheft_Pin_Presence 2 "Error" 0 "Off" 1 "On" 3 "Not-Available" ;
VAL_ 2365555078 pOperator_Switch_Status_3 2 "Error" 0 "Off" 1 "On" 3 "Not-Available" ;
VAL_ 2365555078 pUpPaddleStatus 2 "Error" 0 "Off" 1 "On" 3 "Not-Available" ;
VAL_ 2365555078 pOperator_Switch_Status_2 2 "Error" 0 "Off" 1 "On" 3 "Not-Available" ;
VAL_ 2365555078 pDwPaddleStatus 2 "Error" 0 "Off" 1 "On" 3 "Not-Available" ;
VAL_ 2365555078 pOperator_Button_50_Pucker 2 "Error" 0 "Off" 1 "On" 3 "Not-Available" ;
VAL_ 2566844806 pOdometer_Drive_Bit 3 "Not Available " 2 "Error" 0 "State A" 1 "State B" ;
VAL_ 2566844806 pCruise_Enable_Status 14 "Error" 15 "Not Available " 0 "Not enabled. System must be enabled before it is set" 1 "Enable. System is ready to be set by operator. Only change state when system is enabled/disabled with on/off switch" ;
VAL_ 2432656774 Key_Fob_Unlock_Button_Status 2 "Error" 0 "Off" 1 "On" 3 "Not-Available" ;
VAL_ 2432656774 Homelink_2 2 "Error" 0 "Off" 1 "On" 3 "Not-Available" ;
VAL_ 2432656774 Side_Stand_Switch 2 "Error" 0 "Off" 1 "On" 3 "Not-Available" ;
VAL_ 2432656774 Key_Fob_Lock_Button_Status 2 "Error" 0 "Off" 1 "On" 3 "Not-Available" ;
VAL_ 2432656774 Windshield__2_Down 2 "Error" 0 "Off" 1 "On" 3 "Not-Available" ;
VAL_ 2432656774 Turn__3_Cancel 2 "Error" 0 "Off" 1 "On" 3 "Not-Available" ;
VAL_ 2432656774 Reverse 2 "Error" 0 "Off" 1 "On" 3 "Not-Available" ;
VAL_ 2432656774 Hazard 2 "Error" 0 "Off" 1 "On" 3 "Not-Available" ;
VAL_ 2432656774 Homelink_1 2 "Error" 0 "Off" 1 "On" 3 "Not-Available" ;
VAL_ 2432656774 Windshield__1_Up 2 "Error" 0 "Off" 1 "On" 3 "Not-Available" ;
VAL_ 2432656774 Front_Brake_Switch 2 "Error" 0 "Off" 1 "On" 3 "Not-Available" ;
VAL_ 2432656774 Instrument_Cluster_Control__2 2 "Error" 0 "Off" 1 "On" 3 "Not-Available" ;
VAL_ 2432656774 Chassis_Unlock_Button_Status 2 "Error" 0 "Off" 1 "On" 3 "Not-Available" ;
VAL_ 2432656774 Power_Button 2 "Error" 0 "Off" 1 "On" 3 "Not-Available" ;
VAL_ 2432656774 RunStop_Switch 2 "Error" 0 "Off" 1 "On" 3 "Not-Available" ;
VAL_ 2432656774 Headlamp__2_High 2 "Error" 0 "Off" 1 "On" 3 "Not-Available" ;
VAL_ 2432656774 Instrument_Cluster_Control__1 2 "Error" 0 "Off" 1 "On" 3 "Not-Available" ;
VAL_ 2432656774 Clutch_Switch 2 "Error" 0 "Off" 1 "On" 3 "Not-Available" ;
VAL_ 2432656774 Start 2 "Error" 0 "Off" 1 "On" 3 "Not-Available" ;
VAL_ 2432656774 Headlamp__3_Driving 2 "Error" 0 "Off" 1 "On" 3 "Not-Available" ;
VAL_ 2432656774 Cruise__2_Set 2 "Error" 0 "Off" 1 "On" 3 "Not-Available" ;
VAL_ 2432656774 Windshield_Wiper 2 "Error" 0 "Off" 1 "On" 3 "Not-Available" ;
VAL_ 2432656774 Fog 2 "Error" 0 "Off" 1 "On" 3 "Not-Available" ;
VAL_ 2432656774 Cruise__3_Accel 2 "Error" 0 "Off" 1 "On" 3 "Not-Available" ;
VAL_ 2432656774 Horn 2 "Error" 0 "Off" 1 "On" 3 "Not-Available" ;
VAL_ 2432656774 Turn__2_Right 2 "Error" 0 "Off" 1 "On" 3 "Not-Available" ;
VAL_ 2432656774 Cruise__1_On 2 "Error" 0 "Off" 1 "On" 3 "Not-Available" ;
VAL_ 2432656774 Turn__1_Left 2 "Error" 0 "Off" 1 "On" 3 "Not-Available" ;
VAL_ 2432656774 Throttle_Safety_Switch__1 2 "Error" 0 "Off" 1 "On" 3 "Not-Available" ;
VAL_ 2432656774 Headlamp__1_Low 2 "Error" 0 "Off" 1 "On" 3 "Not-Available" ;
VAL_ 2432656774 Fuel_Door_Unlock_Button_Status 2 "Error Indicator" 3 "Not Available" 1 "Button pressed" 0 "Button not pressed" ;
VAL_ 2365531796 pButton1_Function 0 "No function" 4 "Drive mode toggle" 63 "N/A" 3 "Diff lock" 2 "ADC" 1 "AWD" ;
VAL_ 2365531796 pButton1_Status 2 "Error" 0 "Off" 1 "On" 3 "Not-Available" ;
VAL_ 2365531796 pButton2_Function 0 "No function" 4 "Drive mode toggle" 63 "N/A" 3 "Diff lock" 2 "ADC" 1 "AWD" ;
VAL_ 2365531796 pButton2_Status 2 "Error" 0 "Off" 1 "On" 3 "Not-Available" ;
VAL_ 2365531796 pButton3_Function 0 "No function" 4 "Drive mode toggle" 63 "N/A" 3 "Diff lock" 2 "ADC" 1 "AWD" ;
VAL_ 2365531796 pButton3_Status 2 "Error" 0 "Off" 1 "On" 3 "Not-Available" ;
VAL_ 2365531796 pButton4_Function 0 "No function" 4 "Drive mode toggle" 63 "N/A" 3 "Diff lock" 2 "ADC" 1 "AWD" ;
VAL_ 2365531796 pButton4_Status 2 "Error" 0 "Off" 1 "On" 3 "Not-Available" ;
VAL_ 2365531796 pButton5_Function 0 "No function" 4 "Drive mode toggle" 63 "N/A" 3 "Diff lock" 2 "ADC" 1 "AWD" ;
VAL_ 2365531796 pButton5_Status 2 "Error" 0 "Off" 1 "On" 3 "Not-Available" ;
VAL_ 2365531796 pRotaryKnob_Function 1 "Drive mode" 0 "No function" 31 "N/A" ;
VAL_ 2365531796 pRotaryKnob_Status 7 "N/A" 1 "Knob turned clockwise" 6 "Error" 0 "Knob inactive" 2 "Knob turned counterclockwise" ;
VAL_ 2365531155 pEPSReqMod 13 "13(0x0D) – EPS Assist Mode 4" 0 "0 (0x00) – Assist Off: all mosfet drivers are off, control motor is freely back driven." 11 "11(0x0B) – EPS Assist Mode 2" 10 "10(0x0A) – EPS Assist Mode 1" 12 "12(0x0C) – EPS Assist Mode 3" ;
VAL_ 2298428672 Engine_Operating_State 1 "Pre-Start" 3 "Warm-Up" 15 "Not Available" 4 "Running" 0 "Engine Stopped" 6 "Engine Stopping" 2 "Starting" 7 "Post-Run" 5 "Cool-down" 14 "Reserved" ;
VAL_ 2298428672 pWarmup_cycle_detection_status 1 "Warm-up cycle attained" 0 "Warm-up cycle not attained" 14 "Error" 15 "Not Available" ;
VAL_ 2298428672 pDrive_cycle_detection_status 14 "Error" 1 "Normal engine operation attained" 0 "Normal engine operation not attained" 15 "Not Available" ;
VAL_ 2298428672 pDrive_Mode 5 "Rock" 15 "Not Available" 2 "Sport" 0 "Not assigned (not used)" 4 "Tow/Haul" 3 "Comfort/Eco" 1 "Standard" 14 "Error" ;
VAL_ 2298428672 Driveline_Mode 15 "Not Available" 0 "2WD" 5 "ADC2" 4 "Ultra TURF (3WD)" 14 "Error" 1 "AWD" 3 "TURF" 2 "ADC1" 6 "ADC3" ;
VAL_ 2298414848 pPerformance_State 1 "Shutdown" 2 "Precharge" 0 "Initialize" 3 "Energized" 15 "Not Available" 5 "Fault Off" 4 "Enabled" 6 "Fault Reaction" ;
VAL_ 2365526528 pCharger_State 17 "Bulk Phase" 5 "Over Temp Shutdown" 24 "Charge Complete" 2 "Low V Shutdown" 16 "Recovery Phase" 19 "Finish Phase" 1 "High V Shutdown" 6 "Internal Fault Shutdown" 4 "Charge Timeout" 0 "Off" 26 " Equalize/Balance Charging" 20 "Reduced Performance" 31 "Not Available" 25 "Float Charging" 27 "Maintenance Charging" 3 "Check battery shutdown" 18 "Absorption Phase" ;
VAL_ 2365526528 pAC_Status 4 "220 AC, reduced power due to low V" 7 "Not Available" 2 "110 AC, reduced power due to low V" 3 "110 AC" 0 "No AC present" 1 "AC Present, voltage level not available" 6 "Error" 5 "220 AC" ;
VAL_ 2365526016 pFloat_State 2 "Error" 0 "Electrolyte Level Ok" 1 "Low Electrolyte Level Detected" 3 "Not Available" ;
VAL_ 2298415104 pController_Thermal_Cutback_Stat 0 "Inactive" 1 "Active" ;
VAL_ 2298415104 pMotor_Power_Cutback_Status 0 "Inactive" 1 "Active" ;
VAL_ 2298415104 pMotor_Thermal_Cutback_Status 0 "Inactive" 1 "Active" ;
VAL_ 2298415104 pInput_DC_Current_Cutback_Status 0 "Inactive" 1 "Active" ;
VAL_ 2298415104 pSpeed_Limit_Cutback_Status 0 "Inactive" 1 "Active" ;
VAL_ 2566895895 pAccessory_Control_Operation 0 "pAccessory Command" 255 "Not Available" 1 "pAccessory Status" ;
VAL_ 2566895895 pAccessory_Control_Mode 0 "pAccessory Off" 3 "pAccessory Setpoint 3" 2 "pAccessory Setpoint 2" 1 "pAccessory Setpoint 1" 255 "Not Available" ;
VAL_ 2566877207 pRadio_Input_Device 16 "AM" 8 "PANDORA" 11 "FM1" 12 "FM2" 9 "SIRIUS" 5 "NAV" 6 "MP3" 10 "FM" 15 "WX" 2 "XM" 13 "FM3" 3 "AUX" 1 "iPOD" 4 "USB" 7 "BT" 14 "FM4" 21 "ICOM" 19 "SW" 18 "MW" 20 "iHEART" 17 "LW" 22 "GMRS" 23 "CB" 33 "P3" 25 "GMRS RX" 35 "P5" 34 "P4" 32 "P2" 37 "P7" 24 "GMRS TX" 38 "P8" 31 "P1" 36 "P6" 40 "P10" 42 "P12" 45 "P15" 43 "P13" 39 "P9" 44 "P14" 41 "P11" 47 "P17" 50 "P20" 49 "P19" 46 "P16" 48 "P18" 92 "Incoming Text" 70 "BT VOL" 63 "Destination" 110 "BASS" 100 "Radio OFF" 80 "Thumbs UP" 91 "Incoming Call" 61 "Turn Left" 71 "BT VOL+" 72 "BT VOL-" 81 "Thumbs DOWN" 62 "Turn Right" 111 "TREBLE" 113 "BALANCE" 114 "AVC" 112 "MID" 115 "VOLUME (User Requested)" 116 "MUTE" 118 "AVC Compensated Volume " 123 "MID-BASS, + 1" 120 "MID-TREBLE" 121 "BASS, + 1" 119 "MID-BASS" 122 "MID-BASS, - 1" 117 "FADE" 128 "TREBLE, - 1" 127 "MID-TREBLE, + 1" 125 "MID, + 1" 124 "MID, - 1" 129 "TREBLE, + 1" 126 "MID-TREBLE, - 1" 130 "Number of User EQ Selection Bands" 135 "EQ Selection - Mid-Rear" 134 "EQ Selection - Rear" 133 "EQ Selection - Mid-Front" 131 "EQ Preset" 132 "EQ Selection - Front" 137 "Vehicle Configuration" 136 "BASS BOOST Setting" 254 "Error" 141 "Speakers Installed - Secondary" 249 "Request Setting" 255 "Not Available" 140 "Speakers Installed - Primary" ;
VAL_ 2566877207 pScreen_Area_Configuration 3 "Not Available" 1 "Expanded Screen Size" 2 "Error" 0 "Normal Screen Size" ;
VAL_ 2566877207 pStereo_Status 2 "Error" 0 "Off" 1 "On" 3 "Not-Available" ;
VAL_ 2566877207 pText_Line_Configuration 5 "5 lines of ASCII text being sent" 2 "2 lines of ASCII text being sent" 0 "0 lines of ASCII text being sent" 6 "6 lines of ASCII text being sent" 4 "4 lines of ASCII text being sent" 1 "1 lines of ASCII text being sent" 7 "Not Available" 3 "3 lines of ASCII text being sent" ;
VAL_ 2566877207 pHighlight_Row 15 "Not Available" 0 "No Row Highlighted" 14 "Error" ;
VAL_ 2566877207 pScreen_Area_Mode 0 "Normal Screen Display" 1 "Data List Being Transmitted" 7 "Not Available " 6 "Error" ;
VAL_ 2566877207 pFirst_Row_Configuration 0 "Data in SPN 524099, 524100, 524101 is ignored. First row will be in ASCII text" 7 "Not Available" 1 "Data in SPN 524099, 524100, 524101 will be shown in the first row" 2 "Data in SPN 524099, 524100, 524101 is ignored. First row will be blank. Row 2 is ASCII text" ;
VAL_ 2566877207 pRadio_Scaling_Of_SPN_524100 4 "-0.1/bit – show 1 decimal point, value is negative" 7 "Not Available" 2 "0.01/bit – show 2 decimal points" 1 "0.1/bit – show 1 decimal point" 6 "Do not show Input Value" 0 "1/bit" 5 "-0.01/bit – show 2 decimal points, value is negative" 3 "-1/bit – Value is negative" ;
VAL_ 2633984535 pHeated_Grip_Enable 2 "Error" 0 "Off" 1 "On" 3 "Not-Available" ;
VAL_ 2633984535 pUser_PIN_Access_Status 2 "Error" 0 "Off" 1 "On" 3 "Not-Available" ;
VAL_ 2633984535 pActive_Descent_Control_ADC_Stat 2 "Error" 0 "Off" 1 "On" 3 "Not-Available" ;
VAL_ 2633984535 pCruise_Control_Set_Status 2 "Error" 0 "Off" 1 "On" 3 "Not-Available" ;
VAL_ 2633984535 pTether_Switch_Status 2 "Error" 0 "Off" 1 "On" 3 "Not-Available" ;
VAL_ 2633984535 pHigh_Beam_Indicator_Status 2 "Error" 0 "Off" 1 "On" 3 "Not-Available" ;
VAL_ 2633984535 pLow_Fuel_Indicator_Status 2 "Error" 0 "Off" 1 "On" 3 "Not-Available" ;
VAL_ 2633984535 pSide_Stand_Status 2 "Error" 1 "Side Stand Extended" 0 "Side Stand Retracted" 3 "Not Available" ;
VAL_ 2633984535 pTurf_Mode_Requested 2 "Error" 0 "Off" 1 "On" 3 "Not-Available" ;
VAL_ 2633984535 Operator_Not_in_Operating_Statio 2 "Error" 0 "Off" 1 "On" 3 "Not-Available" ;
VAL_ 2633984535 pAWD_Mode_Requested 2 "Error" 0 "Off" 1 "On" 3 "Not-Available" ;
VAL_ 2633984535 pHeated_Grips_Up_Switch_Status 2 "Error" 0 "Off" 1 "On" 3 "Not-Available" ;
VAL_ 2633984535 pTreadle_Neutral_Status 2 "Error" 0 "Off" 1 "On" 3 "Not-Available" ;
VAL_ 2633984535 pHeated_Grips_Down_Switch_Status 2 "Error" 0 "Off" 1 "On" 3 "Not-Available" ;
VAL_ 2633984535 pPark_Brake_Indicator_Status 2 "Slow Flash (1 Hz, 50% duty cycle)" 7 "Not Available" 1 "On" 3 "Fast Flash (2 HZ or faster, 50% Duty Cycle)" 0 "Off" 6 "Error" ;
VAL_ 2633984535 pRWD_Mode_Requested 2 "Error" 0 "Off" 1 "On" 3 "Not-Available" ;
VAL_ 2633984535 pSeat_Belt_Indicator_Status 2 "Slow Flash (1 Hz, 50% duty cycle)" 7 "Not Available" 1 "On" 3 "Fast Flash (2 HZ or faster, 50% Duty Cycle)" 0 "Off" 6 "Error" ;
VAL_ 2633984535 pSecurity_Light_Immobilizer_Stat 2 "Error" 0 "Off" 1 "On" 3 "Not-Available" ;
VAL_ 2633984535 ECU_Security_Status 1 "Locked, Awaiting Unlock" 3 " Locked, system will shut down" 0 "Unlocked" 7 "Not Available" 2 "Locked, System will not shut down" 6 "Error" ;
VAL_ 2633984535 pActive_Decent_Control_ADC_Mode_ 2 "Error" 0 "Off" 1 "On" 3 "Not-Available" ;
VAL_ 2633984535 pTreadle_Reverse_Status 2 "Error" 0 "Off" 1 "On" 3 "Not-Available" ;
VAL_ 2566875159 pFuel_Type_Selected 6 "Fuel Type 1 (E85)" 1 "Fuel Type 2 (E5)" 2 "Fuel Type 3 (E7)" 7 "Fuel Type 1 (E95)" 3 "Fuel Type 4 (E10)" 15 "Not Available" 8 "Fuel Type 1 (E100)" 0 "Fuel Type 1 (E0)" 14 "Error" 4 "Fuel Type 1 (E15)" 5 "Fuel Type 1 (E20)" ;
VAL_ 2566862113 pMinEndPtSaved 2 "Error" 0 "Not Active" 3 "Not Available" 1 "Active" ;
VAL_ 2566862113 pMaxEndPtSaved 2 "Error" 0 "Not Active" 3 "Not Available" 1 "Active" ;
VAL_ 2566870416 pSaveMaxEndPt 2 "Error" 0 "Not Active" 3 "Not Available" 1 "Active" ;
VAL_ 2566870416 pSaveMinEndPt 2 "Error" 0 "Not Active" 3 "Not Available" 1 "Active" ;
VAL_ 2566870416 pEPreloadFeatureStatus 14 "Error" 2 "Sensor Not Learned" 1 "Enabled, Normal Operation" 15 "Not Available" 0 "Disabled" ;
VAL_ 2566870416 pEPreloadMovmtStatus 6 "Find End Point Failure" 7 "Save End Point Failure" 2 "Raising" 4 "Movement Requested" 3 "Target Not Reached" 14 "Error" 0 "Not Moving/No Movement Requested" 1 "Lowering" 15 "Not Available" 5 "Learning End Points" ;
VAL_ 2566870416 pEPreloadTrunkInstallStatus 0 "Disabled" 1 "Enabled" ;
VAL_ 2566872576 pBoostModeRequested 3 "pBoostMode 3 [Race]" 1 "pBoostMode 1 [Sport]" 254 "Error" 0 "Default" 255 " Not Available" 2 "pBoostMode 2 [Performance]" ;
VAL_ 2566872576 pBoostModeCommanded 3 "pBoostMode 3 [Race]" 1 "pBoostMode 1 [Sport]" 254 "Error" 0 "Default" 255 " Not Available" 2 "pBoostMode 2 [Performance]" ;
VAL_ 2566872576 pBoostModeEnablement 2 "Error" 0 "Off" 1 "On" 3 "Not-Available" ;
